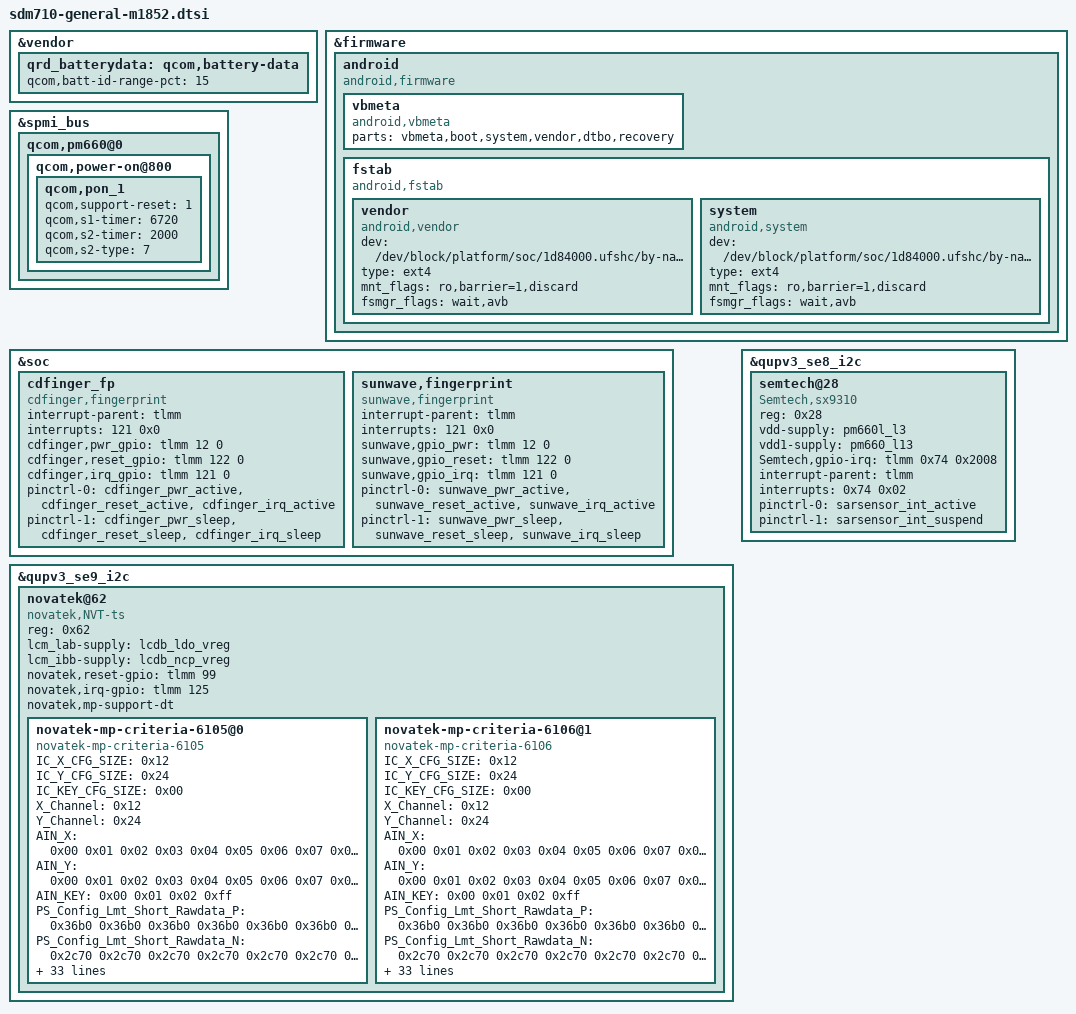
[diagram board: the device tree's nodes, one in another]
/* Copyright (c) 2017, The Linux Foundation. All rights reserved.
 * Copyright (C) 2020 Meizu, Inc.
 *
 * This program is free software; you can redistribute it and/or modify
 * it under the terms of the GNU General Public License version 2 and
 * only version 2 as published by the Free Software Foundation.
 *
 * This program is distributed in the hope that it will be useful,
 * but WITHOUT ANY WARRANTY; without even the implied warranty of
 * MERCHANTABILITY or FITNESS FOR A PARTICULAR PURPOSE.  See the
 * GNU General Public License for more details.
 */

&vendor {
	qrd_batterydata: qcom,battery-data {
		qcom,batt-id-range-pct = <15>;
		#include "batterydata-huaqin-ql1898-3210mah.dtsi"
		#include "batterydata-huaqin-ql1898-atl-3210mah.dtsi"
    }
};

&firmware {
    android {
        compatible = "android,firmware";

        vbmeta {
            compatible = "android,vbmeta";
            parts = "vbmeta,boot,system,vendor,dtbo,recovery";
        };

        fstab {
            compatible = "android,fstab";

            vendor {
                compatible = "android,vendor";
                dev = "/dev/block/platform/soc/1d84000.ufshc/by-name/vendor";
                type = "ext4";
                mnt_flags = "ro,barrier=1,discard";
                fsmgr_flags = "wait,avb";
            };

            system {
                compatible = "android,system";
                dev = "/dev/block/platform/soc/1d84000.ufshc/by-name/system";
                type = "ext4";
                mnt_flags = "ro,barrier=1,discard";
                fsmgr_flags = "wait,avb";
            };
        };
	};
}

&spmi_bus {
    qcom,pm660@0 {
        qcom,power-on@800 {
            qcom,pon_1 {
				qcom,support-reset = <1>;
				qcom,s1-timer = <6720>;
				qcom,s2-timer = <2000>;
				qcom,s2-type = <7>;
			};
        }
    }
}

&soc {
    cdfinger_fp {
        compatible = "cdfinger,fingerprint";
        interrupt-parent = <&tlmm>;
        interrupts = <121 0x0>;
        cdfinger,pwr_gpio = <&tlmm 12 0>;
        cdfinger,reset_gpio = <&tlmm 122 0>;
        cdfinger,irq_gpio = <&tlmm 121 0>;
        pinctrl-names = "cdfinger_active", "cdfinger_sleep";
        pinctrl-0 = <&cdfinger_pwr_active &cdfinger_reset_active &cdfinger_irq_active>;
        pinctrl-1 = <&cdfinger_pwr_sleep &cdfinger_reset_sleep &cdfinger_irq_sleep>;
    };

    sunwave,fingerprint {
        compatible = "sunwave,fingerprint";
        interrupt-parent = <&tlmm>;
        interrupts = <121 0x0>;
        sunwave,gpio_pwr = <&tlmm 12 0>;
        sunwave,gpio_reset = <&tlmm 122 0>;
        sunwave,gpio_irq = <&tlmm 121 0>;
        pinctrl-names = "sunwave_active", "sunwave_sleep";
        pinctrl-0 = <&sunwave_pwr_active &sunwave_reset_active &sunwave_irq_active>;
        pinctrl-1 = <&sunwave_pwr_sleep &sunwave_reset_sleep &sunwave_irq_sleep>;
	};
}

&qupv3_se9_i2c {
    status = "ok";
    novatek@62 {
            compatible = "novatek,NVT-ts";
            reg = <0x62>;
            status = "ok";
            lcm_lab-supply = <&lcdb_ldo_vreg>;
            lcm_ibb-supply = <&lcdb_ncp_vreg>;
            novatek,reset-gpio = <&tlmm 99 0>;
            novatek,irq-gpio = <&tlmm 125 0>;
            novatek,mp-support-dt;

            novatek-mp-criteria-6105@0 {
                #address-cells = <0x01>;
                #size-cells = <0x00>;
                compatible = "novatek-mp-criteria-6105";
                IC_X_CFG_SIZE = <0x12>;
                IC_Y_CFG_SIZE = <0x24>;
                IC_KEY_CFG_SIZE = <0x00>;
                X_Channel = <0x12>;
                Y_Channel = <0x24>;
                AIN_X = <0x00 0x01 0x02 0x03 0x04 0x05 0x06 0x07 0x08 0x09 0x0a 0x0b 0x0c 0x0d 0x0e 0x0f 0x10 0x11>;
                AIN_Y = <0x00 0x01 0x02 0x03 0x04 0x05 0x06 0x07 0x08 0x09 0x0a 0x0b 0x0c 0x0d 0x0e 0x0f 0x10 0x11 0x12 0x13 0x14 0x15 0x16 0x17 0x18 0x19 0x1a 0x1b 0x1c 0x1d 0x1e 0x1f 0x20 0x21 0x22 0x23>;
                AIN_KEY = <0x00 0x01 0x02 0xff>;
                PS_Config_Lmt_Short_Rawdata_P = <0x36b0 0x36b0 0x36b0 0x36b0 0x36b0 0x36b0 0x36b0 0x36b0 0x36b0 0x36b0 0x36b0 0x36b0 0x36b0 0x36b0 0x36b0 0x36b0 0x36b0 0x36b0 0x36b0 0x36b0 0x36b0 0x36b0 0x36b0 0x36b0 0x36b0 0x36b0 0x36b0 0x36b0 0x36b0 0x36b0 0x36b0 0x36b0 0x36b0 0x36b0 0x36b0 0x36b0 0x36b0 0x36b0 0x36b0 0x36b0 0x36b0 0x36b0 0x36b0 0x36b0 0x36b0 0x36b0 0x36b0 0x36b0 0x36b0 0x36b0 0x36b0 0x36b0 0x36b0 0x36b0 0x36b0 0x36b0 0x36b0 0x36b0 0x36b0 0x36b0 0x36b0 0x36b0 0x36b0 0x36b0 0x36b0 0x36b0 0x36b0 0x36b0 0x36b0 0x36b0 0x36b0 0x36b0 0x36b0 0x36b0 0x36b0 0x36b0 0x36b0 0x36b0 0x36b0 0x36b0 0x36b0 0x36b0 0x36b0 0x36b0 0x36b0 0x36b0 0x36b0 0x36b0 0x36b0 0x36b0 0x36b0 0x36b0 0x36b0 0x36b0 0x36b0 0x36b0 0x36b0 0x36b0 0x36b0 0x36b0 0x36b0 0x36b0 0x36b0 0x36b0 0x36b0 0x36b0 0x36b0 0x36b0 0x36b0 0x36b0 0x36b0 0x36b0 0x36b0 0x36b0 0x36b0 0x36b0 0x36b0 0x36b0 0x36b0 0x36b0 0x36b0 0x36b0 0x36b0 0x36b0 0x36b0 0x36b0 0x36b0 0x36b0 0x36b0 0x36b0 0x36b0 0x36b0 0x36b0 0x36b0 0x36b0 0x36b0 0x36b0 0x36b0 0x36b0 0x36b0 0x36b0 0x36b0 0x36b0 0x36b0 0x36b0 0x36b0 0x36b0 0x36b0 0x36b0 0x36b0 0x36b0 0x36b0 0x36b0 0x36b0 0x36b0 0x36b0 0x36b0 0x36b0 0x36b0 0x36b0 0x36b0 0x36b0 0x36b0 0x36b0 0x36b0 0x36b0 0x36b0 0x36b0 0x36b0 0x36b0 0x36b0 0x36b0 0x36b0 0x36b0 0x36b0 0x36b0 0x36b0 0x36b0 0x36b0 0x36b0 0x36b0 0x36b0 0x36b0 0x36b0 0x36b0 0x36b0 0x36b0 0x36b0 0x36b0 0x36b0 0x36b0 0x36b0 0x36b0 0x36b0 0x36b0 0x36b0 0x36b0 0x36b0 0x36b0 0x36b0 0x36b0 0x36b0 0x36b0 0x36b0 0x36b0 0x36b0 0x36b0 0x36b0 0x36b0 0x36b0 0x36b0 0x36b0 0x36b0 0x36b0 0x36b0 0x36b0 0x36b0 0x36b0 0x36b0 0x36b0 0x36b0 0x36b0 0x36b0 0x36b0 0x36b0 0x36b0 0x36b0 0x36b0 0x36b0 0x36b0 0x36b0 0x36b0 0x36b0 0x36b0 0x36b0 0x36b0 0x36b0 0x36b0 0x36b0 0x36b0 0x36b0 0x36b0 0x36b0 0x36b0 0x36b0 0x36b0 0x36b0 0x36b0 0x36b0 0x36b0 0x36b0 0x36b0 0x36b0 0x36b0 0x36b0 0x36b0 0x36b0 0x36b0 0x36b0 0x36b0 0x36b0 0x36b0 0x36b0 0x36b0 0x36b0 0x36b0 0x36b0 0x36b0 0x36b0 0x36b0 0x36b0 0x36b0 0x36b0 0x36b0 0x36b0 0x36b0 0x36b0 0x36b0 0x36b0 0x36b0 0x36b0 0x36b0 0x36b0 0x36b0 0x36b0 0x36b0 0x36b0 0x36b0 0x36b0 0x36b0 0x36b0 0x36b0 0x36b0 0x36b0 0x36b0 0x36b0 0x36b0 0x36b0 0x36b0 0x36b0 0x36b0 0x36b0 0x36b0 0x36b0 0x36b0 0x36b0 0x36b0 0x36b0 0x36b0 0x36b0 0x36b0 0x36b0 0x36b0 0x36b0 0x36b0 0x36b0 0x36b0 0x36b0 0x36b0 0x36b0 0x36b0 0x36b0 0x36b0 0x36b0 0x36b0 0x36b0 0x36b0 0x36b0 0x36b0 0x36b0 0x36b0 0x36b0 0x36b0 0x36b0 0x36b0 0x36b0 0x36b0 0x36b0 0x36b0 0x36b0 0x36b0 0x36b0 0x36b0 0x36b0 0x36b0 0x36b0 0x36b0 0x36b0 0x36b0 0x36b0 0x36b0 0x36b0 0x36b0 0x36b0 0x36b0 0x36b0 0x36b0 0x36b0 0x36b0 0x36b0 0x36b0 0x36b0 0x36b0 0x36b0 0x36b0 0x36b0 0x36b0 0x36b0 0x36b0 0x36b0 0x36b0 0x36b0 0x36b0 0x36b0 0x36b0 0x36b0 0x36b0 0x36b0 0x36b0 0x36b0 0x36b0 0x36b0 0x36b0 0x36b0 0x36b0 0x36b0 0x36b0 0x36b0 0x36b0 0x36b0 0x36b0 0x36b0 0x36b0 0x36b0 0x36b0 0x36b0 0x36b0 0x36b0 0x36b0 0x36b0 0x36b0 0x36b0 0x36b0 0x36b0 0x36b0 0x36b0 0x36b0 0x36b0 0x36b0 0x36b0 0x36b0 0x36b0 0x36b0 0x36b0 0x36b0 0x36b0 0x36b0 0x36b0 0x36b0 0x36b0 0x36b0 0x36b0 0x36b0 0x36b0 0x36b0 0x36b0 0x36b0 0x36b0 0x36b0 0x36b0 0x36b0 0x36b0 0x36b0 0x36b0 0x36b0 0x36b0 0x36b0 0x36b0 0x36b0 0x36b0 0x36b0 0x36b0 0x36b0 0x36b0 0x36b0 0x36b0 0x36b0 0x36b0 0x36b0 0x36b0 0x36b0 0x36b0 0x36b0 0x36b0 0x36b0 0x36b0 0x36b0 0x36b0 0x36b0 0x36b0 0x36b0 0x36b0 0x36b0 0x36b0 0x36b0 0x36b0 0x36b0 0x36b0 0x36b0 0x36b0 0x36b0 0x36b0 0x36b0 0x36b0 0x36b0 0x36b0 0x36b0 0x36b0 0x36b0 0x36b0 0x36b0 0x36b0 0x36b0 0x36b0 0x36b0 0x36b0 0x36b0 0x36b0 0x36b0 0x36b0 0x36b0 0x36b0 0x36b0 0x36b0 0x36b0 0x36b0 0x36b0 0x36b0 0x36b0 0x36b0 0x36b0 0x36b0 0x36b0 0x36b0 0x36b0 0x36b0 0x36b0 0x36b0 0x36b0 0x36b0 0x36b0 0x36b0 0x36b0 0x36b0 0x36b0 0x36b0 0x36b0 0x36b0 0x36b0 0x36b0 0x36b0 0x36b0 0x36b0 0x36b0 0x36b0 0x36b0 0x36b0 0x36b0 0x36b0 0x36b0 0x36b0 0x36b0 0x36b0 0x36b0 0x36b0 0x36b0 0x36b0 0x36b0 0x36b0 0x36b0 0x36b0 0x36b0 0x36b0 0x36b0 0x36b0 0x36b0 0x36b0 0x36b0 0x36b0 0x36b0 0x36b0 0x36b0 0x36b0 0x36b0 0x36b0 0x36b0 0x36b0 0x36b0 0x36b0 0x36b0 0x36b0 0x36b0 0x36b0 0x36b0 0x36b0 0x36b0 0x36b0 0x36b0 0x36b0 0x36b0 0x36b0 0x36b0 0x36b0 0x36b0 0x36b0 0x36b0 0x36b0 0x36b0 0x36b0 0x36b0 0x36b0 0x36b0 0x36b0 0x36b0 0x36b0 0x36b0 0x36b0 0x36b0 0x36b0 0x36b0 0x36b0 0x36b0 0x36b0 0x36b0 0x36b0 0x36b0 0x36b0 0x36b0 0x36b0 0x36b0 0x36b0 0x36b0 0x36b0 0x36b0 0x36b0 0x36b0 0x36b0 0x36b0 0x36b0 0x36b0 0x36b0 0x36b0 0x36b0 0x36b0 0x36b0 0x36b0 0x36b0 0x36b0 0x36b0 0x36b0 0x36b0 0x36b0 0x36b0 0x36b0 0x36b0 0x36b0 0x36b0 0x36b0 0x36b0 0x36b0 0x36b0 0x36b0 0x36b0 0x36b0 0x36b0 0x36b0 0x36b0 0x36b0 0x36b0 0x36b0 0x36b0 0x36b0 0x36b0 0x36b0 0x36b0 0x36b0 0x36b0 0x36b0 0x4e20 0x4e20 0x4e20>;
                PS_Config_Lmt_Short_Rawdata_N = <0x2c70 0x2c70 0x2c70 0x2c70 0x2c70 0x2c70 0x2c70 0x2c70 0x2c70 0x2c70 0x2c70 0x2c70 0x2c70 0x2c70 0x2c70 0x2c70 0x2c70 0x2c70 0x2c70 0x2c70 0x2c70 0x2c70 0x2c70 0x2c70 0x2c70 0x2c70 0x2c70 0x2c70 0x2c70 0x2c70 0x2c70 0x2c70 0x2c70 0x2c70 0x2c70 0x2c70 0x2c70 0x2c70 0x2c70 0x2c70 0x2c70 0x2c70 0x2c70 0x2c70 0x2c70 0x2c70 0x2c70 0x2c70 0x2c70 0x2c70 0x2c70 0x2c70 0x2c70 0x2c70 0x2c70 0x2c70 0x2c70 0x2c70 0x2c70 0x2c70 0x2c70 0x2c70 0x2c70 0x2c70 0x2c70 0x2c70 0x2c70 0x2c70 0x2c70 0x2c70 0x2c70 0x2c70 0x2c70 0x2c70 0x2c70 0x2c70 0x2c70 0x2c70 0x2c70 0x2c70 0x2c70 0x2c70 0x2c70 0x2c70 0x2c70 0x2c70 0x2c70 0x2c70 0x2c70 0x2c70 0x2c70 0x2c70 0x2c70 0x2c70 0x2c70 0x2c70 0x2c70 0x2c70 0x2c70 0x2c70 0x2c70 0x2c70 0x2c70 0x2c70 0x2c70 0x2c70 0x2c70 0x2c70 0x2c70 0x2c70 0x2c70 0x2c70 0x2c70 0x2c70 0x2c70 0x2c70 0x2c70 0x2c70 0x2c70 0x2c70 0x2c70 0x2c70 0x2c70 0x2c70 0x2c70 0x2c70 0x2c70 0x2c70 0x2c70 0x2c70 0x2c70 0x2c70 0x2c70 0x2c70 0x2c70 0x2c70 0x2c70 0x2c70 0x2c70 0x2c70 0x2c70 0x2c70 0x2c70 0x2c70 0x2c70 0x2c70 0x2c70 0x2c70 0x2c70 0x2c70 0x2c70 0x2c70 0x2c70 0x2c70 0x2c70 0x2c70 0x2c70 0x2c70 0x2c70 0x2c70 0x2c70 0x2c70 0x2c70 0x2c70 0x2c70 0x2c70 0x2c70 0x2c70 0x2c70 0x2c70 0x2c70 0x2c70 0x2c70 0x2c70 0x2c70 0x2c70 0x2c70 0x2c70 0x2c70 0x2c70 0x2c70 0x2c70 0x2c70 0x2c70 0x2c70 0x2c70 0x2c70 0x2c70 0x2c70 0x2c70 0x2c70 0x2c70 0x2c70 0x2c70 0x2c70 0x2c70 0x2c70 0x2c70 0x2c70 0x2c70 0x2c70 0x2c70 0x2c70 0x2c70 0x2c70 0x2c70 0x2c70 0x2c70 0x2c70 0x2c70 0x2c70 0x2c70 0x2c70 0x2c70 0x2c70 0x2c70 0x2c70 0x2c70 0x2c70 0x2c70 0x2c70 0x2c70 0x2c70 0x2c70 0x2c70 0x2c70 0x2c70 0x2c70 0x2c70 0x2c70 0x2c70 0x2c70 0x2c70 0x2c70 0x2c70 0x2c70 0x2c70 0x2c70 0x2c70 0x2c70 0x2c70 0x2c70 0x2c70 0x2c70 0x2c70 0x2c70 0x2c70 0x2c70 0x2c70 0x2c70 0x2c70 0x2c70 0x2c70 0x2c70 0x2c70 0x2c70 0x2c70 0x2c70 0x2c70 0x2c70 0x2c70 0x2c70 0x2c70 0x2c70 0x2c70 0x2c70 0x2c70 0x2c70 0x2c70 0x2c70 0x2c70 0x2c70 0x2c70 0x2c70 0x2c70 0x2c70 0x2c70 0x2c70 0x2c70 0x2c70 0x2c70 0x2c70 0x2c70 0x2c70 0x2c70 0x2c70 0x2c70 0x2c70 0x2c70 0x2c70 0x2c70 0x2c70 0x2c70 0x2c70 0x2c70 0x2c70 0x2c70 0x2c70 0x2c70 0x2c70 0x2c70 0x2c70 0x2c70 0x2c70 0x2c70 0x2c70 0x2c70 0x2c70 0x2c70 0x2c70 0x2c70 0x2c70 0x2c70 0x2c70 0x2c70 0x2c70 0x2c70 0x2c70 0x2c70 0x2c70 0x2c70 0x2c70 0x2c70 0x2c70 0x2c70 0x2c70 0x2c70 0x2c70 0x2c70 0x2c70 0x2c70 0x2c70 0x2c70 0x2c70 0x2c70 0x2c70 0x2c70 0x2c70 0x2c70 0x2c70 0x2c70 0x2c70 0x2c70 0x2c70 0x2c70 0x2c70 0x2c70 0x2c70 0x2c70 0x2c70 0x2c70 0x2c70 0x2c70 0x2c70 0x2c70 0x2c70 0x2c70 0x2c70 0x2c70 0x2c70 0x2c70 0x2c70 0x2c70 0x2c70 0x2c70 0x2c70 0x2c70 0x2c70 0x2c70 0x2c70 0x2c70 0x2c70 0x2c70 0x2c70 0x2c70 0x2c70 0x2c70 0x2c70 0x2c70 0x2c70 0x2c70 0x2c70 0x2c70 0x2c70 0x2c70 0x2c70 0x2c70 0x2c70 0x2c70 0x2c70 0x2c70 0x2c70 0x2c70 0x2c70 0x2c70 0x2c70 0x2c70 0x2c70 0x2c70 0x2c70 0x2c70 0x2c70 0x2c70 0x2c70 0x2c70 0x2c70 0x2c70 0x2c70 0x2c70 0x2c70 0x2c70 0x2c70 0x2c70 0x2c70 0x2c70 0x2c70 0x2c70 0x2c70 0x2c70 0x2c70 0x2c70 0x2c70 0x2c70 0x2c70 0x2c70 0x2c70 0x2c70 0x2c70 0x2c70 0x2c70 0x2c70 0x2c70 0x2c70 0x2c70 0x2c70 0x2c70 0x2c70 0x2c70 0x2c70 0x2c70 0x2c70 0x2c70 0x2c70 0x2c70 0x2c70 0x2c70 0x2c70 0x2c70 0x2c70 0x2c70 0x2c70 0x2c70 0x2c70 0x2c70 0x2c70 0x2c70 0x2c70 0x2c70 0x2c70 0x2c70 0x2c70 0x2c70 0x2c70 0x2c70 0x2c70 0x2c70 0x2c70 0x2c70 0x2c70 0x2c70 0x2c70 0x2c70 0x2c70 0x2c70 0x2c70 0x2c70 0x2c70 0x2c70 0x2c70 0x2c70 0x2c70 0x2c70 0x2c70 0x2c70 0x2c70 0x2c70 0x2c70 0x2c70 0x2c70 0x2c70 0x2c70 0x2c70 0x2c70 0x2c70 0x2c70 0x2c70 0x2c70 0x2c70 0x2c70 0x2c70 0x2c70 0x2c70 0x2c70 0x2c70 0x2c70 0x2c70 0x2c70 0x2c70 0x2c70 0x2c70 0x2c70 0x2c70 0x2c70 0x2c70 0x2c70 0x2c70 0x2c70 0x2c70 0x2c70 0x2c70 0x2c70 0x2c70 0x2c70 0x2c70 0x2c70 0x2c70 0x2c70 0x2c70 0x2c70 0x2c70 0x2c70 0x2c70 0x2c70 0x2c70 0x2c70 0x2c70 0x2c70 0x2c70 0x2c70 0x2c70 0x2c70 0x2c70 0x2c70 0x2c70 0x2c70 0x2c70 0x2c70 0x2c70 0x2c70 0x2c70 0x2c70 0x2c70 0x2c70 0x2c70 0x2c70 0x2c70 0x2c70 0x2c70 0x2c70 0x2c70 0x2c70 0x2c70 0x2c70 0x2c70 0x2c70 0x2c70 0x2c70 0x2c70 0x2c70 0x2c70 0x2c70 0x2c70 0x2c70 0x2c70 0x2c70 0x2c70 0x2c70 0x2c70 0x2c70 0x2c70 0x2c70 0x2c70 0x2c70 0x2c70 0x2c70 0x2c70 0x2c70 0x2c70 0x2c70 0x2c70 0x2c70 0x2c70 0x2c70 0x2c70 0x2c70 0x2c70 0x2c70 0x2c70 0x2c70 0x2c70 0x2c70 0x2c70 0x2c70 0x2c70 0x2c70 0x2c70 0x2c70 0x2c70 0x2c70 0x2c70 0x2c70 0x2c70 0x2c70 0x2c70 0x2c70 0x2c70 0x2c70 0x2c70 0x2c70 0x2c70 0x2c70 0x2c70 0x2c70 0x2c70 0x2c70 0x2c70 0x2c70 0x2c70 0x2c70 0x2c70 0x2c70 0x2c70 0x2c70 0x2c70 0x2c70 0x2c70 0x2c70 0x2c70 0x2c70 0x2c70 0x2c70 0x2c70 0x2c70 0x2c70 0x2c70 0x2c70 0x2c70 0x2c70 0x2d1e 0x2d1e 0x2d1e>;
                PS_Config_Lmt_Short_Diff_P = <0x189c 0x189c 0x189c 0x189c 0x189c 0x189c 0x189c 0x189c 0x189c 0x189c 0x189c 0x189c 0x189c 0x189c 0x189c 0x189c 0x189c 0x189c 0x189c 0x189c 0x189c 0x189c 0x189c 0x189c 0x189c 0x189c 0x189c 0x189c 0x189c 0x189c 0x189c 0x189c 0x189c 0x189c 0x189c 0x189c 0x189c 0x189c 0x189c 0x189c 0x189c 0x189c 0x189c 0x189c 0x189c 0x189c 0x189c 0x189c 0x189c 0x189c 0x189c 0x189c 0x189c 0x189c 0x189c 0x189c 0x189c 0x189c 0x189c 0x189c 0x189c 0x189c 0x189c 0x189c 0x189c 0x189c 0x189c 0x189c 0x189c 0x189c 0x189c 0x189c 0x189c 0x189c 0x189c 0x189c 0x189c 0x189c 0x189c 0x189c 0x189c 0x189c 0x189c 0x189c 0x189c 0x189c 0x189c 0x189c 0x189c 0x189c 0x189c 0x189c 0x189c 0x189c 0x189c 0x189c 0x189c 0x189c 0x189c 0x189c 0x189c 0x189c 0x189c 0x189c 0x189c 0x189c 0x189c 0x189c 0x189c 0x189c 0x189c 0x189c 0x189c 0x189c 0x189c 0x189c 0x189c 0x189c 0x189c 0x189c 0x189c 0x189c 0x189c 0x189c 0x189c 0x189c 0x189c 0x189c 0x189c 0x189c 0x189c 0x189c 0x189c 0x189c 0x189c 0x189c 0x189c 0x189c 0x189c 0x189c 0x189c 0x189c 0x189c 0x189c 0x189c 0x189c 0x189c 0x189c 0x189c 0x189c 0x189c 0x189c 0x189c 0x189c 0x189c 0x189c 0x189c 0x189c 0x189c 0x189c 0x189c 0x189c 0x189c 0x189c 0x189c 0x189c 0x189c 0x189c 0x189c 0x189c 0x189c 0x189c 0x189c 0x189c 0x189c 0x189c 0x189c 0x189c 0x189c 0x189c 0x189c 0x189c 0x189c 0x189c 0x189c 0x189c 0x189c 0x189c 0x189c 0x189c 0x189c 0x189c 0x189c 0x189c 0x189c 0x189c 0x189c 0x189c 0x189c 0x189c 0x189c 0x189c 0x189c 0x189c 0x189c 0x189c 0x189c 0x189c 0x189c 0x189c 0x189c 0x189c 0x189c 0x189c 0x189c 0x189c 0x189c 0x189c 0x189c 0x189c 0x189c 0x189c 0x189c 0x189c 0x189c 0x189c 0x189c 0x189c 0x189c 0x189c 0x189c 0x189c 0x189c 0x189c 0x189c 0x189c 0x189c 0x189c 0x189c 0x189c 0x189c 0x189c 0x189c 0x189c 0x189c 0x189c 0x189c 0x189c 0x189c 0x189c 0x189c 0x189c 0x189c 0x189c 0x189c 0x189c 0x189c 0x189c 0x189c 0x189c 0x189c 0x189c 0x189c 0x189c 0x189c 0x189c 0x189c 0x189c 0x189c 0x189c 0x189c 0x189c 0x189c 0x189c 0x189c 0x189c 0x189c 0x189c 0x189c 0x189c 0x189c 0x189c 0x189c 0x189c 0x189c 0x189c 0x189c 0x189c 0x189c 0x189c 0x189c 0x189c 0x189c 0x189c 0x189c 0x189c 0x189c 0x189c 0x189c 0x189c 0x189c 0x189c 0x189c 0x189c 0x189c 0x189c 0x189c 0x189c 0x189c 0x189c 0x189c 0x189c 0x189c 0x189c 0x189c 0x189c 0x189c 0x189c 0x189c 0x189c 0x189c 0x189c 0x189c 0x189c 0x189c 0x189c 0x189c 0x189c 0x189c 0x189c 0x189c 0x189c 0x189c 0x189c 0x189c 0x189c 0x189c 0x189c 0x189c 0x189c 0x189c 0x189c 0x189c 0x189c 0x189c 0x189c 0x189c 0x189c 0x189c 0x189c 0x189c 0x189c 0x189c 0x189c 0x189c 0x189c 0x189c 0x189c 0x189c 0x189c 0x189c 0x189c 0x189c 0x189c 0x189c 0x189c 0x189c 0x189c 0x189c 0x189c 0x189c 0x189c 0x189c 0x189c 0x189c 0x189c 0x189c 0x189c 0x189c 0x189c 0x189c 0x189c 0x189c 0x189c 0x189c 0x189c 0x189c 0x189c 0x189c 0x189c 0x189c 0x189c 0x189c 0x189c 0x189c 0x189c 0x189c 0x189c 0x189c 0x189c 0x189c 0x189c 0x189c 0x189c 0x189c 0x189c 0x189c 0x189c 0x189c 0x189c 0x189c 0x189c 0x189c 0x189c 0x189c 0x189c 0x189c 0x189c 0x189c 0x189c 0x189c 0x189c 0x189c 0x189c 0x189c 0x189c 0x189c 0x189c 0x189c 0x189c 0x189c 0x189c 0x189c 0x189c 0x189c 0x189c 0x189c 0x189c 0x189c 0x189c 0x189c 0x189c 0x189c 0x189c 0x189c 0x189c 0x189c 0x189c 0x189c 0x189c 0x189c 0x189c 0x189c 0x189c 0x189c 0x189c 0x189c 0x189c 0x189c 0x189c 0x189c 0x189c 0x189c 0x189c 0x189c 0x189c 0x189c 0x189c 0x189c 0x189c 0x189c 0x189c 0x189c 0x189c 0x189c 0x189c 0x189c 0x189c 0x189c 0x189c 0x189c 0x189c 0x189c 0x189c 0x189c 0x189c 0x189c 0x189c 0x189c 0x189c 0x189c 0x189c 0x189c 0x189c 0x189c 0x189c 0x189c 0x189c 0x189c 0x189c 0x189c 0x189c 0x189c 0x189c 0x189c 0x189c 0x189c 0x189c 0x189c 0x189c 0x189c 0x189c 0x189c 0x189c 0x189c 0x189c 0x189c 0x189c 0x189c 0x189c 0x189c 0x189c 0x189c 0x189c 0x189c 0x189c 0x189c 0x189c 0x189c 0x189c 0x189c 0x189c 0x189c 0x189c 0x189c 0x189c 0x189c 0x189c 0x189c 0x189c 0x189c 0x189c 0x189c 0x189c 0x189c 0x189c 0x189c 0x189c 0x189c 0x189c 0x189c 0x189c 0x189c 0x189c 0x189c 0x189c 0x189c 0x189c 0x189c 0x189c 0x189c 0x189c 0x189c 0x189c 0x189c 0x189c 0x189c 0x189c 0x189c 0x189c 0x189c 0x189c 0x189c 0x189c 0x189c 0x189c 0x189c 0x189c 0x189c>;
                PS_Config_Lmt_Short_Diff_N = <0x00 0x00 0x00 0x00 0x00 0x00 0x00 0x00 0x00 0x00 0x00 0x00 0x00 0x00 0x00 0x00 0x00 0x00 0x00 0x00 0x00 0x00 0x00 0x00 0x00 0x00 0x00 0x00 0x00 0x00 0x00 0x00 0x00 0x00 0x00 0x00 0x00 0x00 0x00 0x00 0x00 0x00 0x00 0x00 0x00 0x00 0x00 0x00 0x00 0x00 0x00 0x00 0x00 0x00 0x00 0x00 0x00 0x00 0x00 0x00 0x00 0x00 0x00 0x00 0x00 0x00 0x00 0x00 0x00 0x00 0x00 0x00 0x00 0x00 0x00 0x00 0x00 0x00 0x00 0x00 0x00 0x00 0x00 0x00 0x00 0x00 0x00 0x00 0x00 0x00 0x00 0x00 0x00 0x00 0x00 0x00 0x00 0x00 0x00 0x00 0x00 0x00 0x00 0x00 0x00 0x00 0x00 0x00 0x00 0x00 0x00 0x00 0x00 0x00 0x00 0x00 0x00 0x00 0x00 0x00 0x00 0x00 0x00 0x00 0x00 0x00 0x00 0x00 0x00 0x00 0x00 0x00 0x00 0x00 0x00 0x00 0x00 0x00 0x00 0x00 0x00 0x00 0x00 0x00 0x00 0x00 0x00 0x00 0x00 0x00 0x00 0x00 0x00 0x00 0x00 0x00 0x00 0x00 0x00 0x00 0x00 0x00 0x00 0x00 0x00 0x00 0x00 0x00 0x00 0x00 0x00 0x00 0x00 0x00 0x00 0x00 0x00 0x00 0x00 0x00 0x00 0x00 0x00 0x00 0x00 0x00 0x00 0x00 0x00 0x00 0x00 0x00 0x00 0x00 0x00 0x00 0x00 0x00 0x00 0x00 0x00 0x00 0x00 0x00 0x00 0x00 0x00 0x00 0x00 0x00 0x00 0x00 0x00 0x00 0x00 0x00 0x00 0x00 0x00 0x00 0x00 0x00 0x00 0x00 0x00 0x00 0x00 0x00 0x00 0x00 0x00 0x00 0x00 0x00 0x00 0x00 0x00 0x00 0x00 0x00 0x00 0x00 0x00 0x00 0x00 0x00 0x00 0x00 0x00 0x00 0x00 0x00 0x00 0x00 0x00 0x00 0x00 0x00 0x00 0x00 0x00 0x00 0x00 0x00 0x00 0x00 0x00 0x00 0x00 0x00 0x00 0x00 0x00 0x00 0x00 0x00 0x00 0x00 0x00 0x00 0x00 0x00 0x00 0x00 0x00 0x00 0x00 0x00 0x00 0x00 0x00 0x00 0x00 0x00 0x00 0x00 0x00 0x00 0x00 0x00 0x00 0x00 0x00 0x00 0x00 0x00 0x00 0x00 0x00 0x00 0x00 0x00 0x00 0x00 0x00 0x00 0x00 0x00 0x00 0x00 0x00 0x00 0x00 0x00 0x00 0x00 0x00 0x00 0x00 0x00 0x00 0x00 0x00 0x00 0x00 0x00 0x00 0x00 0x00 0x00 0x00 0x00 0x00 0x00 0x00 0x00 0x00 0x00 0x00 0x00 0x00 0x00 0x00 0x00 0x00 0x00 0x00 0x00 0x00 0x00 0x00 0x00 0x00 0x00 0x00 0x00 0x00 0x00 0x00 0x00 0x00 0x00 0x00 0x00 0x00 0x00 0x00 0x00 0x00 0x00 0x00 0x00 0x00 0x00 0x00 0x00 0x00 0x00 0x00 0x00 0x00 0x00 0x00 0x00 0x00 0x00 0x00 0x00 0x00 0x00 0x00 0x00 0x00 0x00 0x00 0x00 0x00 0x00 0x00 0x00 0x00 0x00 0x00 0x00 0x00 0x00 0x00 0x00 0x00 0x00 0x00 0x00 0x00 0x00 0x00 0x00 0x00 0x00 0x00 0x00 0x00 0x00 0x00 0x00 0x00 0x00 0x00 0x00 0x00 0x00 0x00 0x00 0x00 0x00 0x00 0x00 0x00 0x00 0x00 0x00 0x00 0x00 0x00 0x00 0x00 0x00 0x00 0x00 0x00 0x00 0x00 0x00 0x00 0x00 0x00 0x00 0x00 0x00 0x00 0x00 0x00 0x00 0x00 0x00 0x00 0x00 0x00 0x00 0x00 0x00 0x00 0x00 0x00 0x00 0x00 0x00 0x00 0x00 0x00 0x00 0x00 0x00 0x00 0x00 0x00 0x00 0x00 0x00 0x00 0x00 0x00 0x00 0x00 0x00 0x00 0x00 0x00 0x00 0x00 0x00 0x00 0x00 0x00 0x00 0x00 0x00 0x00 0x00 0x00 0x00 0x00 0x00 0x00 0x00 0x00 0x00 0x00 0x00 0x00 0x00 0x00 0x00 0x00 0x00 0x00 0x00 0x00 0x00 0x00 0x00 0x00 0x00 0x00 0x00 0x00 0x00 0x00 0x00 0x00 0x00 0x00 0x00 0x00 0x00 0x00 0x00 0x00 0x00 0x00 0x00 0x00 0x00 0x00 0x00 0x00 0x00 0x00 0x00 0x00 0x00 0x00 0x00 0x00 0x00 0x00 0x00 0x00 0x00 0x00>;
                PS_Config_Lmt_Short_Base_P = <0x7d0 0x7d0 0x7d0 0x7d0 0x7d0 0x7d0 0x7d0 0x7d0 0x7d0 0x7d0 0x7d0 0x7d0 0x7d0 0x7d0 0x7d0 0x7d0 0x7d0 0x7d0 0x7d0 0x7d0 0x7d0 0x7d0 0x7d0 0x7d0 0x7d0 0x7d0 0x7d0 0x7d0 0x7d0 0x7d0 0x7d0 0x7d0 0x7d0 0x7d0 0x7d0 0x7d0 0x7d0 0x7d0 0x7d0 0x7d0 0x7d0 0x7d0 0x7d0 0x7d0 0x7d0 0x7d0 0x7d0 0x7d0 0x7d0 0x7d0 0x7d0 0x7d0 0x7d0 0x7d0 0x7d0 0x7d0 0x7d0 0x7d0 0x7d0 0x7d0 0x7d0 0x7d0 0x7d0 0x7d0 0x7d0 0x7d0 0x7d0 0x7d0 0x7d0 0x7d0 0x7d0 0x7d0 0x7d0 0x7d0 0x7d0 0x7d0 0x7d0 0x7d0 0x7d0 0x7d0 0x7d0 0x7d0 0x7d0 0x7d0 0x7d0 0x7d0 0x7d0 0x7d0 0x7d0 0x7d0 0x7d0 0x7d0 0x7d0 0x7d0 0x7d0 0x7d0 0x7d0 0x7d0 0x7d0 0x7d0 0x7d0 0x7d0 0x7d0 0x7d0 0x7d0 0x7d0 0x7d0 0x7d0 0x7d0 0x7d0 0x7d0 0x7d0 0x7d0 0x7d0 0x7d0 0x7d0 0x7d0 0x7d0 0x7d0 0x7d0 0x7d0 0x7d0 0x7d0 0x7d0 0x7d0 0x7d0 0x7d0 0x7d0 0x7d0 0x7d0 0x7d0 0x7d0 0x7d0 0x7d0 0x7d0 0x7d0 0x7d0 0x7d0 0x7d0 0x7d0 0x7d0 0x7d0 0x7d0 0x7d0 0x7d0 0x7d0 0x7d0 0x7d0 0x7d0 0x7d0 0x7d0 0x7d0 0x7d0 0x7d0 0x7d0 0x7d0 0x7d0 0x7d0 0x7d0 0x7d0 0x7d0 0x7d0 0x7d0 0x7d0 0x7d0 0x7d0 0x7d0 0x7d0 0x7d0 0x7d0 0x7d0 0x7d0 0x7d0 0x7d0 0x7d0 0x7d0 0x7d0 0x7d0 0x7d0 0x7d0 0x7d0 0x7d0 0x7d0 0x7d0 0x7d0 0x7d0 0x7d0 0x7d0 0x7d0 0x7d0 0x7d0 0x7d0 0x7d0 0x7d0 0x7d0 0x7d0 0x7d0 0x7d0 0x7d0 0x7d0 0x7d0 0x7d0 0x7d0 0x7d0 0x7d0 0x7d0 0x7d0 0x7d0 0x7d0 0x7d0 0x7d0 0x7d0 0x7d0 0x7d0 0x7d0 0x7d0 0x7d0 0x7d0 0x7d0 0x7d0 0x7d0 0x7d0 0x7d0 0x7d0 0x7d0 0x7d0 0x7d0 0x7d0 0x7d0 0x7d0 0x7d0 0x7d0 0x7d0 0x7d0 0x7d0 0x7d0 0x7d0 0x7d0 0x7d0 0x7d0 0x7d0 0x7d0 0x7d0 0x7d0 0x7d0 0x7d0 0x7d0 0x7d0 0x7d0 0x7d0 0x7d0 0x7d0 0x7d0 0x7d0 0x7d0 0x7d0 0x7d0 0x7d0 0x7d0 0x7d0 0x7d0 0x7d0 0x7d0 0x7d0 0x7d0 0x7d0 0x7d0 0x7d0 0x7d0 0x7d0 0x7d0 0x7d0 0x7d0 0x7d0 0x7d0 0x7d0 0x7d0 0x7d0 0x7d0 0x7d0 0x7d0 0x7d0 0x7d0 0x7d0 0x7d0 0x7d0 0x7d0 0x7d0 0x7d0 0x7d0 0x7d0 0x7d0 0x7d0 0x7d0 0x7d0 0x7d0 0x7d0 0x7d0 0x7d0 0x7d0 0x7d0 0x7d0 0x7d0 0x7d0 0x7d0 0x7d0 0x7d0 0x7d0 0x7d0 0x7d0 0x7d0 0x7d0 0x7d0 0x7d0 0x7d0 0x7d0 0x7d0 0x7d0 0x7d0 0x7d0 0x7d0 0x7d0 0x7d0 0x7d0 0x7d0 0x7d0 0x7d0 0x7d0 0x7d0 0x7d0 0x7d0 0x7d0 0x7d0 0x7d0 0x7d0 0x7d0 0x7d0 0x7d0 0x7d0 0x7d0 0x7d0 0x7d0 0x7d0 0x7d0 0x7d0 0x7d0 0x7d0 0x7d0 0x7d0 0x7d0 0x7d0 0x7d0 0x7d0 0x7d0 0x7d0 0x7d0 0x7d0 0x7d0 0x7d0 0x7d0 0x7d0 0x7d0 0x7d0 0x7d0 0x7d0 0x7d0 0x7d0 0x7d0 0x7d0 0x7d0 0x7d0 0x7d0 0x7d0 0x7d0 0x7d0 0x7d0 0x7d0 0x7d0 0x7d0 0x7d0 0x7d0 0x7d0 0x7d0 0x7d0 0x7d0 0x7d0 0x7d0 0x7d0 0x7d0 0x7d0 0x7d0 0x7d0 0x7d0 0x7d0 0x7d0 0x7d0 0x7d0 0x7d0 0x7d0 0x7d0 0x7d0 0x7d0 0x7d0 0x7d0 0x7d0 0x7d0 0x7d0 0x7d0 0x7d0 0x7d0 0x7d0 0x7d0 0x7d0 0x7d0 0x7d0 0x7d0 0x7d0 0x7d0 0x7d0 0x7d0 0x7d0 0x7d0 0x7d0 0x7d0 0x7d0 0x7d0 0x7d0 0x7d0 0x7d0 0x7d0 0x7d0 0x7d0 0x7d0 0x7d0 0x7d0 0x7d0 0x7d0 0x7d0 0x7d0 0x7d0 0x7d0 0x7d0 0x7d0 0x7d0 0x7d0 0x7d0 0x7d0 0x7d0 0x7d0 0x7d0 0x7d0 0x7d0 0x7d0 0x7d0 0x7d0 0x7d0 0x7d0 0x7d0 0x7d0 0x7d0 0x7d0 0x7d0 0x7d0 0x7d0 0x7d0 0x7d0 0x7d0 0x7d0 0x7d0 0x7d0 0x7d0 0x7d0 0x7d0 0x7d0 0x7d0 0x7d0 0x7d0 0x7d0 0x7d0 0x7d0 0x7d0 0x7d0 0x7d0 0x7d0 0x7d0 0x7d0 0x7d0 0x7d0 0x7d0 0x7d0 0x7d0 0x7d0 0x7d0 0x7d0 0x7d0 0x7d0 0x7d0 0x7d0 0x7d0 0x7d0 0x7d0 0x7d0 0x7d0 0x7d0 0x7d0 0x7d0 0x7d0 0x7d0 0x7d0 0x7d0 0x7d0 0x7d0 0x7d0 0x7d0 0x7d0 0x7d0 0x7d0 0x7d0 0x7d0 0x7d0 0x7d0 0x7d0 0x7d0 0x7d0 0x7d0 0x7d0 0x7d0 0x7d0 0x7d0 0x7d0 0x7d0 0x7d0 0x7d0 0x7d0 0x7d0 0x7d0 0x7d0 0x7d0 0x7d0 0x7d0 0x7d0 0x7d0 0x7d0 0x7d0 0x7d0 0x7d0 0x7d0 0x7d0 0x7d0 0x7d0 0x7d0 0x7d0 0x7d0 0x7d0 0x7d0 0x7d0 0x7d0 0x7d0 0x7d0 0x7d0 0x7d0 0x7d0 0x7d0 0x7d0 0x7d0 0x7d0 0x7d0 0x7d0 0x7d0 0x7d0 0x7d0 0x7d0 0x7d0 0x7d0 0x7d0 0x7d0 0x7d0 0x7d0 0x7d0>;
                PS_Config_Lmt_Short_Base_N = <0xfffff830 0xfffff830 0xfffff830 0xfffff830 0xfffff830 0xfffff830 0xfffff830 0xfffff830 0xfffff830 0xfffff830 0xfffff830 0xfffff830 0xfffff830 0xfffff830 0xfffff830 0xfffff830 0xfffff830 0xfffff830 0xfffff830 0xfffff830 0xfffff830 0xfffff830 0xfffff830 0xfffff830 0xfffff830 0xfffff830 0xfffff830 0xfffff830 0xfffff830 0xfffff830 0xfffff830 0xfffff830 0xfffff830 0xfffff830 0xfffff830 0xfffff830 0xfffff830 0xfffff830 0xfffff830 0xfffff830 0xfffff830 0xfffff830 0xfffff830 0xfffff830 0xfffff830 0xfffff830 0xfffff830 0xfffff830 0xfffff830 0xfffff830 0xfffff830 0xfffff830 0xfffff830 0xfffff830 0xfffff830 0xfffff830 0xfffff830 0xfffff830 0xfffff830 0xfffff830 0xfffff830 0xfffff830 0xfffff830 0xfffff830 0xfffff830 0xfffff830 0xfffff830 0xfffff830 0xfffff830 0xfffff830 0xfffff830 0xfffff830 0xfffff830 0xfffff830 0xfffff830 0xfffff830 0xfffff830 0xfffff830 0xfffff830 0xfffff830 0xfffff830 0xfffff830 0xfffff830 0xfffff830 0xfffff830 0xfffff830 0xfffff830 0xfffff830 0xfffff830 0xfffff830 0xfffff830 0xfffff830 0xfffff830 0xfffff830 0xfffff830 0xfffff830 0xfffff830 0xfffff830 0xfffff830 0xfffff830 0xfffff830 0xfffff830 0xfffff830 0xfffff830 0xfffff830 0xfffff830 0xfffff830 0xfffff830 0xfffff830 0xfffff830 0xfffff830 0xfffff830 0xfffff830 0xfffff830 0xfffff830 0xfffff830 0xfffff830 0xfffff830 0xfffff830 0xfffff830 0xfffff830 0xfffff830 0xfffff830 0xfffff830 0xfffff830 0xfffff830 0xfffff830 0xfffff830 0xfffff830 0xfffff830 0xfffff830 0xfffff830 0xfffff830 0xfffff830 0xfffff830 0xfffff830 0xfffff830 0xfffff830 0xfffff830 0xfffff830 0xfffff830 0xfffff830 0xfffff830 0xfffff830 0xfffff830 0xfffff830 0xfffff830 0xfffff830 0xfffff830 0xfffff830 0xfffff830 0xfffff830 0xfffff830 0xfffff830 0xfffff830 0xfffff830 0xfffff830 0xfffff830 0xfffff830 0xfffff830 0xfffff830 0xfffff830 0xfffff830 0xfffff830 0xfffff830 0xfffff830 0xfffff830 0xfffff830 0xfffff830 0xfffff830 0xfffff830 0xfffff830 0xfffff830 0xfffff830 0xfffff830 0xfffff830 0xfffff830 0xfffff830 0xfffff830 0xfffff830 0xfffff830 0xfffff830 0xfffff830 0xfffff830 0xfffff830 0xfffff830 0xfffff830 0xfffff830 0xfffff830 0xfffff830 0xfffff830 0xfffff830 0xfffff830 0xfffff830 0xfffff830 0xfffff830 0xfffff830 0xfffff830 0xfffff830 0xfffff830 0xfffff830 0xfffff830 0xfffff830 0xfffff830 0xfffff830 0xfffff830 0xfffff830 0xfffff830 0xfffff830 0xfffff830 0xfffff830 0xfffff830 0xfffff830 0xfffff830 0xfffff830 0xfffff830 0xfffff830 0xfffff830 0xfffff830 0xfffff830 0xfffff830 0xfffff830 0xfffff830 0xfffff830 0xfffff830 0xfffff830 0xfffff830 0xfffff830 0xfffff830 0xfffff830 0xfffff830 0xfffff830 0xfffff830 0xfffff830 0xfffff830 0xfffff830 0xfffff830 0xfffff830 0xfffff830 0xfffff830 0xfffff830 0xfffff830 0xfffff830 0xfffff830 0xfffff830 0xfffff830 0xfffff830 0xfffff830 0xfffff830 0xfffff830 0xfffff830 0xfffff830 0xfffff830 0xfffff830 0xfffff830 0xfffff830 0xfffff830 0xfffff830 0xfffff830 0xfffff830 0xfffff830 0xfffff830 0xfffff830 0xfffff830 0xfffff830 0xfffff830 0xfffff830 0xfffff830 0xfffff830 0xfffff830 0xfffff830 0xfffff830 0xfffff830 0xfffff830 0xfffff830 0xfffff830 0xfffff830 0xfffff830 0xfffff830 0xfffff830 0xfffff830 0xfffff830 0xfffff830 0xfffff830 0xfffff830 0xfffff830 0xfffff830 0xfffff830 0xfffff830 0xfffff830 0xfffff830 0xfffff830 0xfffff830 0xfffff830 0xfffff830 0xfffff830 0xfffff830 0xfffff830 0xfffff830 0xfffff830 0xfffff830 0xfffff830 0xfffff830 0xfffff830 0xfffff830 0xfffff830 0xfffff830 0xfffff830 0xfffff830 0xfffff830 0xfffff830 0xfffff830 0xfffff830 0xfffff830 0xfffff830 0xfffff830 0xfffff830 0xfffff830 0xfffff830 0xfffff830 0xfffff830 0xfffff830 0xfffff830 0xfffff830 0xfffff830 0xfffff830 0xfffff830 0xfffff830 0xfffff830 0xfffff830 0xfffff830 0xfffff830 0xfffff830 0xfffff830 0xfffff830 0xfffff830 0xfffff830 0xfffff830 0xfffff830 0xfffff830 0xfffff830 0xfffff830 0xfffff830 0xfffff830 0xfffff830 0xfffff830 0xfffff830 0xfffff830 0xfffff830 0xfffff830 0xfffff830 0xfffff830 0xfffff830 0xfffff830 0xfffff830 0xfffff830 0xfffff830 0xfffff830 0xfffff830 0xfffff830 0xfffff830 0xfffff830 0xfffff830 0xfffff830 0xfffff830 0xfffff830 0xfffff830 0xfffff830 0xfffff830 0xfffff830 0xfffff830 0xfffff830 0xfffff830 0xfffff830 0xfffff830 0xfffff830 0xfffff830 0xfffff830 0xfffff830 0xfffff830 0xfffff830 0xfffff830 0xfffff830 0xfffff830 0xfffff830 0xfffff830 0xfffff830 0xfffff830 0xfffff830 0xfffff830 0xfffff830 0xfffff830 0xfffff830 0xfffff830 0xfffff830 0xfffff830 0xfffff830 0xfffff830 0xfffff830 0xfffff830 0xfffff830 0xfffff830 0xfffff830 0xfffff830 0xfffff830 0xfffff830 0xfffff830 0xfffff830 0xfffff830 0xfffff830 0xfffff830 0xfffff830 0xfffff830 0xfffff830 0xfffff830 0xfffff830 0xfffff830 0xfffff830 0xfffff830 0xfffff830 0xfffff830 0xfffff830 0xfffff830 0xfffff830 0xfffff830 0xfffff830 0xfffff830 0xfffff830 0xfffff830 0xfffff830 0xfffff830 0xfffff830 0xfffff830 0xfffff830 0xfffff830 0xfffff830 0xfffff830 0xfffff830 0xfffff830 0xfffff830 0xfffff830 0xfffff830 0xfffff830 0xfffff830 0xfffff830 0xfffff830 0xfffff830 0xfffff830 0xfffff830 0xfffff830 0xfffff830 0xfffff830 0xfffff830 0xfffff830 0xfffff830 0xfffff830 0xfffff830 0xfffff830 0xfffff830 0xfffff830 0xfffff830 0xfffff830 0xfffff830 0xfffff830 0xfffff830 0xfffff830 0xfffff830 0xfffff830 0xfffff830 0xfffff830 0xfffff830 0xfffff830 0xfffff830 0xfffff830 0xfffff830 0xfffff830 0xfffff830 0xfffff830 0xfffff830 0xfffff830 0xfffff830 0xfffff830 0xfffff830 0xfffff830 0xfffff830 0xfffff830 0xfffff830 0xfffff830 0xfffff830 0xfffff830 0xfffff830 0xfffff830 0xfffff830 0xfffff830 0xfffff830 0xfffff830 0xfffff830 0xfffff830 0xfffff830 0xfffff830 0xfffff830 0xfffff830 0xfffff830 0xfffff830 0xfffff830 0xfffff830 0xfffff830 0xfffff830 0xfffff830 0xfffff830 0xfffff830 0xfffff830 0xfffff830 0xfffff830 0xfffff830 0xfffff830 0xfffff830 0xfffff830 0xfffff830 0xfffff830 0xfffff830 0xfffff830 0xfffff830 0xfffff830 0xfffff830 0xfffff830 0xfffff830 0xfffff830 0xfffff830 0xfffff830 0xfffff830 0xfffff830 0xfffff830 0xfffff830 0xfffff830 0xfffff830 0xfffff830 0xfffff830 0xfffff830 0xfffff830 0xfffff830 0xfffff830 0xfffff830 0xfffff830 0xfffff830 0xfffff830 0xfffff830 0xfffff830 0xfffff830 0xfffff830 0xfffff830 0xfffff830 0xfffff830 0xfffff830 0xfffff830 0xfffff830 0xfffff830 0xfffff830 0xfffff830 0xfffff830 0xfffff830 0xfffff830 0xfffff830 0xfffff830 0xfffff830 0xfffff830 0xfffff830 0xfffff830 0xfffff830 0xfffff830 0xfffff830 0xfffff830 0xfffff830 0xfffff830 0xfffff830 0xfffff830 0xfffff830 0xfffff830 0xfffff830>;
                PS_Config_Lmt_Open_Rawdata_P = <0x12f8 0x1177 0xf32 0xcd9 0xb1a 0xffff 0xffff 0xffff 0xffff 0xffff 0xffff 0xffff 0xffff 0xa5c 0xc3b 0xe97 0x10e2 0x127e 0x988 0xc02 0xbcd 0xb71 0xb43 0xd7b 0xbb2 0xbb1 0xba2 0xb7e 0xb93 0xb98 0xd46 0xc07 0xc36 0xc92 0xccd 0x9d5 0xb0a 0xbd8 0xbc3 0xb8a 0xb7a 0xb60 0xb61 0xb69 0xb5b 0xb3b 0xb54 0xb53 0xb59 0xb73 0xb85 0xbc6 0xbe2 0xb4c 0xaad 0xbc3 0xbb9 0xb80 0xb73 0xb6d 0xb6f 0xb77 0xb69 0xb5b 0xb5c 0xb66 0xb69 0xb70 0xb83 0xbc1 0xbdf 0xade 0xaa7 0xbdd 0xbc6 0xb8d 0xb77 0xb4b 0xb50 0xb58 0xb4d 0xb3f 0xb4b 0xb4a 0xb4d 0xb80 0xb94 0xbd4 0xbef 0xae0 0xaad 0xbb7 0xb94 0xb68 0xb43 0xb3e 0xb44 0xb4d 0xb42 0xb34 0xb3f 0xb30 0xb3f 0xb49 0xb76 0xbb4 0xbd0 0xaee 0xa89 0xba8 0xb8b 0xb58 0xb33 0xb35 0xb3a 0xb42 0xb38 0xb23 0xb2f 0xb2d 0xb2e 0xb3b 0xb66 0xba5 0xbbf 0xad0 0xa7b 0xb9e 0xb6f 0xb41 0xb27 0xb3a 0xb40 0xb45 0xb3d 0xb2c 0xb36 0xb37 0xb2b 0xb2a 0xb54 0xb7f 0xbad 0xac0 0xa73 0xba5 0xb75 0xb52 0xb2b 0xb2c 0xb34 0xb38 0xb32 0xb26 0xb2f 0xb35 0xb34 0xb2f 0xb57 0xb7c 0xbaf 0xaa8 0xa73 0xb95 0xb65 0xb2d 0xb11 0xb3d 0xb47 0xb4a 0xb45 0xb2b 0xb34 0xb3b 0xb38 0xb1d 0xb41 0xb77 0xbab 0xaab 0xa62 0xba5 0xb76 0xb3e 0xb2f 0xb14 0xb27 0xb2e 0xb29 0xb05 0xb11 0xb13 0xb10 0xb2b 0xb31 0xb79 0xbac 0xaa6 0xa6d 0xb82 0xb54 0xb1b 0xb0f 0xafc 0xb04 0xb0c 0xb0b 0xaef 0xafa 0xafd 0xafb 0xb02 0xb14 0xb50 0xb84 0xaa4 0xa4a 0xb5a 0xb30 0xafa 0xaea 0xaea 0xae4 0xaf9 0xafa 0xad6 0xae4 0xae5 0xae4 0xaee 0xb01 0xb30 0xb6e 0xa7a 0xa23 0xb35 0xb1e 0xae5 0xad7 0xadc 0xae3 0xaeb 0xaed 0xada 0xaeb 0xae9 0xae7 0xad5 0xae8 0xb22 0xb41 0xa5c 0xa0e 0xb27 0xafc 0xadb 0xaca 0xad0 0xad8 0xad0 0xae1 0xacc 0xae0 0xae1 0xade 0xad5 0xae8 0xb11 0xb2f 0xa40 0x9fc 0xb18 0xaec 0xac9 0xaba 0xabf 0xac6 0xacc 0xacd 0xaa7 0xab7 0xabb 0xab6 0xac9 0xad9 0xb00 0xb2e 0xa3a 0x9e9 0xb04 0xad8 0xab6 0xaa6 0xaa0 0xaab 0xab0 0xaa7 0xaaa 0xabf 0xac0 0xaba 0xaa0 0xab1 0xad6 0xb04 0xa1d 0x9d3 0xae5 0xab8 0xa95 0xa88 0xa86 0xa8f 0xa90 0xa96 0xa86 0xa94 0xa98 0xa94 0xaa6 0xab5 0xada 0xb0a 0x9ff 0x9b0 0xac2 0xa9d 0xa7a 0xa69 0xa7d 0xa86 0xa8a 0xa8e 0xa66 0xa78 0xa76 0xa75 0xa7f 0xa8e 0xab3 0xae2 0x9fe 0x97a 0xaa9 0xa92 0xa6e 0xa5f 0xa65 0xa6e 0xa75 0xa75 0xa4f 0xa6d 0xa6b 0xa6b 0xa5e 0xa6c 0xa93 0xab2 0x9d6 0x984 0xa8f 0xa79 0xa57 0xa49 0xa42 0xa48 0xa4e 0xa53 0xa59 0xa5c 0xa5a 0xa5a 0xa4e 0xa5f 0xa85 0xa9f 0x9b0 0x96b 0xa57 0xa51 0xa31 0xa24 0xa2d 0xa35 0xa3a 0xa3e 0xa3b 0xa30 0xa43 0xa3d 0xa3f 0xa50 0xa76 0xa90 0x9a1 0x942 0xa56 0xa3d 0xa1d 0xa10 0xa1b 0xa22 0xa26 0xa2c 0xa1e 0xa29 0xa24 0xa20 0xa24 0xa35 0xa5c 0xa75 0x98e 0x92a 0xa41 0xa17 0xa06 0x9fb 0x9f3 0x9ff 0xa00 0xa07 0x9fa 0xa05 0x9f1 0x9fb 0xa07 0xa18 0xa40 0xa58 0x96c 0x912 0xa1a 0xa01 0x9dc 0x9d2 0x9cf 0x9dc 0x9df 0x9e3 0x9de 0x9ee 0x9ea 0x9e0 0x9e0 0x9f1 0xa19 0xa30 0x948 0x8e8 0x9fb 0x9e2 0x9ae 0x9b0 0x9c4 0x9d1 0x9d8 0x9d1 0x9d0 0x9e3 0x9de 0x9c5 0x9c3 0x9d4 0x9fa 0xa13 0x91e 0x8c4 0x9ee 0x9d8 0x9b1 0x996 0x9c2 0x9cc 0x9d6 0x9cf 0x9c9 0x9e5 0x9dd 0x9d7 0x9a6 0x9c2 0x9ed 0xa04 0x8ff 0x8b0 0x9e9 0x9d2 0x9ad 0x9a1 0x993 0x99c 0x9a3 0x990 0x98f 0x9aa 0x9a0 0x99b 0x9b6 0x9c1 0x9ed 0xa04 0x8ee 0x8a6 0x9b7 0x9a3 0x97c 0x972 0x95d 0x975 0x97d 0x967 0x979 0x98e 0x98e 0x988 0x97a 0x97a 0x9b1 0x9c6 0x8e6 0x873 0x990 0x978 0x954 0x949 0x940 0x94c 0x952 0x93f 0x956 0x968 0x967 0x95e 0x969 0x975 0x99b 0x9b2 0x8a6 0x846 0x966 0x94e 0x92b 0x91e 0x920 0x921 0x933 0x91f 0x92b 0x940 0x93e 0x934 0x93d 0x94b 0x964 0x989 0x88c 0x818 0x948 0x92e 0x90b 0x8fb 0x917 0x924 0x928 0x911 0x91e 0x939 0x934 0x929 0x90e 0x91f 0x944 0x95c 0x85f 0x7fc 0x930 0x919 0x8f5 0x8e4 0x902 0x910 0x913 0x8ff 0x91a 0x939 0x931 0x921 0x8fc 0x90f 0x933 0x947 0x832 0x7df 0x920 0x908 0x8e2 0x8d2 0x8db 0x8ee 0x8f4 0x8d8 0x8e0 0x8ff 0x8f2 0x8e2 0x8f9 0x909 0x930 0x94a 0x818 0x78c 0x94d 0x90c 0x8be 0x8ae 0x8c1 0x8d6 0x8dc 0x8be 0x8d2 0x8f4 0x8e9 0x8d8 0x8bd 0x8cf 0x91c 0x95e 0x7dd 0xc8b 0xaf2 0x7f6 0x8df 0x8cf 0xa26 0xa38 0xa38 0xa15 0x94c 0x971 0x96e 0x95a 0x8e9 0x8fa 0x818 0xb3e 0xcff 0x32c8 0x32c8 0x32c8>;
                PS_Config_Lmt_Open_Rawdata_N = <0x821 0x77c 0x683 0x582 0x4c2 0x00 0x00 0x00 0x00 0x00 0x00 0x00 0x00 0x470 0x53e 0x641 0x73c 0x7ed 0x497 0x5c8 0x5af 0x582 0x56c 0x67e 0x5a1 0x5a1 0x59a 0x589 0x593 0x595 0x664 0x5ca 0x5e1 0x60d 0x62a 0x4bc 0x550 0x5b4 0x5aa 0x58e 0x587 0x57a 0x57a 0x57e 0x578 0x568 0x574 0x574 0x577 0x583 0x58c 0x5ab 0x5b8 0x571 0x524 0x5aa 0x5a5 0x589 0x583 0x580 0x582 0x585 0x57f 0x578 0x578 0x57d 0x57f 0x582 0x58b 0x5a9 0x5b7 0x53c 0x521 0x5b6 0x5ab 0x590 0x585 0x570 0x572 0x576 0x571 0x56a 0x570 0x56f 0x571 0x58a 0x593 0x5b2 0x5bf 0x53c 0x524 0x5a4 0x593 0x57e 0x56c 0x56a 0x56d 0x571 0x56c 0x565 0x56a 0x563 0x56a 0x56f 0x585 0x5a3 0x5b0 0x543 0x512 0x59d 0x58f 0x576 0x564 0x565 0x568 0x56c 0x567 0x55d 0x562 0x562 0x562 0x568 0x57d 0x59b 0x5a8 0x535 0x50c 0x598 0x581 0x56b 0x55f 0x568 0x56b 0x56d 0x569 0x561 0x566 0x567 0x561 0x560 0x574 0x589 0x59f 0x52d 0x508 0x59b 0x584 0x573 0x560 0x561 0x565 0x567 0x564 0x55e 0x563 0x565 0x565 0x562 0x576 0x588 0x5a0 0x521 0x508 0x594 0x57d 0x561 0x554 0x569 0x56e 0x56f 0x56d 0x561 0x565 0x568 0x567 0x55a 0x56b 0x585 0x59e 0x523 0x500 0x59b 0x585 0x56a 0x563 0x555 0x55e 0x562 0x560 0x54e 0x554 0x555 0x554 0x560 0x563 0x586 0x59f 0x520 0x505 0x58b 0x574 0x559 0x553 0x54a 0x54e 0x552 0x551 0x544 0x549 0x54a 0x549 0x54d 0x555 0x573 0x58b 0x520 0x4f4 0x577 0x563 0x549 0x541 0x541 0x53e 0x549 0x549 0x538 0x53e 0x53f 0x53e 0x543 0x54c 0x563 0x581 0x50b 0x4e1 0x565 0x55a 0x53f 0x538 0x53a 0x53e 0x542 0x543 0x539 0x542 0x541 0x540 0x537 0x540 0x55c 0x56b 0x4fd 0x4d7 0x55f 0x54a 0x53a 0x532 0x535 0x538 0x535 0x53d 0x533 0x53c 0x53d 0x53b 0x537 0x540 0x554 0x563 0x4ef 0x4ce 0x557 0x542 0x531 0x52a 0x52c 0x530 0x533 0x533 0x521 0x529 0x52b 0x528 0x531 0x539 0x54c 0x562 0x4ed 0x4c6 0x54e 0x539 0x528 0x520 0x51e 0x523 0x526 0x521 0x522 0x52c 0x52d 0x52a 0x51e 0x526 0x538 0x54e 0x4de 0x4bb 0x53f 0x529 0x518 0x512 0x511 0x515 0x516 0x519 0x511 0x518 0x51a 0x518 0x520 0x528 0x53a 0x551 0x4d0 0x4aa 0x52e 0x51c 0x50b 0x503 0x50d 0x511 0x513 0x515 0x501 0x50a 0x50a 0x509 0x50e 0x515 0x527 0x53d 0x4cf 0x490 0x522 0x517 0x506 0x4fe 0x501 0x506 0x509 0x509 0x4f7 0x505 0x504 0x504 0x4fe 0x505 0x517 0x526 0x4bc 0x495 0x515 0x50b 0x4fa 0x4f4 0x4f0 0x4f3 0x4f6 0x4f9 0x4fb 0x4fd 0x4fc 0x4fc 0x4f6 0x4fe 0x511 0x51d 0x4aa 0x489 0x4fa 0x4f8 0x4e8 0x4e2 0x4e6 0x4ea 0x4ec 0x4ef 0x4ed 0x4e8 0x4f1 0x4ee 0x4ef 0x4f7 0x509 0x516 0x4a3 0x475 0x4fa 0x4ee 0x4de 0x4d8 0x4dd 0x4e1 0x4e3 0x4e6 0x4df 0x4e4 0x4e2 0x4e0 0x4e2 0x4ea 0x4fd 0x509 0x49a 0x469 0x4f0 0x4dc 0x4d3 0x4ce 0x4ca 0x4d0 0x4d1 0x4d4 0x4ce 0x4d3 0x4c9 0x4ce 0x4d4 0x4dc 0x4ef 0x4fb 0x489 0x45e 0x4dd 0x4d1 0x4bf 0x4bb 0x4b9 0x4bf 0x4c1 0x4c2 0x4c0 0x4c8 0x4c6 0x4c1 0x4c1 0x4c9 0x4dc 0x4e8 0x478 0x44a 0x4ce 0x4c2 0x4a9 0x4aa 0x4b4 0x4ba 0x4bd 0x4ba 0x4b9 0x4c3 0x4c0 0x4b4 0x4b3 0x4bb 0x4ce 0x4da 0x464 0x438 0x4c8 0x4bd 0x4ab 0x49d 0x4b3 0x4b8 0x4bc 0x4b9 0x4b6 0x4c4 0x4c0 0x4bd 0x4a5 0x4b3 0x4c7 0x4d2 0x455 0x42f 0x4c5 0x4ba 0x4a9 0x4a3 0x49c 0x4a0 0x4a4 0x49b 0x49a 0x4a7 0x4a2 0x4a0 0x4ad 0x4b2 0x4c7 0x4d3 0x44c 0x42a 0x4ae 0x4a4 0x491 0x48c 0x482 0x48e 0x491 0x487 0x490 0x49a 0x49a 0x497 0x490 0x490 0x4ab 0x4b5 0x449 0x411 0x49b 0x48f 0x47e 0x479 0x474 0x47a 0x47d 0x474 0x47f 0x487 0x487 0x482 0x488 0x48d 0x4a0 0x4ab 0x42a 0x3fc 0x486 0x47b 0x46a 0x464 0x465 0x465 0x46e 0x464 0x46a 0x474 0x473 0x46e 0x473 0x47a 0x485 0x497 0x41d 0x3e6 0x478 0x46b 0x45a 0x453 0x460 0x467 0x469 0x45e 0x464 0x471 0x46e 0x469 0x45c 0x464 0x476 0x482 0x408 0x3d8 0x46d 0x461 0x450 0x448 0x456 0x45d 0x45e 0x455 0x462 0x471 0x46d 0x465 0x454 0x45d 0x46e 0x478 0x3f2 0x3ca 0x465 0x459 0x447 0x43f 0x443 0x44c 0x450 0x442 0x446 0x455 0x44e 0x447 0x452 0x45a 0x46c 0x479 0x3e6 0x3a2 0x47b 0x45b 0x436 0x42e 0x437 0x441 0x444 0x436 0x43f 0x450 0x44a 0x442 0x435 0x43e 0x463 0x483 0x3c9 0x60a 0x545 0x3d5 0x445 0x43e 0x4e3 0x4eb 0x4ec 0x4db 0x47a 0x48c 0x48a 0x481 0x44a 0x453 0x3e5 0x56a 0x642 0x64 0x64 0x64>;
                PS_Config_Lmt_FW_Rawdata_P = <0x6a4 0x6a4 0x6a4 0x6a4 0x6a4 0xffff 0xffff 0xffff 0xffff 0xffff 0xffff 0xffff 0xffff 0x6a4 0x6a4 0x6a4 0x6a4 0x6a4 0x6a4 0x6a4 0x6a4 0x6a4 0x6a4 0x6a4 0x6a4 0x6a4 0x6a4 0x6a4 0x6a4 0x6a4 0x6a4 0x6a4 0x6a4 0x6a4 0x6a4 0x6a4 0x6a4 0x6a4 0x6a4 0x6a4 0x6a4 0x6a4 0x6a4 0x6a4 0x6a4 0x6a4 0x6a4 0x6a4 0x6a4 0x6a4 0x6a4 0x6a4 0x6a4 0x6a4 0x6a4 0x6a4 0x6a4 0x6a4 0x6a4 0x6a4 0x6a4 0x6a4 0x6a4 0x6a4 0x6a4 0x6a4 0x6a4 0x6a4 0x6a4 0x6a4 0x6a4 0x6a4 0x6a4 0x6a4 0x6a4 0x6a4 0x6a4 0x6a4 0x6a4 0x6a4 0x6a4 0x6a4 0x6a4 0x6a4 0x6a4 0x6a4 0x6a4 0x6a4 0x6a4 0x6a4 0x6a4 0x6a4 0x6a4 0x6a4 0x6a4 0x6a4 0x6a4 0x6a4 0x6a4 0x6a4 0x6a4 0x6a4 0x6a4 0x6a4 0x6a4 0x6a4 0x6a4 0x6a4 0x6a4 0x6a4 0x6a4 0x6a4 0x6a4 0x6a4 0x6a4 0x6a4 0x6a4 0x6a4 0x6a4 0x6a4 0x6a4 0x6a4 0x6a4 0x6a4 0x6a4 0x6a4 0x6a4 0x6a4 0x6a4 0x6a4 0x6a4 0x6a4 0x6a4 0x6a4 0x6a4 0x6a4 0x6a4 0x6a4 0x6a4 0x6a4 0x6a4 0x6a4 0x6a4 0x6a4 0x6a4 0x6a4 0x6a4 0x6a4 0x6a4 0x6a4 0x6a4 0x6a4 0x6a4 0x6a4 0x6a4 0x6a4 0x6a4 0x6a4 0x6a4 0x6a4 0x6a4 0x6a4 0x6a4 0x6a4 0x6a4 0x6a4 0x6a4 0x6a4 0x6a4 0x6a4 0x6a4 0x6a4 0x6a4 0x6a4 0x6a4 0x6a4 0x6a4 0x6a4 0x6a4 0x6a4 0x6a4 0x6a4 0x6a4 0x6a4 0x6a4 0x6a4 0x6a4 0x6a4 0x6a4 0x6a4 0x6a4 0x6a4 0x6a4 0x6a4 0x6a4 0x6a4 0x6a4 0x6a4 0x6a4 0x6a4 0x6a4 0x6a4 0x6a4 0x6a4 0x6a4 0x6a4 0x6a4 0x6a4 0x6a4 0x6a4 0x6a4 0x6a4 0x6a4 0x6a4 0x6a4 0x6a4 0x6a4 0x6a4 0x6a4 0x6a4 0x6a4 0x6a4 0x6a4 0x6a4 0x6a4 0x6a4 0x6a4 0x6a4 0x6a4 0x6a4 0x6a4 0x6a4 0x6a4 0x6a4 0x6a4 0x6a4 0x6a4 0x6a4 0x6a4 0x6a4 0x6a4 0x6a4 0x6a4 0x6a4 0x6a4 0x6a4 0x6a4 0x6a4 0x6a4 0x6a4 0x6a4 0x6a4 0x6a4 0x6a4 0x6a4 0x6a4 0x6a4 0x6a4 0x6a4 0x6a4 0x6a4 0x6a4 0x6a4 0x6a4 0x6a4 0x6a4 0x6a4 0x6a4 0x6a4 0x6a4 0x6a4 0x6a4 0x6a4 0x6a4 0x6a4 0x6a4 0x6a4 0x6a4 0x6a4 0x6a4 0x6a4 0x6a4 0x6a4 0x6a4 0x6a4 0x6a4 0x6a4 0x6a4 0x6a4 0x6a4 0x6a4 0x6a4 0x6a4 0x6a4 0x6a4 0x6a4 0x6a4 0x6a4 0x6a4 0x6a4 0x6a4 0x6a4 0x6a4 0x6a4 0x6a4 0x6a4 0x6a4 0x6a4 0x6a4 0x6a4 0x6a4 0x6a4 0x6a4 0x6a4 0x6a4 0x6a4 0x6a4 0x6a4 0x6a4 0x6a4 0x6a4 0x6a4 0x6a4 0x6a4 0x6a4 0x6a4 0x6a4 0x6a4 0x6a4 0x6a4 0x6a4 0x6a4 0x6a4 0x6a4 0x6a4 0x6a4 0x6a4 0x6a4 0x6a4 0x6a4 0x6a4 0x6a4 0x6a4 0x6a4 0x6a4 0x6a4 0x6a4 0x6a4 0x6a4 0x6a4 0x6a4 0x6a4 0x6a4 0x6a4 0x6a4 0x6a4 0x6a4 0x6a4 0x6a4 0x6a4 0x6a4 0x6a4 0x6a4 0x6a4 0x6a4 0x6a4 0x6a4 0x6a4 0x6a4 0x6a4 0x6a4 0x6a4 0x6a4 0x6a4 0x6a4 0x6a4 0x6a4 0x6a4 0x6a4 0x6a4 0x6a4 0x6a4 0x6a4 0x6a4 0x6a4 0x6a4 0x6a4 0x6a4 0x6a4 0x6a4 0x6a4 0x6a4 0x6a4 0x6a4 0x6a4 0x6a4 0x6a4 0x6a4 0x6a4 0x6a4 0x6a4 0x6a4 0x6a4 0x6a4 0x6a4 0x6a4 0x6a4 0x6a4 0x6a4 0x6a4 0x6a4 0x6a4 0x6a4 0x6a4 0x6a4 0x6a4 0x6a4 0x6a4 0x6a4 0x6a4 0x6a4 0x6a4 0x6a4 0x6a4 0x6a4 0x6a4 0x6a4 0x6a4 0x6a4 0x6a4 0x6a4 0x6a4 0x6a4 0x6a4 0x6a4 0x6a4 0x6a4 0x6a4 0x6a4 0x6a4 0x6a4 0x6a4 0x6a4 0x6a4 0x6a4 0x6a4 0x6a4 0x6a4 0x6a4 0x6a4 0x6a4 0x6a4 0x6a4 0x6a4 0x6a4 0x6a4 0x6a4 0x6a4 0x6a4 0x6a4 0x6a4 0x6a4 0x6a4 0x6a4 0x6a4 0x6a4 0x6a4 0x6a4 0x6a4 0x6a4 0x6a4 0x6a4 0x6a4 0x6a4 0x6a4 0x6a4 0x6a4 0x6a4 0x6a4 0x6a4 0x6a4 0x6a4 0x6a4 0x6a4 0x6a4 0x6a4 0x6a4 0x6a4 0x6a4 0x6a4 0x6a4 0x6a4 0x6a4 0x6a4 0x6a4 0x6a4 0x6a4 0x6a4 0x6a4 0x6a4 0x6a4 0x6a4 0x6a4 0x6a4 0x6a4 0x6a4 0x6a4 0x6a4 0x6a4 0x6a4 0x6a4 0x6a4 0x6a4 0x6a4 0x6a4 0x6a4 0x6a4 0x6a4 0x6a4 0x6a4 0x6a4 0x6a4 0x6a4 0x6a4 0x6a4 0x6a4 0x6a4 0x6a4 0x6a4 0x6a4 0x6a4 0x6a4 0x6a4 0x6a4 0x6a4 0x6a4 0x6a4 0x6a4 0x6a4 0x6a4 0x6a4 0x6a4 0x6a4 0x6a4 0x6a4 0x6a4 0x6a4 0x6a4 0x6a4 0x6a4 0x6a4 0x6a4 0x6a4 0x6a4 0x6a4 0x6a4 0x6a4 0x6a4 0x6a4 0x6a4 0x6a4 0x6a4 0x6a4 0x6a4 0x6a4 0x6a4 0x6a4 0x6a4 0x6a4 0x6a4 0x6a4 0x6a4 0x6a4 0x6a4 0x6a4 0x6a4 0x6a4 0x6a4 0x6a4 0x6a4 0x6a4 0x6a4 0x6a4 0x6a4 0x6a4 0x6a4 0x6a4 0x6a4 0x6a4 0x6a4 0x6a4 0x6a4 0x6a4 0x6a4 0x6a4 0x6a4 0x6a4 0x6a4 0x6a4 0x6a4 0x6a4 0x6a4 0x6a4 0x6a4 0x6a4 0x6a4 0x6a4 0x6a4 0x6a4 0x6a4 0x6a4 0x6a4 0x6a4 0x6a4 0x6a4 0x6a4 0x6a4 0x6a4 0x6a4 0x6a4 0x6a4 0x6a4 0x6a4 0x6a4 0x6a4 0x6a4 0x6a4 0x6a4 0x6a4 0x6a4 0x6a4 0x6a4 0x6a4 0x6a4 0x6a4 0x6a4 0x6a4 0x6a4 0x6a4 0x6a4 0x6a4 0x6a4 0x6a4 0x6a4 0x6a4 0x6a4 0x6a4 0x6a4 0xfa0 0xfa0 0xfa0>;
                PS_Config_Lmt_FW_Rawdata_N = <0x2bc 0x2bc 0x2bc 0x2bc 0x2bc 0x00 0x00 0x00 0x00 0x00 0x00 0x00 0x00 0x2bc 0x2bc 0x2bc 0x2bc 0x2bc 0x2bc 0x2bc 0x2bc 0x2bc 0x2bc 0x2bc 0x2bc 0x2bc 0x2bc 0x2bc 0x2bc 0x2bc 0x2bc 0x2bc 0x2bc 0x2bc 0x2bc 0x2bc 0x2bc 0x2bc 0x2bc 0x2bc 0x2bc 0x2bc 0x2bc 0x2bc 0x2bc 0x2bc 0x2bc 0x2bc 0x2bc 0x2bc 0x2bc 0x2bc 0x2bc 0x2bc 0x2bc 0x2bc 0x2bc 0x2bc 0x2bc 0x2bc 0x2bc 0x2bc 0x2bc 0x2bc 0x2bc 0x2bc 0x2bc 0x2bc 0x2bc 0x2bc 0x2bc 0x2bc 0x2bc 0x2bc 0x2bc 0x2bc 0x2bc 0x2bc 0x2bc 0x2bc 0x2bc 0x2bc 0x2bc 0x2bc 0x2bc 0x2bc 0x2bc 0x2bc 0x2bc 0x2bc 0x2bc 0x2bc 0x2bc 0x2bc 0x2bc 0x2bc 0x2bc 0x2bc 0x2bc 0x2bc 0x2bc 0x2bc 0x2bc 0x2bc 0x2bc 0x2bc 0x2bc 0x2bc 0x2bc 0x2bc 0x2bc 0x2bc 0x2bc 0x2bc 0x2bc 0x2bc 0x2bc 0x2bc 0x2bc 0x2bc 0x2bc 0x2bc 0x2bc 0x2bc 0x2bc 0x2bc 0x2bc 0x2bc 0x2bc 0x2bc 0x2bc 0x2bc 0x2bc 0x2bc 0x2bc 0x2bc 0x2bc 0x2bc 0x2bc 0x2bc 0x2bc 0x2bc 0x2bc 0x2bc 0x2bc 0x2bc 0x2bc 0x2bc 0x2bc 0x2bc 0x2bc 0x2bc 0x2bc 0x2bc 0x2bc 0x2bc 0x2bc 0x2bc 0x2bc 0x2bc 0x2bc 0x2bc 0x2bc 0x2bc 0x2bc 0x2bc 0x2bc 0x2bc 0x2bc 0x2bc 0x2bc 0x2bc 0x2bc 0x2bc 0x2bc 0x2bc 0x2bc 0x2bc 0x2bc 0x2bc 0x2bc 0x2bc 0x2bc 0x2bc 0x2bc 0x2bc 0x2bc 0x2bc 0x2bc 0x2bc 0x2bc 0x2bc 0x2bc 0x2bc 0x2bc 0x2bc 0x2bc 0x2bc 0x2bc 0x2bc 0x2bc 0x2bc 0x2bc 0x2bc 0x2bc 0x2bc 0x2bc 0x2bc 0x2bc 0x2bc 0x2bc 0x2bc 0x2bc 0x2bc 0x2bc 0x2bc 0x2bc 0x2bc 0x2bc 0x2bc 0x2bc 0x2bc 0x2bc 0x2bc 0x2bc 0x2bc 0x2bc 0x2bc 0x2bc 0x2bc 0x2bc 0x2bc 0x2bc 0x2bc 0x2bc 0x2bc 0x2bc 0x2bc 0x2bc 0x2bc 0x2bc 0x2bc 0x2bc 0x2bc 0x2bc 0x2bc 0x2bc 0x2bc 0x2bc 0x2bc 0x2bc 0x2bc 0x2bc 0x2bc 0x2bc 0x2bc 0x2bc 0x2bc 0x2bc 0x2bc 0x2bc 0x2bc 0x2bc 0x2bc 0x2bc 0x2bc 0x2bc 0x2bc 0x2bc 0x2bc 0x2bc 0x2bc 0x2bc 0x2bc 0x2bc 0x2bc 0x2bc 0x2bc 0x2bc 0x2bc 0x2bc 0x2bc 0x2bc 0x2bc 0x2bc 0x2bc 0x2bc 0x2bc 0x2bc 0x2bc 0x2bc 0x2bc 0x2bc 0x2bc 0x2bc 0x2bc 0x2bc 0x2bc 0x2bc 0x2bc 0x2bc 0x2bc 0x2bc 0x2bc 0x2bc 0x2bc 0x2bc 0x2bc 0x2bc 0x2bc 0x2bc 0x2bc 0x2bc 0x2bc 0x2bc 0x2bc 0x2bc 0x2bc 0x2bc 0x2bc 0x2bc 0x2bc 0x2bc 0x2bc 0x2bc 0x2bc 0x2bc 0x2bc 0x2bc 0x2bc 0x2bc 0x2bc 0x2bc 0x2bc 0x2bc 0x2bc 0x2bc 0x2bc 0x2bc 0x2bc 0x2bc 0x2bc 0x2bc 0x2bc 0x2bc 0x2bc 0x2bc 0x2bc 0x2bc 0x2bc 0x2bc 0x2bc 0x2bc 0x2bc 0x2bc 0x2bc 0x2bc 0x2bc 0x2bc 0x2bc 0x2bc 0x2bc 0x2bc 0x2bc 0x2bc 0x2bc 0x2bc 0x2bc 0x2bc 0x2bc 0x2bc 0x2bc 0x2bc 0x2bc 0x2bc 0x2bc 0x2bc 0x2bc 0x2bc 0x2bc 0x2bc 0x2bc 0x2bc 0x2bc 0x2bc 0x2bc 0x2bc 0x2bc 0x2bc 0x2bc 0x2bc 0x2bc 0x2bc 0x2bc 0x2bc 0x2bc 0x2bc 0x2bc 0x2bc 0x2bc 0x2bc 0x2bc 0x2bc 0x2bc 0x2bc 0x2bc 0x2bc 0x2bc 0x2bc 0x2bc 0x2bc 0x2bc 0x2bc 0x2bc 0x2bc 0x2bc 0x2bc 0x2bc 0x2bc 0x2bc 0x2bc 0x2bc 0x2bc 0x2bc 0x2bc 0x2bc 0x2bc 0x2bc 0x2bc 0x2bc 0x2bc 0x2bc 0x2bc 0x2bc 0x2bc 0x2bc 0x2bc 0x2bc 0x2bc 0x2bc 0x2bc 0x2bc 0x2bc 0x2bc 0x2bc 0x2bc 0x2bc 0x2bc 0x2bc 0x2bc 0x2bc 0x2bc 0x2bc 0x2bc 0x2bc 0x2bc 0x2bc 0x2bc 0x2bc 0x2bc 0x2bc 0x2bc 0x2bc 0x2bc 0x2bc 0x2bc 0x2bc 0x2bc 0x2bc 0x2bc 0x2bc 0x2bc 0x2bc 0x2bc 0x2bc 0x2bc 0x2bc 0x2bc 0x2bc 0x2bc 0x2bc 0x2bc 0x2bc 0x2bc 0x2bc 0x2bc 0x2bc 0x2bc 0x2bc 0x2bc 0x2bc 0x2bc 0x2bc 0x2bc 0x2bc 0x2bc 0x2bc 0x2bc 0x2bc 0x2bc 0x2bc 0x2bc 0x2bc 0x2bc 0x2bc 0x2bc 0x2bc 0x2bc 0x2bc 0x2bc 0x2bc 0x2bc 0x2bc 0x2bc 0x2bc 0x2bc 0x2bc 0x2bc 0x2bc 0x2bc 0x2bc 0x2bc 0x2bc 0x2bc 0x2bc 0x2bc 0x2bc 0x2bc 0x2bc 0x2bc 0x2bc 0x2bc 0x2bc 0x2bc 0x2bc 0x2bc 0x2bc 0x2bc 0x2bc 0x2bc 0x2bc 0x2bc 0x2bc 0x2bc 0x2bc 0x2bc 0x2bc 0x2bc 0x2bc 0x2bc 0x2bc 0x2bc 0x2bc 0x2bc 0x2bc 0x2bc 0x2bc 0x2bc 0x2bc 0x2bc 0x2bc 0x2bc 0x2bc 0x2bc 0x2bc 0x2bc 0x2bc 0x2bc 0x2bc 0x2bc 0x2bc 0x2bc 0x2bc 0x2bc 0x2bc 0x2bc 0x2bc 0x2bc 0x2bc 0x2bc 0x2bc 0x2bc 0x2bc 0x2bc 0x2bc 0x2bc 0x2bc 0x2bc 0x2bc 0x2bc 0x2bc 0x2bc 0x2bc 0x2bc 0x2bc 0x2bc 0x2bc 0x2bc 0x2bc 0x2bc 0x2bc 0x2bc 0x2bc 0x2bc 0x2bc 0x2bc 0x2bc 0x2bc 0x2bc 0x2bc 0x2bc 0x2bc 0x2bc 0x2bc 0x2bc 0x2bc 0x2bc 0x2bc 0x2bc 0x2bc 0x2bc 0x2bc 0x2bc 0x2bc 0x2bc 0x2bc 0x2bc 0x2bc 0x2bc 0x2bc 0x2bc 0x2bc 0x2bc 0x2bc 0x2bc 0x2bc 0x2bc 0x2bc 0x2bc 0x2bc 0x2bc 0x2bc 0x2bc 0x2bc 0x2bc 0x2bc 0x2bc 0x2bc 0x64 0x64 0x64>;
                PS_Config_Lmt_FW_CC_P = <0x78 0x77 0x77 0x78 0x79 0x1ff 0x1ff 0x1ff 0x1ff 0x1ff 0x1ff 0x1ff 0x1ff 0x78 0x78 0x77 0x77 0x78 0x79 0x77 0x75 0x74 0x74 0x7a 0x78 0x77 0x7a 0x77 0x75 0x76 0x77 0x71 0x71 0x71 0x73 0x79 0x7a 0x7b 0x7a 0x79 0x78 0x7a 0x79 0x78 0x7b 0x75 0x74 0x75 0x76 0x76 0x76 0x77 0x79 0x77 0x7d 0x7d 0x7b 0x7a 0x7a 0x7a 0x79 0x78 0x7b 0x75 0x74 0x75 0x76 0x76 0x76 0x77 0x78 0x7c 0x7f 0x7c 0x7b 0x7a 0x7a 0x78 0x78 0x77 0x79 0x76 0x75 0x76 0x76 0x76 0x76 0x77 0x78 0x7b 0x7e 0x7a 0x79 0x79 0x79 0x75 0x75 0x74 0x76 0x74 0x73 0x74 0x74 0x77 0x77 0x78 0x78 0x7b 0x7c 0x77 0x76 0x76 0x76 0x77 0x77 0x75 0x78 0x72 0x71 0x73 0x73 0x75 0x75 0x75 0x76 0x7c 0x79 0x78 0x77 0x77 0x78 0x79 0x79 0x77 0x7a 0x76 0x74 0x76 0x76 0x73 0x73 0x74 0x74 0x79 0x7b 0x7a 0x7a 0x79 0x7a 0x78 0x78 0x76 0x7a 0x76 0x75 0x77 0x77 0x77 0x76 0x76 0x77 0x77 0x7d 0x79 0x78 0x78 0x79 0x79 0x7a 0x77 0x7c 0x77 0x75 0x78 0x77 0x78 0x78 0x78 0x79 0x7b 0x7c 0x7b 0x79 0x7a 0x7a 0x79 0x79 0x78 0x7c 0x75 0x74 0x76 0x76 0x78 0x78 0x77 0x78 0x7c 0x7d 0x7a 0x79 0x79 0x7a 0x75 0x75 0x75 0x7a 0x73 0x72 0x73 0x73 0x77 0x76 0x76 0x77 0x7c 0x7d 0x76 0x75 0x76 0x76 0x75 0x75 0x75 0x7a 0x73 0x73 0x74 0x74 0x73 0x73 0x73 0x74 0x7a 0x79 0x75 0x75 0x74 0x74 0x79 0x78 0x79 0x7e 0x77 0x78 0x77 0x79 0x73 0x74 0x74 0x74 0x77 0x78 0x78 0x77 0x77 0x77 0x7a 0x79 0x79 0x7f 0x76 0x78 0x76 0x78 0x77 0x77 0x77 0x78 0x77 0x7b 0x79 0x79 0x78 0x78 0x79 0x79 0x7b 0x80 0x76 0x78 0x76 0x76 0x76 0x76 0x77 0x77 0x7b 0x7c 0x79 0x79 0x79 0x78 0x77 0x77 0x79 0x7f 0x77 0x79 0x78 0x77 0x76 0x76 0x76 0x76 0x79 0x7c 0x77 0x77 0x76 0x76 0x74 0x74 0x75 0x7b 0x75 0x76 0x76 0x75 0x77 0x78 0x78 0x78 0x79 0x7a 0x74 0x74 0x74 0x73 0x76 0x76 0x77 0x7d 0x73 0x74 0x74 0x74 0x75 0x76 0x76 0x76 0x7a 0x76 0x76 0x76 0x75 0x75 0x78 0x78 0x79 0x7f 0x77 0x77 0x77 0x76 0x74 0x74 0x74 0x74 0x78 0x79 0x78 0x78 0x78 0x77 0x77 0x77 0x77 0x7f 0x78 0x77 0x78 0x78 0x76 0x77 0x77 0x77 0x76 0x7a 0x77 0x76 0x77 0x76 0x77 0x77 0x77 0x7f 0x78 0x78 0x79 0x79 0x78 0x79 0x79 0x79 0x79 0x79 0x77 0x77 0x77 0x76 0x78 0x78 0x78 0x80 0x77 0x77 0x78 0x78 0x78 0x79 0x79 0x79 0x7b 0x79 0x78 0x78 0x78 0x78 0x75 0x75 0x75 0x7c 0x74 0x75 0x75 0x75 0x77 0x78 0x78 0x78 0x7c 0x7b 0x75 0x75 0x75 0x74 0x74 0x74 0x74 0x7a 0x75 0x76 0x76 0x76 0x75 0x75 0x75 0x75 0x7a 0x77 0x74 0x74 0x73 0x73 0x77 0x77 0x78 0x7d 0x79 0x7b 0x7a 0x7a 0x75 0x75 0x76 0x76 0x77 0x76 0x77 0x78 0x76 0x76 0x7a 0x79 0x7a 0x7b 0x78 0x7a 0x7a 0x7b 0x79 0x79 0x7a 0x7a 0x77 0x79 0x79 0x79 0x78 0x78 0x7a 0x78 0x7a 0x77 0x78 0x7a 0x79 0x7a 0x79 0x79 0x7b 0x7a 0x7c 0x7b 0x78 0x79 0x77 0x77 0x78 0x77 0x79 0x76 0x79 0x7b 0x7a 0x7b 0x78 0x78 0x7a 0x79 0x7c 0x7a 0x77 0x77 0x76 0x76 0x74 0x74 0x76 0x72 0x76 0x79 0x77 0x78 0x79 0x7a 0x7b 0x7a 0x7b 0x79 0x73 0x74 0x73 0x73 0x76 0x76 0x78 0x74 0x74 0x77 0x75 0x76 0x77 0x77 0x78 0x77 0x7d 0x75 0x76 0x75 0x75 0x75 0x79 0x79 0x7c 0x76 0x78 0x7c 0x79 0x7a 0x74 0x75 0x75 0x75 0x7a 0x78 0x76 0x76 0x77 0x76 0x78 0x78 0x7b 0x76 0x7a 0x7e 0x7b 0x7b 0x78 0x79 0x79 0x79 0x77 0x79 0x76 0x76 0x76 0x76 0x78 0x79 0x7c 0x76 0x7a 0x7f 0x7c 0x7b 0x7b 0x7b 0x7b 0x7b 0x7b 0x79 0x77 0x77 0x77 0x77 0x78 0x7b 0x7e 0x78 0x79 0x7d 0x7b 0x79 0x7b 0x7b 0x7c 0x7b 0x7d 0x7b 0x7c 0x7c 0x7e 0x7e 0x7b 0x7e 0x80 0x7b 0x7b 0x7d 0x7c 0x7a 0x7f 0x80 0x7e 0x7e 0x7e 0x8a 0x8a 0x8a>;
                PS_Config_Lmt_FW_CC_N = <0x3d 0x3c 0x3c 0x3d 0x3d 0x00 0x00 0x00 0x00 0x00 0x00 0x00 0x00 0x3d 0x3d 0x3c 0x3c 0x3c 0x44 0x43 0x42 0x41 0x41 0x45 0x44 0x43 0x45 0x43 0x42 0x42 0x43 0x3f 0x3f 0x40 0x41 0x44 0x45 0x45 0x44 0x44 0x44 0x44 0x44 0x43 0x45 0x42 0x41 0x42 0x42 0x43 0x43 0x43 0x44 0x43 0x47 0x46 0x45 0x45 0x45 0x45 0x44 0x44 0x45 0x42 0x41 0x42 0x42 0x42 0x43 0x43 0x44 0x46 0x47 0x46 0x45 0x45 0x44 0x44 0x43 0x43 0x44 0x42 0x42 0x42 0x43 0x43 0x43 0x43 0x43 0x45 0x47 0x45 0x44 0x44 0x44 0x42 0x42 0x41 0x42 0x41 0x41 0x41 0x42 0x43 0x43 0x43 0x44 0x45 0x46 0x43 0x42 0x42 0x42 0x43 0x43 0x42 0x43 0x40 0x40 0x41 0x40 0x42 0x42 0x42 0x43 0x46 0x44 0x44 0x43 0x43 0x43 0x44 0x44 0x43 0x45 0x42 0x41 0x42 0x42 0x41 0x41 0x41 0x41 0x44 0x45 0x45 0x44 0x44 0x45 0x44 0x44 0x43 0x44 0x43 0x42 0x43 0x43 0x43 0x43 0x43 0x43 0x43 0x46 0x44 0x44 0x44 0x44 0x44 0x44 0x43 0x46 0x43 0x42 0x43 0x43 0x43 0x43 0x43 0x44 0x45 0x46 0x45 0x44 0x45 0x45 0x44 0x44 0x43 0x46 0x42 0x41 0x42 0x42 0x44 0x43 0x43 0x44 0x46 0x46 0x44 0x44 0x44 0x44 0x42 0x42 0x42 0x45 0x41 0x40 0x41 0x41 0x43 0x42 0x42 0x43 0x46 0x46 0x42 0x42 0x42 0x42 0x42 0x42 0x42 0x45 0x41 0x41 0x41 0x41 0x41 0x41 0x41 0x41 0x45 0x44 0x42 0x42 0x41 0x41 0x44 0x43 0x44 0x47 0x43 0x43 0x43 0x44 0x41 0x41 0x41 0x41 0x43 0x43 0x43 0x43 0x43 0x43 0x45 0x44 0x44 0x48 0x42 0x44 0x43 0x43 0x43 0x43 0x43 0x43 0x43 0x45 0x44 0x44 0x44 0x43 0x44 0x44 0x45 0x48 0x42 0x43 0x42 0x42 0x42 0x43 0x43 0x43 0x45 0x46 0x44 0x44 0x44 0x44 0x43 0x43 0x44 0x47 0x43 0x44 0x43 0x43 0x42 0x42 0x43 0x43 0x44 0x46 0x43 0x43 0x43 0x43 0x41 0x41 0x42 0x45 0x42 0x43 0x42 0x42 0x43 0x43 0x44 0x44 0x44 0x45 0x41 0x41 0x41 0x41 0x42 0x42 0x43 0x46 0x41 0x41 0x41 0x41 0x42 0x42 0x42 0x42 0x45 0x42 0x42 0x42 0x42 0x42 0x43 0x44 0x44 0x47 0x43 0x43 0x43 0x43 0x41 0x41 0x41 0x41 0x44 0x44 0x44 0x43 0x43 0x43 0x43 0x43 0x43 0x47 0x44 0x43 0x44 0x44 0x43 0x43 0x43 0x43 0x43 0x45 0x43 0x43 0x43 0x42 0x43 0x43 0x43 0x47 0x44 0x43 0x44 0x44 0x44 0x44 0x44 0x44 0x44 0x44 0x43 0x43 0x43 0x43 0x44 0x44 0x44 0x48 0x43 0x43 0x43 0x43 0x44 0x44 0x44 0x44 0x45 0x44 0x43 0x43 0x43 0x43 0x42 0x42 0x42 0x46 0x41 0x42 0x42 0x42 0x43 0x43 0x44 0x44 0x46 0x45 0x42 0x42 0x42 0x41 0x41 0x41 0x41 0x45 0x42 0x42 0x42 0x42 0x42 0x42 0x42 0x42 0x45 0x43 0x41 0x41 0x41 0x41 0x43 0x43 0x44 0x46 0x44 0x45 0x45 0x45 0x42 0x42 0x42 0x42 0x43 0x42 0x43 0x43 0x43 0x43 0x45 0x44 0x45 0x45 0x44 0x45 0x45 0x45 0x44 0x44 0x45 0x44 0x43 0x44 0x44 0x44 0x44 0x44 0x44 0x44 0x44 0x43 0x43 0x45 0x44 0x45 0x44 0x44 0x45 0x45 0x46 0x45 0x44 0x44 0x43 0x43 0x44 0x43 0x44 0x43 0x44 0x45 0x45 0x45 0x44 0x44 0x44 0x44 0x46 0x45 0x43 0x43 0x42 0x42 0x41 0x41 0x42 0x40 0x42 0x44 0x43 0x44 0x44 0x44 0x45 0x45 0x45 0x44 0x41 0x41 0x41 0x41 0x43 0x42 0x44 0x41 0x41 0x43 0x42 0x42 0x43 0x43 0x43 0x43 0x46 0x42 0x42 0x42 0x42 0x42 0x44 0x44 0x46 0x43 0x44 0x46 0x44 0x45 0x41 0x42 0x42 0x42 0x44 0x43 0x42 0x42 0x43 0x42 0x43 0x43 0x45 0x42 0x44 0x47 0x45 0x45 0x44 0x44 0x44 0x44 0x43 0x44 0x43 0x42 0x43 0x43 0x43 0x44 0x46 0x43 0x45 0x47 0x46 0x45 0x45 0x45 0x45 0x45 0x45 0x44 0x43 0x43 0x43 0x43 0x44 0x45 0x47 0x43 0x44 0x46 0x45 0x44 0x45 0x45 0x46 0x45 0x47 0x45 0x46 0x46 0x47 0x47 0x45 0x47 0x48 0x45 0x45 0x46 0x46 0x44 0x48 0x48 0x47 0x47 0x47 0x09 0x09 0x09>;
                PS_Config_Lmt_FW_CC_I_P = <0x19 0x19 0x19 0x19 0x19 0x19 0x19 0x19 0x19 0x19 0x19 0x19 0x19 0x19 0x19 0x19 0x19 0x19 0x19 0x19 0x19 0x19 0x19 0x19 0x19 0x19 0x19 0x19 0x19 0x19 0x19 0x19 0x19 0x19 0x19 0x19 0x19 0x19 0x19 0x19 0x19 0x19 0x19 0x19 0x19 0x19 0x19 0x19 0x19 0x19 0x19 0x19 0x19 0x19 0x19 0x19 0x19 0x19 0x19 0x19 0x19 0x19 0x19 0x19 0x19 0x19 0x19 0x19 0x19 0x19 0x19 0x19 0x19 0x19 0x19 0x19 0x19 0x19 0x19 0x19 0x19 0x19 0x19 0x19 0x19 0x19 0x19 0x19 0x19 0x19 0x19 0x19 0x19 0x19 0x19 0x19 0x19 0x19 0x19 0x19 0x19 0x19 0x19 0x19 0x19 0x19 0x19 0x19 0x19 0x19 0x19 0x19 0x19 0x19 0x19 0x19 0x19 0x19 0x19 0x19 0x19 0x19 0x19 0x19 0x19 0x19 0x19 0x19 0x19 0x19 0x19 0x19 0x19 0x19 0x19 0x19 0x19 0x19 0x19 0x19 0x19 0x19 0x19 0x19 0x19 0x19 0x19 0x19 0x19 0x19 0x19 0x19 0x19 0x19 0x19 0x19 0x19 0x19 0x19 0x19 0x19 0x19 0x19 0x19 0x19 0x19 0x19 0x19 0x19 0x19 0x19 0x19 0x19 0x19 0x19 0x19 0x19 0x19 0x19 0x19 0x19 0x19 0x19 0x19 0x19 0x19 0x19 0x19 0x19 0x19 0x19 0x19 0x19 0x19 0x19 0x19 0x19 0x19 0x19 0x19 0x19 0x19 0x19 0x19 0x19 0x19 0x19 0x19 0x19 0x19 0x19 0x19 0x19 0x19 0x19 0x19 0x19 0x19 0x19 0x19 0x19 0x19 0x19 0x19 0x19 0x19 0x19 0x19 0x19 0x19 0x19 0x19 0x19 0x19 0x19 0x19 0x19 0x19 0x19 0x19 0x19 0x19 0x19 0x19 0x19 0x19 0x19 0x19 0x19 0x19 0x19 0x19 0x19 0x19 0x19 0x19 0x19 0x19 0x19 0x19 0x19 0x19 0x19 0x19 0x19 0x19 0x19 0x19 0x19 0x19 0x19 0x19 0x19 0x19 0x19 0x19 0x19 0x19 0x19 0x19 0x19 0x19 0x19 0x19 0x19 0x19 0x19 0x19 0x19 0x19 0x19 0x19 0x19 0x19 0x19 0x19 0x19 0x19 0x19 0x19 0x19 0x19 0x19 0x19 0x19 0x19 0x19 0x19 0x19 0x19 0x19 0x19 0x19 0x19 0x19 0x19 0x19 0x19 0x19 0x19 0x19 0x19 0x19 0x19 0x19 0x19 0x19 0x19 0x19 0x19 0x19 0x19 0x19 0x19 0x19 0x19 0x19 0x19 0x19 0x19 0x19 0x19 0x19 0x19 0x19 0x19 0x19 0x19 0x19 0x19 0x19 0x19 0x19 0x19 0x19 0x19 0x19 0x19 0x19 0x19 0x19 0x19 0x19 0x19 0x19 0x19 0x19 0x19 0x19 0x19 0x19 0x19 0x19 0x19 0x19 0x19 0x19 0x19 0x19 0x19 0x19 0x19 0x19 0x19 0x19 0x19 0x19 0x19 0x19 0x19 0x19 0x19 0x19 0x19 0x19 0x19 0x19 0x19 0x19 0x19 0x19 0x19 0x19 0x19 0x19 0x19 0x19 0x19 0x19 0x19 0x19 0x19 0x19 0x19 0x19 0x19 0x19 0x19 0x19 0x19 0x19 0x19 0x19 0x19 0x19 0x19 0x19 0x19 0x19 0x19 0x19 0x19 0x19 0x19 0x19 0x19 0x19 0x19 0x19 0x19 0x19 0x19 0x19 0x19 0x19 0x19 0x19 0x19 0x19 0x19 0x19 0x19 0x19 0x19 0x19 0x19 0x19 0x19 0x19 0x19 0x19 0x19 0x19 0x19 0x19 0x19 0x19 0x19 0x19 0x19 0x19 0x19 0x19 0x19 0x19 0x19 0x19 0x19 0x19 0x19 0x19 0x19 0x19 0x19 0x19 0x19 0x19 0x19 0x19 0x19 0x19 0x19 0x19 0x19 0x19 0x19 0x19 0x19 0x19 0x19 0x19 0x19 0x19 0x19 0x19 0x19 0x19 0x19 0x19 0x19 0x19 0x19 0x19 0x19 0x19 0x19 0x19 0x19 0x19 0x19 0x19 0x19 0x19 0x19 0x19 0x19 0x19 0x19 0x19 0x19 0x19 0x19 0x19 0x19 0x19 0x19 0x19 0x19 0x19 0x19 0x19 0x19 0x19 0x19 0x19 0x19 0x19 0x19 0x19 0x19 0x19 0x19 0x19 0x19 0x19 0x19 0x19 0x19 0x19 0x19 0x19 0x19 0x19 0x19 0x19 0x19 0x19 0x19 0x19 0x19 0x19 0x19 0x19 0x19 0x19 0x19 0x19 0x19 0x19>;
                PS_Config_Lmt_FW_CC_I_N = <0x00 0x00 0x00 0x00 0x00 0x00 0x00 0x00 0x00 0x00 0x00 0x00 0x00 0x00 0x00 0x00 0x00 0x00 0x00 0x00 0x00 0x00 0x00 0x00 0x00 0x00 0x00 0x00 0x00 0x00 0x00 0x00 0x00 0x00 0x00 0x00 0x00 0x00 0x00 0x00 0x00 0x00 0x00 0x00 0x00 0x00 0x00 0x00 0x00 0x00 0x00 0x00 0x00 0x00 0x00 0x00 0x00 0x00 0x00 0x00 0x00 0x00 0x00 0x00 0x00 0x00 0x00 0x00 0x00 0x00 0x00 0x00 0x00 0x00 0x00 0x00 0x00 0x00 0x00 0x00 0x00 0x00 0x00 0x00 0x00 0x00 0x00 0x00 0x00 0x00 0x00 0x00 0x00 0x00 0x00 0x00 0x00 0x00 0x00 0x00 0x00 0x00 0x00 0x00 0x00 0x00 0x00 0x00 0x00 0x00 0x00 0x00 0x00 0x00 0x00 0x00 0x00 0x00 0x00 0x00 0x00 0x00 0x00 0x00 0x00 0x00 0x00 0x00 0x00 0x00 0x00 0x00 0x00 0x00 0x00 0x00 0x00 0x00 0x00 0x00 0x00 0x00 0x00 0x00 0x00 0x00 0x00 0x00 0x00 0x00 0x00 0x00 0x00 0x00 0x00 0x00 0x00 0x00 0x00 0x00 0x00 0x00 0x00 0x00 0x00 0x00 0x00 0x00 0x00 0x00 0x00 0x00 0x00 0x00 0x00 0x00 0x00 0x00 0x00 0x00 0x00 0x00 0x00 0x00 0x00 0x00 0x00 0x00 0x00 0x00 0x00 0x00 0x00 0x00 0x00 0x00 0x00 0x00 0x00 0x00 0x00 0x00 0x00 0x00 0x00 0x00 0x00 0x00 0x00 0x00 0x00 0x00 0x00 0x00 0x00 0x00 0x00 0x00 0x00 0x00 0x00 0x00 0x00 0x00 0x00 0x00 0x00 0x00 0x00 0x00 0x00 0x00 0x00 0x00 0x00 0x00 0x00 0x00 0x00 0x00 0x00 0x00 0x00 0x00 0x00 0x00 0x00 0x00 0x00 0x00 0x00 0x00 0x00 0x00 0x00 0x00 0x00 0x00 0x00 0x00 0x00 0x00 0x00 0x00 0x00 0x00 0x00 0x00 0x00 0x00 0x00 0x00 0x00 0x00 0x00 0x00 0x00 0x00 0x00 0x00 0x00 0x00 0x00 0x00 0x00 0x00 0x00 0x00 0x00 0x00 0x00 0x00 0x00 0x00 0x00 0x00 0x00 0x00 0x00 0x00 0x00 0x00 0x00 0x00 0x00 0x00 0x00 0x00 0x00 0x00 0x00 0x00 0x00 0x00 0x00 0x00 0x00 0x00 0x00 0x00 0x00 0x00 0x00 0x00 0x00 0x00 0x00 0x00 0x00 0x00 0x00 0x00 0x00 0x00 0x00 0x00 0x00 0x00 0x00 0x00 0x00 0x00 0x00 0x00 0x00 0x00 0x00 0x00 0x00 0x00 0x00 0x00 0x00 0x00 0x00 0x00 0x00 0x00 0x00 0x00 0x00 0x00 0x00 0x00 0x00 0x00 0x00 0x00 0x00 0x00 0x00 0x00 0x00 0x00 0x00 0x00 0x00 0x00 0x00 0x00 0x00 0x00 0x00 0x00 0x00 0x00 0x00 0x00 0x00 0x00 0x00 0x00 0x00 0x00 0x00 0x00 0x00 0x00 0x00 0x00 0x00 0x00 0x00 0x00 0x00 0x00 0x00 0x00 0x00 0x00 0x00 0x00 0x00 0x00 0x00 0x00 0x00 0x00 0x00 0x00 0x00 0x00 0x00 0x00 0x00 0x00 0x00 0x00 0x00 0x00 0x00 0x00 0x00 0x00 0x00 0x00 0x00 0x00 0x00 0x00 0x00 0x00 0x00 0x00 0x00 0x00 0x00 0x00 0x00 0x00 0x00 0x00 0x00 0x00 0x00 0x00 0x00 0x00 0x00 0x00 0x00 0x00 0x00 0x00 0x00 0x00 0x00 0x00 0x00 0x00 0x00 0x00 0x00 0x00 0x00 0x00 0x00 0x00 0x00 0x00 0x00 0x00 0x00 0x00 0x00 0x00 0x00 0x00 0x00 0x00 0x00 0x00 0x00 0x00 0x00 0x00 0x00 0x00 0x00 0x00 0x00 0x00 0x00 0x00 0x00 0x00 0x00 0x00 0x00 0x00 0x00 0x00 0x00 0x00 0x00 0x00 0x00 0x00 0x00 0x00 0x00 0x00 0x00 0x00 0x00 0x00 0x00 0x00 0x00 0x00 0x00 0x00 0x00 0x00 0x00 0x00 0x00 0x00 0x00 0x00 0x00 0x00 0x00 0x00 0x00 0x00 0x00 0x00 0x00 0x00 0x00 0x00 0x00 0x00 0x00 0x00 0x00 0x00 0x00 0x00 0x00 0x00 0x00 0x00 0x00 0x00 0x00 0x00 0x00 0x00 0x00 0x00 0x00 0x00 0x00 0x00 0x00 0x00 0x00>;
                PS_Config_Lmt_FW_CC_Q_P = <0x19 0x19 0x19 0x19 0x19 0x19 0x19 0x19 0x19 0x19 0x19 0x19 0x19 0x19 0x19 0x19 0x19 0x19 0x19 0x19 0x19 0x19 0x19 0x19 0x19 0x19 0x19 0x19 0x19 0x19 0x19 0x19 0x19 0x19 0x19 0x19 0x19 0x19 0x19 0x19 0x19 0x19 0x19 0x19 0x19 0x19 0x19 0x19 0x19 0x19 0x19 0x19 0x19 0x19 0x19 0x19 0x19 0x19 0x19 0x19 0x19 0x19 0x19 0x19 0x19 0x19 0x19 0x19 0x19 0x19 0x19 0x19 0x19 0x19 0x19 0x19 0x19 0x19 0x19 0x19 0x19 0x19 0x19 0x19 0x19 0x19 0x19 0x19 0x19 0x19 0x19 0x19 0x19 0x19 0x19 0x19 0x19 0x19 0x19 0x19 0x19 0x19 0x19 0x19 0x19 0x19 0x19 0x19 0x19 0x19 0x19 0x19 0x19 0x19 0x19 0x19 0x19 0x19 0x19 0x19 0x19 0x19 0x19 0x19 0x19 0x19 0x19 0x19 0x19 0x19 0x19 0x19 0x19 0x19 0x19 0x19 0x19 0x19 0x19 0x19 0x19 0x19 0x19 0x19 0x19 0x19 0x19 0x19 0x19 0x19 0x19 0x19 0x19 0x19 0x19 0x19 0x19 0x19 0x19 0x19 0x19 0x19 0x19 0x19 0x19 0x19 0x19 0x19 0x19 0x19 0x19 0x19 0x19 0x19 0x19 0x19 0x19 0x19 0x19 0x19 0x19 0x19 0x19 0x19 0x19 0x19 0x19 0x19 0x19 0x19 0x19 0x19 0x19 0x19 0x19 0x19 0x19 0x19 0x19 0x19 0x19 0x19 0x19 0x19 0x19 0x19 0x19 0x19 0x19 0x19 0x19 0x19 0x19 0x19 0x19 0x19 0x19 0x19 0x19 0x19 0x19 0x19 0x19 0x19 0x19 0x19 0x19 0x19 0x19 0x19 0x19 0x19 0x19 0x19 0x19 0x19 0x19 0x19 0x19 0x19 0x19 0x19 0x19 0x19 0x19 0x19 0x19 0x19 0x19 0x19 0x19 0x19 0x19 0x19 0x19 0x19 0x19 0x19 0x19 0x19 0x19 0x19 0x19 0x19 0x19 0x19 0x19 0x19 0x19 0x19 0x19 0x19 0x19 0x19 0x19 0x19 0x19 0x19 0x19 0x19 0x19 0x19 0x19 0x19 0x19 0x19 0x19 0x19 0x19 0x19 0x19 0x19 0x19 0x19 0x19 0x19 0x19 0x19 0x19 0x19 0x19 0x19 0x19 0x19 0x19 0x19 0x19 0x19 0x19 0x19 0x19 0x19 0x19 0x19 0x19 0x19 0x19 0x19 0x19 0x19 0x19 0x19 0x19 0x19 0x19 0x19 0x19 0x19 0x19 0x19 0x19 0x19 0x19 0x19 0x19 0x19 0x19 0x19 0x19 0x19 0x19 0x19 0x19 0x19 0x19 0x19 0x19 0x19 0x19 0x19 0x19 0x19 0x19 0x19 0x19 0x19 0x19 0x19 0x19 0x19 0x19 0x19 0x19 0x19 0x19 0x19 0x19 0x19 0x19 0x19 0x19 0x19 0x19 0x19 0x19 0x19 0x19 0x19 0x19 0x19 0x19 0x19 0x19 0x19 0x19 0x19 0x19 0x19 0x19 0x19 0x19 0x19 0x19 0x19 0x19 0x19 0x19 0x19 0x19 0x19 0x19 0x19 0x19 0x19 0x19 0x19 0x19 0x19 0x19 0x19 0x19 0x19 0x19 0x19 0x19 0x19 0x19 0x19 0x19 0x19 0x19 0x19 0x19 0x19 0x19 0x19 0x19 0x19 0x19 0x19 0x19 0x19 0x19 0x19 0x19 0x19 0x19 0x19 0x19 0x19 0x19 0x19 0x19 0x19 0x19 0x19 0x19 0x19 0x19 0x19 0x19 0x19 0x19 0x19 0x19 0x19 0x19 0x19 0x19 0x19 0x19 0x19 0x19 0x19 0x19 0x19 0x19 0x19 0x19 0x19 0x19 0x19 0x19 0x19 0x19 0x19 0x19 0x19 0x19 0x19 0x19 0x19 0x19 0x19 0x19 0x19 0x19 0x19 0x19 0x19 0x19 0x19 0x19 0x19 0x19 0x19 0x19 0x19 0x19 0x19 0x19 0x19 0x19 0x19 0x19 0x19 0x19 0x19 0x19 0x19 0x19 0x19 0x19 0x19 0x19 0x19 0x19 0x19 0x19 0x19 0x19 0x19 0x19 0x19 0x19 0x19 0x19 0x19 0x19 0x19 0x19 0x19 0x19 0x19 0x19 0x19 0x19 0x19 0x19 0x19 0x19 0x19 0x19 0x19 0x19 0x19 0x19 0x19 0x19 0x19 0x19 0x19 0x19 0x19 0x19 0x19 0x19 0x19 0x19 0x19 0x19 0x19 0x19 0x19 0x19 0x19 0x19 0x19 0x19 0x19 0x19 0x19 0x19 0x19 0x19 0x19 0x19 0x19 0x19>;
                PS_Config_Lmt_FW_CC_Q_N = <0x00 0x00 0x00 0x00 0x00 0x00 0x00 0x00 0x00 0x00 0x00 0x00 0x00 0x00 0x00 0x00 0x00 0x00 0x00 0x00 0x00 0x00 0x00 0x00 0x00 0x00 0x00 0x00 0x00 0x00 0x00 0x00 0x00 0x00 0x00 0x00 0x00 0x00 0x00 0x00 0x00 0x00 0x00 0x00 0x00 0x00 0x00 0x00 0x00 0x00 0x00 0x00 0x00 0x00 0x00 0x00 0x00 0x00 0x00 0x00 0x00 0x00 0x00 0x00 0x00 0x00 0x00 0x00 0x00 0x00 0x00 0x00 0x00 0x00 0x00 0x00 0x00 0x00 0x00 0x00 0x00 0x00 0x00 0x00 0x00 0x00 0x00 0x00 0x00 0x00 0x00 0x00 0x00 0x00 0x00 0x00 0x00 0x00 0x00 0x00 0x00 0x00 0x00 0x00 0x00 0x00 0x00 0x00 0x00 0x00 0x00 0x00 0x00 0x00 0x00 0x00 0x00 0x00 0x00 0x00 0x00 0x00 0x00 0x00 0x00 0x00 0x00 0x00 0x00 0x00 0x00 0x00 0x00 0x00 0x00 0x00 0x00 0x00 0x00 0x00 0x00 0x00 0x00 0x00 0x00 0x00 0x00 0x00 0x00 0x00 0x00 0x00 0x00 0x00 0x00 0x00 0x00 0x00 0x00 0x00 0x00 0x00 0x00 0x00 0x00 0x00 0x00 0x00 0x00 0x00 0x00 0x00 0x00 0x00 0x00 0x00 0x00 0x00 0x00 0x00 0x00 0x00 0x00 0x00 0x00 0x00 0x00 0x00 0x00 0x00 0x00 0x00 0x00 0x00 0x00 0x00 0x00 0x00 0x00 0x00 0x00 0x00 0x00 0x00 0x00 0x00 0x00 0x00 0x00 0x00 0x00 0x00 0x00 0x00 0x00 0x00 0x00 0x00 0x00 0x00 0x00 0x00 0x00 0x00 0x00 0x00 0x00 0x00 0x00 0x00 0x00 0x00 0x00 0x00 0x00 0x00 0x00 0x00 0x00 0x00 0x00 0x00 0x00 0x00 0x00 0x00 0x00 0x00 0x00 0x00 0x00 0x00 0x00 0x00 0x00 0x00 0x00 0x00 0x00 0x00 0x00 0x00 0x00 0x00 0x00 0x00 0x00 0x00 0x00 0x00 0x00 0x00 0x00 0x00 0x00 0x00 0x00 0x00 0x00 0x00 0x00 0x00 0x00 0x00 0x00 0x00 0x00 0x00 0x00 0x00 0x00 0x00 0x00 0x00 0x00 0x00 0x00 0x00 0x00 0x00 0x00 0x00 0x00 0x00 0x00 0x00 0x00 0x00 0x00 0x00 0x00 0x00 0x00 0x00 0x00 0x00 0x00 0x00 0x00 0x00 0x00 0x00 0x00 0x00 0x00 0x00 0x00 0x00 0x00 0x00 0x00 0x00 0x00 0x00 0x00 0x00 0x00 0x00 0x00 0x00 0x00 0x00 0x00 0x00 0x00 0x00 0x00 0x00 0x00 0x00 0x00 0x00 0x00 0x00 0x00 0x00 0x00 0x00 0x00 0x00 0x00 0x00 0x00 0x00 0x00 0x00 0x00 0x00 0x00 0x00 0x00 0x00 0x00 0x00 0x00 0x00 0x00 0x00 0x00 0x00 0x00 0x00 0x00 0x00 0x00 0x00 0x00 0x00 0x00 0x00 0x00 0x00 0x00 0x00 0x00 0x00 0x00 0x00 0x00 0x00 0x00 0x00 0x00 0x00 0x00 0x00 0x00 0x00 0x00 0x00 0x00 0x00 0x00 0x00 0x00 0x00 0x00 0x00 0x00 0x00 0x00 0x00 0x00 0x00 0x00 0x00 0x00 0x00 0x00 0x00 0x00 0x00 0x00 0x00 0x00 0x00 0x00 0x00 0x00 0x00 0x00 0x00 0x00 0x00 0x00 0x00 0x00 0x00 0x00 0x00 0x00 0x00 0x00 0x00 0x00 0x00 0x00 0x00 0x00 0x00 0x00 0x00 0x00 0x00 0x00 0x00 0x00 0x00 0x00 0x00 0x00 0x00 0x00 0x00 0x00 0x00 0x00 0x00 0x00 0x00 0x00 0x00 0x00 0x00 0x00 0x00 0x00 0x00 0x00 0x00 0x00 0x00 0x00 0x00 0x00 0x00 0x00 0x00 0x00 0x00 0x00 0x00 0x00 0x00 0x00 0x00 0x00 0x00 0x00 0x00 0x00 0x00 0x00 0x00 0x00 0x00 0x00 0x00 0x00 0x00 0x00 0x00 0x00 0x00 0x00 0x00 0x00 0x00 0x00 0x00 0x00 0x00 0x00 0x00 0x00 0x00 0x00 0x00 0x00 0x00 0x00 0x00 0x00 0x00 0x00 0x00 0x00 0x00 0x00 0x00 0x00 0x00 0x00 0x00 0x00 0x00 0x00 0x00 0x00 0x00 0x00 0x00 0x00 0x00 0x00 0x00 0x00 0x00 0x00 0x00 0x00 0x00 0x00 0x00 0x00 0x00 0x00 0x00 0x00>;
                PS_Config_Lmt_FW_Diff_P = <0x32 0x32 0x32 0x32 0x32 0xffff 0xffff 0xffff 0xffff 0xffff 0xffff 0xffff 0xffff 0x32 0x32 0x32 0x32 0x32 0x32 0x32 0x32 0x32 0x32 0x32 0x32 0x32 0x32 0x32 0x32 0x32 0x32 0x32 0x32 0x32 0x32 0x32 0x32 0x32 0x32 0x32 0x32 0x32 0x32 0x32 0x32 0x32 0x32 0x32 0x32 0x32 0x32 0x32 0x32 0x32 0x32 0x32 0x32 0x32 0x32 0x32 0x32 0x32 0x32 0x32 0x32 0x32 0x32 0x32 0x32 0x32 0x32 0x32 0x32 0x32 0x32 0x32 0x32 0x32 0x32 0x32 0x32 0x32 0x32 0x32 0x32 0x32 0x32 0x32 0x32 0x32 0x32 0x32 0x32 0x32 0x32 0x32 0x32 0x32 0x32 0x32 0x32 0x32 0x32 0x32 0x32 0x32 0x32 0x32 0x32 0x32 0x32 0x32 0x32 0x32 0x32 0x32 0x32 0x32 0x32 0x32 0x32 0x32 0x32 0x32 0x32 0x32 0x32 0x32 0x32 0x32 0x32 0x32 0x32 0x32 0x32 0x32 0x32 0x32 0x32 0x32 0x32 0x32 0x32 0x32 0x32 0x32 0x32 0x32 0x32 0x32 0x32 0x32 0x32 0x32 0x32 0x32 0x32 0x32 0x32 0x32 0x32 0x32 0x32 0x32 0x32 0x32 0x32 0x32 0x32 0x32 0x32 0x32 0x32 0x32 0x32 0x32 0x32 0x32 0x32 0x32 0x32 0x32 0x32 0x32 0x32 0x32 0x32 0x32 0x32 0x32 0x32 0x32 0x32 0x32 0x32 0x32 0x32 0x32 0x32 0x32 0x32 0x32 0x32 0x32 0x32 0x32 0x32 0x32 0x32 0x32 0x32 0x32 0x32 0x32 0x32 0x32 0x32 0x32 0x32 0x32 0x32 0x32 0x32 0x32 0x32 0x32 0x32 0x32 0x32 0x32 0x32 0x32 0x32 0x32 0x32 0x32 0x32 0x32 0x32 0x32 0x32 0x32 0x32 0x32 0x32 0x32 0x32 0x32 0x32 0x32 0x32 0x32 0x32 0x32 0x32 0x32 0x32 0x32 0x32 0x32 0x32 0x32 0x32 0x32 0x32 0x32 0x32 0x32 0x32 0x32 0x32 0x32 0x32 0x32 0x32 0x32 0x32 0x32 0x32 0x32 0x32 0x32 0x32 0x32 0x32 0x32 0x32 0x32 0x32 0x32 0x32 0x32 0x32 0x32 0x32 0x32 0x32 0x32 0x32 0x32 0x32 0x32 0x32 0x32 0x32 0x32 0x32 0x32 0x32 0x32 0x32 0x32 0x32 0x32 0x32 0x32 0x32 0x32 0x32 0x32 0x32 0x32 0x32 0x32 0x32 0x32 0x32 0x32 0x32 0x32 0x32 0x32 0x32 0x32 0x32 0x32 0x32 0x32 0x32 0x32 0x32 0x32 0x32 0x32 0x32 0x32 0x32 0x32 0x32 0x32 0x32 0x32 0x32 0x32 0x32 0x32 0x32 0x32 0x32 0x32 0x32 0x32 0x32 0x32 0x32 0x32 0x32 0x32 0x32 0x32 0x32 0x32 0x32 0x32 0x32 0x32 0x32 0x32 0x32 0x32 0x32 0x32 0x32 0x32 0x32 0x32 0x32 0x32 0x32 0x32 0x32 0x32 0x32 0x32 0x32 0x32 0x32 0x32 0x32 0x32 0x32 0x32 0x32 0x32 0x32 0x32 0x32 0x32 0x32 0x32 0x32 0x32 0x32 0x32 0x32 0x32 0x32 0x32 0x32 0x32 0x32 0x32 0x32 0x32 0x32 0x32 0x32 0x32 0x32 0x32 0x32 0x32 0x32 0x32 0x32 0x32 0x32 0x32 0x32 0x32 0x32 0x32 0x32 0x32 0x32 0x32 0x32 0x32 0x32 0x32 0x32 0x32 0x32 0x32 0x32 0x32 0x32 0x32 0x32 0x32 0x32 0x32 0x32 0x32 0x32 0x32 0x32 0x32 0x32 0x32 0x32 0x32 0x32 0x32 0x32 0x32 0x32 0x32 0x32 0x32 0x32 0x32 0x32 0x32 0x32 0x32 0x32 0x32 0x32 0x32 0x32 0x32 0x32 0x32 0x32 0x32 0x32 0x32 0x32 0x32 0x32 0x32 0x32 0x32 0x32 0x32 0x32 0x32 0x32 0x32 0x32 0x32 0x32 0x32 0x32 0x32 0x32 0x32 0x32 0x32 0x32 0x32 0x32 0x32 0x32 0x32 0x32 0x32 0x32 0x32 0x32 0x32 0x32 0x32 0x32 0x32 0x32 0x32 0x32 0x32 0x32 0x32 0x32 0x32 0x32 0x32 0x32 0x32 0x32 0x32 0x32 0x32 0x32 0x32 0x32 0x32 0x32 0x32 0x32 0x32 0x32 0x32 0x32 0x32 0x32 0x32 0x32 0x32 0x32 0x32 0x32 0x32 0x32 0x32 0x32 0x32 0x32 0x32 0x32 0x32 0x32 0x32 0x32 0x32 0x32 0x32 0x32 0x32 0x32 0x32 0x32 0x32 0x32 0x32 0x32 0x32 0x32 0x32 0x32 0x32 0x32 0x32 0x32 0x32 0x32 0x32 0x32 0x32 0x32 0x32 0x32 0x32 0x32 0x32 0x32 0x32 0x32 0x32 0x32 0x32 0x32 0x32 0x32 0x32 0x32 0x32 0x32 0x32 0x32 0x32 0x32 0x32 0x32 0x32 0x32 0x32 0x32 0x32 0x32 0x32 0x32 0x32 0x32 0x32 0x32 0x32 0x32 0x32 0x23 0x23 0x23>;
                PS_Config_Lmt_FW_Diff_N = <0xffffffce 0xffffffce 0xffffffce 0xffffffce 0xffffffce 0xffff0001 0xffff0001 0xffff0001 0xffff0001 0xffff0001 0xffff0001 0xffff0001 0xffff0001 0xffffffce 0xffffffce 0xffffffce 0xffffffce 0xffffffce 0xffffffce 0xffffffce 0xffffffce 0xffffffce 0xffffffce 0xffffffce 0xffffffce 0xffffffce 0xffffffce 0xffffffce 0xffffffce 0xffffffce 0xffffffce 0xffffffce 0xffffffce 0xffffffce 0xffffffce 0xffffffce 0xffffffce 0xffffffce 0xffffffce 0xffffffce 0xffffffce 0xffffffce 0xffffffce 0xffffffce 0xffffffce 0xffffffce 0xffffffce 0xffffffce 0xffffffce 0xffffffce 0xffffffce 0xffffffce 0xffffffce 0xffffffce 0xffffffce 0xffffffce 0xffffffce 0xffffffce 0xffffffce 0xffffffce 0xffffffce 0xffffffce 0xffffffce 0xffffffce 0xffffffce 0xffffffce 0xffffffce 0xffffffce 0xffffffce 0xffffffce 0xffffffce 0xffffffce 0xffffffce 0xffffffce 0xffffffce 0xffffffce 0xffffffce 0xffffffce 0xffffffce 0xffffffce 0xffffffce 0xffffffce 0xffffffce 0xffffffce 0xffffffce 0xffffffce 0xffffffce 0xffffffce 0xffffffce 0xffffffce 0xffffffce 0xffffffce 0xffffffce 0xffffffce 0xffffffce 0xffffffce 0xffffffce 0xffffffce 0xffffffce 0xffffffce 0xffffffce 0xffffffce 0xffffffce 0xffffffce 0xffffffce 0xffffffce 0xffffffce 0xffffffce 0xffffffce 0xffffffce 0xffffffce 0xffffffce 0xffffffce 0xffffffce 0xffffffce 0xffffffce 0xffffffce 0xffffffce 0xffffffce 0xffffffce 0xffffffce 0xffffffce 0xffffffce 0xffffffce 0xffffffce 0xffffffce 0xffffffce 0xffffffce 0xffffffce 0xffffffce 0xffffffce 0xffffffce 0xffffffce 0xffffffce 0xffffffce 0xffffffce 0xffffffce 0xffffffce 0xffffffce 0xffffffce 0xffffffce 0xffffffce 0xffffffce 0xffffffce 0xffffffce 0xffffffce 0xffffffce 0xffffffce 0xffffffce 0xffffffce 0xffffffce 0xffffffce 0xffffffce 0xffffffce 0xffffffce 0xffffffce 0xffffffce 0xffffffce 0xffffffce 0xffffffce 0xffffffce 0xffffffce 0xffffffce 0xffffffce 0xffffffce 0xffffffce 0xffffffce 0xffffffce 0xffffffce 0xffffffce 0xffffffce 0xffffffce 0xffffffce 0xffffffce 0xffffffce 0xffffffce 0xffffffce 0xffffffce 0xffffffce 0xffffffce 0xffffffce 0xffffffce 0xffffffce 0xffffffce 0xffffffce 0xffffffce 0xffffffce 0xffffffce 0xffffffce 0xffffffce 0xffffffce 0xffffffce 0xffffffce 0xffffffce 0xffffffce 0xffffffce 0xffffffce 0xffffffce 0xffffffce 0xffffffce 0xffffffce 0xffffffce 0xffffffce 0xffffffce 0xffffffce 0xffffffce 0xffffffce 0xffffffce 0xffffffce 0xffffffce 0xffffffce 0xffffffce 0xffffffce 0xffffffce 0xffffffce 0xffffffce 0xffffffce 0xffffffce 0xffffffce 0xffffffce 0xffffffce 0xffffffce 0xffffffce 0xffffffce 0xffffffce 0xffffffce 0xffffffce 0xffffffce 0xffffffce 0xffffffce 0xffffffce 0xffffffce 0xffffffce 0xffffffce 0xffffffce 0xffffffce 0xffffffce 0xffffffce 0xffffffce 0xffffffce 0xffffffce 0xffffffce 0xffffffce 0xffffffce 0xffffffce 0xffffffce 0xffffffce 0xffffffce 0xffffffce 0xffffffce 0xffffffce 0xffffffce 0xffffffce 0xffffffce 0xffffffce 0xffffffce 0xffffffce 0xffffffce 0xffffffce 0xffffffce 0xffffffce 0xffffffce 0xffffffce 0xffffffce 0xffffffce 0xffffffce 0xffffffce 0xffffffce 0xffffffce 0xffffffce 0xffffffce 0xffffffce 0xffffffce 0xffffffce 0xffffffce 0xffffffce 0xffffffce 0xffffffce 0xffffffce 0xffffffce 0xffffffce 0xffffffce 0xffffffce 0xffffffce 0xffffffce 0xffffffce 0xffffffce 0xffffffce 0xffffffce 0xffffffce 0xffffffce 0xffffffce 0xffffffce 0xffffffce 0xffffffce 0xffffffce 0xffffffce 0xffffffce 0xffffffce 0xffffffce 0xffffffce 0xffffffce 0xffffffce 0xffffffce 0xffffffce 0xffffffce 0xffffffce 0xffffffce 0xffffffce 0xffffffce 0xffffffce 0xffffffce 0xffffffce 0xffffffce 0xffffffce 0xffffffce 0xffffffce 0xffffffce 0xffffffce 0xffffffce 0xffffffce 0xffffffce 0xffffffce 0xffffffce 0xffffffce 0xffffffce 0xffffffce 0xffffffce 0xffffffce 0xffffffce 0xffffffce 0xffffffce 0xffffffce 0xffffffce 0xffffffce 0xffffffce 0xffffffce 0xffffffce 0xffffffce 0xffffffce 0xffffffce 0xffffffce 0xffffffce 0xffffffce 0xffffffce 0xffffffce 0xffffffce 0xffffffce 0xffffffce 0xffffffce 0xffffffce 0xffffffce 0xffffffce 0xffffffce 0xffffffce 0xffffffce 0xffffffce 0xffffffce 0xffffffce 0xffffffce 0xffffffce 0xffffffce 0xffffffce 0xffffffce 0xffffffce 0xffffffce 0xffffffce 0xffffffce 0xffffffce 0xffffffce 0xffffffce 0xffffffce 0xffffffce 0xffffffce 0xffffffce 0xffffffce 0xffffffce 0xffffffce 0xffffffce 0xffffffce 0xffffffce 0xffffffce 0xffffffce 0xffffffce 0xffffffce 0xffffffce 0xffffffce 0xffffffce 0xffffffce 0xffffffce 0xffffffce 0xffffffce 0xffffffce 0xffffffce 0xffffffce 0xffffffce 0xffffffce 0xffffffce 0xffffffce 0xffffffce 0xffffffce 0xffffffce 0xffffffce 0xffffffce 0xffffffce 0xffffffce 0xffffffce 0xffffffce 0xffffffce 0xffffffce 0xffffffce 0xffffffce 0xffffffce 0xffffffce 0xffffffce 0xffffffce 0xffffffce 0xffffffce 0xffffffce 0xffffffce 0xffffffce 0xffffffce 0xffffffce 0xffffffce 0xffffffce 0xffffffce 0xffffffce 0xffffffce 0xffffffce 0xffffffce 0xffffffce 0xffffffce 0xffffffce 0xffffffce 0xffffffce 0xffffffce 0xffffffce 0xffffffce 0xffffffce 0xffffffce 0xffffffce 0xffffffce 0xffffffce 0xffffffce 0xffffffce 0xffffffce 0xffffffce 0xffffffce 0xffffffce 0xffffffce 0xffffffce 0xffffffce 0xffffffce 0xffffffce 0xffffffce 0xffffffce 0xffffffce 0xffffffce 0xffffffce 0xffffffce 0xffffffce 0xffffffce 0xffffffce 0xffffffce 0xffffffce 0xffffffce 0xffffffce 0xffffffce 0xffffffce 0xffffffce 0xffffffce 0xffffffce 0xffffffce 0xffffffce 0xffffffce 0xffffffce 0xffffffce 0xffffffce 0xffffffce 0xffffffce 0xffffffce 0xffffffce 0xffffffce 0xffffffce 0xffffffce 0xffffffce 0xffffffce 0xffffffce 0xffffffce 0xffffffce 0xffffffce 0xffffffce 0xffffffce 0xffffffce 0xffffffce 0xffffffce 0xffffffce 0xffffffce 0xffffffce 0xffffffce 0xffffffce 0xffffffce 0xffffffce 0xffffffce 0xffffffce 0xffffffce 0xffffffce 0xffffffce 0xffffffce 0xffffffce 0xffffffce 0xffffffce 0xffffffce 0xffffffce 0xffffffce 0xffffffce 0xffffffce 0xffffffce 0xffffffce 0xffffffce 0xffffffce 0xffffffce 0xffffffce 0xffffffce 0xffffffce 0xffffffce 0xffffffce 0xffffffce 0xffffffce 0xffffffce 0xffffffce 0xffffffce 0xffffffce 0xffffffce 0xffffffce 0xffffffce 0xffffffce 0xffffffce 0xffffffce 0xffffffce 0xffffffce 0xffffffce 0xffffffce 0xffffffce 0xffffffce 0xffffffce 0xffffffce 0xffffffce 0xffffffce 0xffffffce 0xffffffce 0xffffffce 0xffffffce 0xffffffce 0xffffffce 0xffffffce 0xffffffce 0xffffffce 0xffffffce 0xffffffce 0xffffffce 0xffffffce 0xffffffce 0xffffffce 0xffffffce 0xffffffce 0xffffffce 0xffffffce 0xffffffce 0xffffffce 0xffffffce 0xffffffce 0xffffffce 0xffffffce 0xffffffce 0xffffffce 0xffffffce 0xffffffce 0xffffffce 0xffffffce 0xffffffce 0xffffffce 0xffffffce 0xffffffce 0xffffffce 0xffffffce 0xffffffce 0xffffffce 0xffffffce 0xffffffce 0xffffffce 0xffffffce 0xffffffce 0xffffffce 0xffffffce 0xffffffce 0xffffffce 0xffffffce 0xffffffce 0xffffffce 0xffffffce 0xffffffce 0xffffffce 0xffffffce 0xffffffce 0xffffffce 0xffffffce 0xffffffce 0xffffffce 0xffffffce 0xffffffce 0xffffffce 0xffffffce 0xffffffce 0xffffffce 0xffffffce 0xffffffce 0xffffffce 0xffffffce 0xffffffce 0xffffffce 0xffffffce 0xffffffce 0xffffffce 0xffffffce 0xffffffce 0xffffffce 0xffffffce 0xffffffce 0xffffffce 0xffffffce 0xffffffce 0xffffffce 0xffffffce 0xffffffce 0xffffffce 0xffffffce 0xffffffce 0xffffffce 0xffffffce 0xffffffce 0xffffffce 0xffffffce 0xffffffce 0xffffffce 0xffffffce 0xffffffce 0xffffffce 0xffffffdd 0xffffffdd 0xffffffdd>;
                PS_Config_Diff_Test_Frame = <0x32>;
            };

            novatek-mp-criteria-6106@1 {
                #address-cells = <0x01>;
                #size-cells = <0x00>;
                compatible = "novatek-mp-criteria-6106";
                IC_X_CFG_SIZE = <0x12>;
                IC_Y_CFG_SIZE = <0x24>;
                IC_KEY_CFG_SIZE = <0x00>;
                X_Channel = <0x12>;
                Y_Channel = <0x24>;
                AIN_X = <0x00 0x01 0x02 0x03 0x04 0x05 0x06 0x07 0x08 0x09 0x0a 0x0b 0x0c 0x0d 0x0e 0x0f 0x10 0x11>;
                AIN_Y = <0x00 0x01 0x02 0x03 0x04 0x05 0x06 0x07 0x08 0x09 0x0a 0x0b 0x0c 0x0d 0x0e 0x0f 0x10 0x11 0x12 0x13 0x14 0x15 0x16 0x17 0x18 0x19 0x1a 0x1b 0x1c 0x1d 0x1e 0x1f 0x20 0x21 0x22 0x23>;
                AIN_KEY = <0x00 0x01 0x02 0xff>;
                PS_Config_Lmt_Short_Rawdata_P = <0x36b0 0x36b0 0x36b0 0x36b0 0x36b0 0x36b0 0x36b0 0x36b0 0x36b0 0x36b0 0x36b0 0x36b0 0x36b0 0x36b0 0x36b0 0x36b0 0x36b0 0x36b0 0x36b0 0x36b0 0x36b0 0x36b0 0x36b0 0x36b0 0x36b0 0x36b0 0x36b0 0x36b0 0x36b0 0x36b0 0x36b0 0x36b0 0x36b0 0x36b0 0x36b0 0x36b0 0x36b0 0x36b0 0x36b0 0x36b0 0x36b0 0x36b0 0x36b0 0x36b0 0x36b0 0x36b0 0x36b0 0x36b0 0x36b0 0x36b0 0x36b0 0x36b0 0x36b0 0x36b0 0x36b0 0x36b0 0x36b0 0x36b0 0x36b0 0x36b0 0x36b0 0x36b0 0x36b0 0x36b0 0x36b0 0x36b0 0x36b0 0x36b0 0x36b0 0x36b0 0x36b0 0x36b0 0x36b0 0x36b0 0x36b0 0x36b0 0x36b0 0x36b0 0x36b0 0x36b0 0x36b0 0x36b0 0x36b0 0x36b0 0x36b0 0x36b0 0x36b0 0x36b0 0x36b0 0x36b0 0x36b0 0x36b0 0x36b0 0x36b0 0x36b0 0x36b0 0x36b0 0x36b0 0x36b0 0x36b0 0x36b0 0x36b0 0x36b0 0x36b0 0x36b0 0x36b0 0x36b0 0x36b0 0x36b0 0x36b0 0x36b0 0x36b0 0x36b0 0x36b0 0x36b0 0x36b0 0x36b0 0x36b0 0x36b0 0x36b0 0x36b0 0x36b0 0x36b0 0x36b0 0x36b0 0x36b0 0x36b0 0x36b0 0x36b0 0x36b0 0x36b0 0x36b0 0x36b0 0x36b0 0x36b0 0x36b0 0x36b0 0x36b0 0x36b0 0x36b0 0x36b0 0x36b0 0x36b0 0x36b0 0x36b0 0x36b0 0x36b0 0x36b0 0x36b0 0x36b0 0x36b0 0x36b0 0x36b0 0x36b0 0x36b0 0x36b0 0x36b0 0x36b0 0x36b0 0x36b0 0x36b0 0x36b0 0x36b0 0x36b0 0x36b0 0x36b0 0x36b0 0x36b0 0x36b0 0x36b0 0x36b0 0x36b0 0x36b0 0x36b0 0x36b0 0x36b0 0x36b0 0x36b0 0x36b0 0x36b0 0x36b0 0x36b0 0x36b0 0x36b0 0x36b0 0x36b0 0x36b0 0x36b0 0x36b0 0x36b0 0x36b0 0x36b0 0x36b0 0x36b0 0x36b0 0x36b0 0x36b0 0x36b0 0x36b0 0x36b0 0x36b0 0x36b0 0x36b0 0x36b0 0x36b0 0x36b0 0x36b0 0x36b0 0x36b0 0x36b0 0x36b0 0x36b0 0x36b0 0x36b0 0x36b0 0x36b0 0x36b0 0x36b0 0x36b0 0x36b0 0x36b0 0x36b0 0x36b0 0x36b0 0x36b0 0x36b0 0x36b0 0x36b0 0x36b0 0x36b0 0x36b0 0x36b0 0x36b0 0x36b0 0x36b0 0x36b0 0x36b0 0x36b0 0x36b0 0x36b0 0x36b0 0x36b0 0x36b0 0x36b0 0x36b0 0x36b0 0x36b0 0x36b0 0x36b0 0x36b0 0x36b0 0x36b0 0x36b0 0x36b0 0x36b0 0x36b0 0x36b0 0x36b0 0x36b0 0x36b0 0x36b0 0x36b0 0x36b0 0x36b0 0x36b0 0x36b0 0x36b0 0x36b0 0x36b0 0x36b0 0x36b0 0x36b0 0x36b0 0x36b0 0x36b0 0x36b0 0x36b0 0x36b0 0x36b0 0x36b0 0x36b0 0x36b0 0x36b0 0x36b0 0x36b0 0x36b0 0x36b0 0x36b0 0x36b0 0x36b0 0x36b0 0x36b0 0x36b0 0x36b0 0x36b0 0x36b0 0x36b0 0x36b0 0x36b0 0x36b0 0x36b0 0x36b0 0x36b0 0x36b0 0x36b0 0x36b0 0x36b0 0x36b0 0x36b0 0x36b0 0x36b0 0x36b0 0x36b0 0x36b0 0x36b0 0x36b0 0x36b0 0x36b0 0x36b0 0x36b0 0x36b0 0x36b0 0x36b0 0x36b0 0x36b0 0x36b0 0x36b0 0x36b0 0x36b0 0x36b0 0x36b0 0x36b0 0x36b0 0x36b0 0x36b0 0x36b0 0x36b0 0x36b0 0x36b0 0x36b0 0x36b0 0x36b0 0x36b0 0x36b0 0x36b0 0x36b0 0x36b0 0x36b0 0x36b0 0x36b0 0x36b0 0x36b0 0x36b0 0x36b0 0x36b0 0x36b0 0x36b0 0x36b0 0x36b0 0x36b0 0x36b0 0x36b0 0x36b0 0x36b0 0x36b0 0x36b0 0x36b0 0x36b0 0x36b0 0x36b0 0x36b0 0x36b0 0x36b0 0x36b0 0x36b0 0x36b0 0x36b0 0x36b0 0x36b0 0x36b0 0x36b0 0x36b0 0x36b0 0x36b0 0x36b0 0x36b0 0x36b0 0x36b0 0x36b0 0x36b0 0x36b0 0x36b0 0x36b0 0x36b0 0x36b0 0x36b0 0x36b0 0x36b0 0x36b0 0x36b0 0x36b0 0x36b0 0x36b0 0x36b0 0x36b0 0x36b0 0x36b0 0x36b0 0x36b0 0x36b0 0x36b0 0x36b0 0x36b0 0x36b0 0x36b0 0x36b0 0x36b0 0x36b0 0x36b0 0x36b0 0x36b0 0x36b0 0x36b0 0x36b0 0x36b0 0x36b0 0x36b0 0x36b0 0x36b0 0x36b0 0x36b0 0x36b0 0x36b0 0x36b0 0x36b0 0x36b0 0x36b0 0x36b0 0x36b0 0x36b0 0x36b0 0x36b0 0x36b0 0x36b0 0x36b0 0x36b0 0x36b0 0x36b0 0x36b0 0x36b0 0x36b0 0x36b0 0x36b0 0x36b0 0x36b0 0x36b0 0x36b0 0x36b0 0x36b0 0x36b0 0x36b0 0x36b0 0x36b0 0x36b0 0x36b0 0x36b0 0x36b0 0x36b0 0x36b0 0x36b0 0x36b0 0x36b0 0x36b0 0x36b0 0x36b0 0x36b0 0x36b0 0x36b0 0x36b0 0x36b0 0x36b0 0x36b0 0x36b0 0x36b0 0x36b0 0x36b0 0x36b0 0x36b0 0x36b0 0x36b0 0x36b0 0x36b0 0x36b0 0x36b0 0x36b0 0x36b0 0x36b0 0x36b0 0x36b0 0x36b0 0x36b0 0x36b0 0x36b0 0x36b0 0x36b0 0x36b0 0x36b0 0x36b0 0x36b0 0x36b0 0x36b0 0x36b0 0x36b0 0x36b0 0x36b0 0x36b0 0x36b0 0x36b0 0x36b0 0x36b0 0x36b0 0x36b0 0x36b0 0x36b0 0x36b0 0x36b0 0x36b0 0x36b0 0x36b0 0x36b0 0x36b0 0x36b0 0x36b0 0x36b0 0x36b0 0x36b0 0x36b0 0x36b0 0x36b0 0x36b0 0x36b0 0x36b0 0x36b0 0x36b0 0x36b0 0x36b0 0x36b0 0x36b0 0x36b0 0x36b0 0x36b0 0x36b0 0x36b0 0x36b0 0x36b0 0x36b0 0x36b0 0x36b0 0x36b0 0x36b0 0x36b0 0x36b0 0x36b0 0x36b0 0x36b0 0x36b0 0x36b0 0x36b0 0x36b0 0x36b0 0x36b0 0x36b0 0x36b0 0x36b0 0x36b0 0x36b0 0x36b0 0x36b0 0x36b0 0x36b0 0x36b0 0x36b0 0x36b0 0x36b0 0x36b0 0x36b0 0x36b0 0x36b0 0x36b0 0x36b0 0x36b0 0x36b0 0x36b0 0x36b0 0x36b0 0x36b0 0x36b0 0x36b0 0x36b0 0x36b0 0x36b0 0x36b0 0x36b0 0x36b0 0x36b0 0x36b0 0x36b0 0x36b0 0x36b0 0x36b0 0x36b0 0x36b0 0x36b0 0x36b0 0x36b0 0x36b0 0x36b0 0x36b0 0x36b0 0x36b0 0x36b0 0x36b0 0x36b0 0x36b0 0x36b0 0x36b0 0x36b0 0x36b0 0x36b0 0x36b0 0x36b0 0x36b0 0x36b0 0x36b0 0x36b0 0x36b0 0x36b0 0x36b0 0x36b0 0x36b0 0x36b0 0x36b0 0x36b0 0x36b0 0x36b0 0x36b0 0x36b0 0x36b0 0x4e20 0x4e20 0x4e20>;
                PS_Config_Lmt_Short_Rawdata_N = <0x2c70 0x2c70 0x2c70 0x2c70 0x2c70 0x2c70 0x2c70 0x2c70 0x2c70 0x2c70 0x2c70 0x2c70 0x2c70 0x2c70 0x2c70 0x2c70 0x2c70 0x2c70 0x2c70 0x2c70 0x2c70 0x2c70 0x2c70 0x2c70 0x2c70 0x2c70 0x2c70 0x2c70 0x2c70 0x2c70 0x2c70 0x2c70 0x2c70 0x2c70 0x2c70 0x2c70 0x2c70 0x2c70 0x2c70 0x2c70 0x2c70 0x2c70 0x2c70 0x2c70 0x2c70 0x2c70 0x2c70 0x2c70 0x2c70 0x2c70 0x2c70 0x2c70 0x2c70 0x2c70 0x2c70 0x2c70 0x2c70 0x2c70 0x2c70 0x2c70 0x2c70 0x2c70 0x2c70 0x2c70 0x2c70 0x2c70 0x2c70 0x2c70 0x2c70 0x2c70 0x2c70 0x2c70 0x2c70 0x2c70 0x2c70 0x2c70 0x2c70 0x2c70 0x2c70 0x2c70 0x2c70 0x2c70 0x2c70 0x2c70 0x2c70 0x2c70 0x2c70 0x2c70 0x2c70 0x2c70 0x2c70 0x2c70 0x2c70 0x2c70 0x2c70 0x2c70 0x2c70 0x2c70 0x2c70 0x2c70 0x2c70 0x2c70 0x2c70 0x2c70 0x2c70 0x2c70 0x2c70 0x2c70 0x2c70 0x2c70 0x2c70 0x2c70 0x2c70 0x2c70 0x2c70 0x2c70 0x2c70 0x2c70 0x2c70 0x2c70 0x2c70 0x2c70 0x2c70 0x2c70 0x2c70 0x2c70 0x2c70 0x2c70 0x2c70 0x2c70 0x2c70 0x2c70 0x2c70 0x2c70 0x2c70 0x2c70 0x2c70 0x2c70 0x2c70 0x2c70 0x2c70 0x2c70 0x2c70 0x2c70 0x2c70 0x2c70 0x2c70 0x2c70 0x2c70 0x2c70 0x2c70 0x2c70 0x2c70 0x2c70 0x2c70 0x2c70 0x2c70 0x2c70 0x2c70 0x2c70 0x2c70 0x2c70 0x2c70 0x2c70 0x2c70 0x2c70 0x2c70 0x2c70 0x2c70 0x2c70 0x2c70 0x2c70 0x2c70 0x2c70 0x2c70 0x2c70 0x2c70 0x2c70 0x2c70 0x2c70 0x2c70 0x2c70 0x2c70 0x2c70 0x2c70 0x2c70 0x2c70 0x2c70 0x2c70 0x2c70 0x2c70 0x2c70 0x2c70 0x2c70 0x2c70 0x2c70 0x2c70 0x2c70 0x2c70 0x2c70 0x2c70 0x2c70 0x2c70 0x2c70 0x2c70 0x2c70 0x2c70 0x2c70 0x2c70 0x2c70 0x2c70 0x2c70 0x2c70 0x2c70 0x2c70 0x2c70 0x2c70 0x2c70 0x2c70 0x2c70 0x2c70 0x2c70 0x2c70 0x2c70 0x2c70 0x2c70 0x2c70 0x2c70 0x2c70 0x2c70 0x2c70 0x2c70 0x2c70 0x2c70 0x2c70 0x2c70 0x2c70 0x2c70 0x2c70 0x2c70 0x2c70 0x2c70 0x2c70 0x2c70 0x2c70 0x2c70 0x2c70 0x2c70 0x2c70 0x2c70 0x2c70 0x2c70 0x2c70 0x2c70 0x2c70 0x2c70 0x2c70 0x2c70 0x2c70 0x2c70 0x2c70 0x2c70 0x2c70 0x2c70 0x2c70 0x2c70 0x2c70 0x2c70 0x2c70 0x2c70 0x2c70 0x2c70 0x2c70 0x2c70 0x2c70 0x2c70 0x2c70 0x2c70 0x2c70 0x2c70 0x2c70 0x2c70 0x2c70 0x2c70 0x2c70 0x2c70 0x2c70 0x2c70 0x2c70 0x2c70 0x2c70 0x2c70 0x2c70 0x2c70 0x2c70 0x2c70 0x2c70 0x2c70 0x2c70 0x2c70 0x2c70 0x2c70 0x2c70 0x2c70 0x2c70 0x2c70 0x2c70 0x2c70 0x2c70 0x2c70 0x2c70 0x2c70 0x2c70 0x2c70 0x2c70 0x2c70 0x2c70 0x2c70 0x2c70 0x2c70 0x2c70 0x2c70 0x2c70 0x2c70 0x2c70 0x2c70 0x2c70 0x2c70 0x2c70 0x2c70 0x2c70 0x2c70 0x2c70 0x2c70 0x2c70 0x2c70 0x2c70 0x2c70 0x2c70 0x2c70 0x2c70 0x2c70 0x2c70 0x2c70 0x2c70 0x2c70 0x2c70 0x2c70 0x2c70 0x2c70 0x2c70 0x2c70 0x2c70 0x2c70 0x2c70 0x2c70 0x2c70 0x2c70 0x2c70 0x2c70 0x2c70 0x2c70 0x2c70 0x2c70 0x2c70 0x2c70 0x2c70 0x2c70 0x2c70 0x2c70 0x2c70 0x2c70 0x2c70 0x2c70 0x2c70 0x2c70 0x2c70 0x2c70 0x2c70 0x2c70 0x2c70 0x2c70 0x2c70 0x2c70 0x2c70 0x2c70 0x2c70 0x2c70 0x2c70 0x2c70 0x2c70 0x2c70 0x2c70 0x2c70 0x2c70 0x2c70 0x2c70 0x2c70 0x2c70 0x2c70 0x2c70 0x2c70 0x2c70 0x2c70 0x2c70 0x2c70 0x2c70 0x2c70 0x2c70 0x2c70 0x2c70 0x2c70 0x2c70 0x2c70 0x2c70 0x2c70 0x2c70 0x2c70 0x2c70 0x2c70 0x2c70 0x2c70 0x2c70 0x2c70 0x2c70 0x2c70 0x2c70 0x2c70 0x2c70 0x2c70 0x2c70 0x2c70 0x2c70 0x2c70 0x2c70 0x2c70 0x2c70 0x2c70 0x2c70 0x2c70 0x2c70 0x2c70 0x2c70 0x2c70 0x2c70 0x2c70 0x2c70 0x2c70 0x2c70 0x2c70 0x2c70 0x2c70 0x2c70 0x2c70 0x2c70 0x2c70 0x2c70 0x2c70 0x2c70 0x2c70 0x2c70 0x2c70 0x2c70 0x2c70 0x2c70 0x2c70 0x2c70 0x2c70 0x2c70 0x2c70 0x2c70 0x2c70 0x2c70 0x2c70 0x2c70 0x2c70 0x2c70 0x2c70 0x2c70 0x2c70 0x2c70 0x2c70 0x2c70 0x2c70 0x2c70 0x2c70 0x2c70 0x2c70 0x2c70 0x2c70 0x2c70 0x2c70 0x2c70 0x2c70 0x2c70 0x2c70 0x2c70 0x2c70 0x2c70 0x2c70 0x2c70 0x2c70 0x2c70 0x2c70 0x2c70 0x2c70 0x2c70 0x2c70 0x2c70 0x2c70 0x2c70 0x2c70 0x2c70 0x2c70 0x2c70 0x2c70 0x2c70 0x2c70 0x2c70 0x2c70 0x2c70 0x2c70 0x2c70 0x2c70 0x2c70 0x2c70 0x2c70 0x2c70 0x2c70 0x2c70 0x2c70 0x2c70 0x2c70 0x2c70 0x2c70 0x2c70 0x2c70 0x2c70 0x2c70 0x2c70 0x2c70 0x2c70 0x2c70 0x2c70 0x2c70 0x2c70 0x2c70 0x2c70 0x2c70 0x2c70 0x2c70 0x2c70 0x2c70 0x2c70 0x2c70 0x2c70 0x2c70 0x2c70 0x2c70 0x2c70 0x2c70 0x2c70 0x2c70 0x2c70 0x2c70 0x2c70 0x2c70 0x2c70 0x2c70 0x2c70 0x2c70 0x2c70 0x2c70 0x2c70 0x2c70 0x2c70 0x2c70 0x2c70 0x2c70 0x2c70 0x2c70 0x2c70 0x2c70 0x2c70 0x2c70 0x2c70 0x2c70 0x2c70 0x2c70 0x2c70 0x2c70 0x2c70 0x2c70 0x2c70 0x2c70 0x2c70 0x2c70 0x2c70 0x2c70 0x2c70 0x2c70 0x2c70 0x2c70 0x2c70 0x2c70 0x2c70 0x2c70 0x2c70 0x2c70 0x2c70 0x2c70 0x2c70 0x2c70 0x2c70 0x2c70 0x2c70 0x2c70 0x2c70 0x2c70 0x2c70 0x2c70 0x2c70 0x2c70 0x2c70 0x2c70 0x2c70 0x2c70 0x2c70 0x2c70 0x2c70 0x2c70 0x2c70 0x2c70 0x2c70 0x2c70 0x2c70 0x2c70 0x2c70 0x2c70 0x2c70 0x2c70 0x2c70 0x2c70 0x2c70 0x2c70 0x2c70 0x2c70 0x2c70 0x2d1e 0x2d1e 0x2d1e>;
                PS_Config_Lmt_Short_Diff_P = <0x189c 0x189c 0x189c 0x189c 0x189c 0x189c 0x189c 0x189c 0x189c 0x189c 0x189c 0x189c 0x189c 0x189c 0x189c 0x189c 0x189c 0x189c 0x189c 0x189c 0x189c 0x189c 0x189c 0x189c 0x189c 0x189c 0x189c 0x189c 0x189c 0x189c 0x189c 0x189c 0x189c 0x189c 0x189c 0x189c 0x189c 0x189c 0x189c 0x189c 0x189c 0x189c 0x189c 0x189c 0x189c 0x189c 0x189c 0x189c 0x189c 0x189c 0x189c 0x189c 0x189c 0x189c 0x189c 0x189c 0x189c 0x189c 0x189c 0x189c 0x189c 0x189c 0x189c 0x189c 0x189c 0x189c 0x189c 0x189c 0x189c 0x189c 0x189c 0x189c 0x189c 0x189c 0x189c 0x189c 0x189c 0x189c 0x189c 0x189c 0x189c 0x189c 0x189c 0x189c 0x189c 0x189c 0x189c 0x189c 0x189c 0x189c 0x189c 0x189c 0x189c 0x189c 0x189c 0x189c 0x189c 0x189c 0x189c 0x189c 0x189c 0x189c 0x189c 0x189c 0x189c 0x189c 0x189c 0x189c 0x189c 0x189c 0x189c 0x189c 0x189c 0x189c 0x189c 0x189c 0x189c 0x189c 0x189c 0x189c 0x189c 0x189c 0x189c 0x189c 0x189c 0x189c 0x189c 0x189c 0x189c 0x189c 0x189c 0x189c 0x189c 0x189c 0x189c 0x189c 0x189c 0x189c 0x189c 0x189c 0x189c 0x189c 0x189c 0x189c 0x189c 0x189c 0x189c 0x189c 0x189c 0x189c 0x189c 0x189c 0x189c 0x189c 0x189c 0x189c 0x189c 0x189c 0x189c 0x189c 0x189c 0x189c 0x189c 0x189c 0x189c 0x189c 0x189c 0x189c 0x189c 0x189c 0x189c 0x189c 0x189c 0x189c 0x189c 0x189c 0x189c 0x189c 0x189c 0x189c 0x189c 0x189c 0x189c 0x189c 0x189c 0x189c 0x189c 0x189c 0x189c 0x189c 0x189c 0x189c 0x189c 0x189c 0x189c 0x189c 0x189c 0x189c 0x189c 0x189c 0x189c 0x189c 0x189c 0x189c 0x189c 0x189c 0x189c 0x189c 0x189c 0x189c 0x189c 0x189c 0x189c 0x189c 0x189c 0x189c 0x189c 0x189c 0x189c 0x189c 0x189c 0x189c 0x189c 0x189c 0x189c 0x189c 0x189c 0x189c 0x189c 0x189c 0x189c 0x189c 0x189c 0x189c 0x189c 0x189c 0x189c 0x189c 0x189c 0x189c 0x189c 0x189c 0x189c 0x189c 0x189c 0x189c 0x189c 0x189c 0x189c 0x189c 0x189c 0x189c 0x189c 0x189c 0x189c 0x189c 0x189c 0x189c 0x189c 0x189c 0x189c 0x189c 0x189c 0x189c 0x189c 0x189c 0x189c 0x189c 0x189c 0x189c 0x189c 0x189c 0x189c 0x189c 0x189c 0x189c 0x189c 0x189c 0x189c 0x189c 0x189c 0x189c 0x189c 0x189c 0x189c 0x189c 0x189c 0x189c 0x189c 0x189c 0x189c 0x189c 0x189c 0x189c 0x189c 0x189c 0x189c 0x189c 0x189c 0x189c 0x189c 0x189c 0x189c 0x189c 0x189c 0x189c 0x189c 0x189c 0x189c 0x189c 0x189c 0x189c 0x189c 0x189c 0x189c 0x189c 0x189c 0x189c 0x189c 0x189c 0x189c 0x189c 0x189c 0x189c 0x189c 0x189c 0x189c 0x189c 0x189c 0x189c 0x189c 0x189c 0x189c 0x189c 0x189c 0x189c 0x189c 0x189c 0x189c 0x189c 0x189c 0x189c 0x189c 0x189c 0x189c 0x189c 0x189c 0x189c 0x189c 0x189c 0x189c 0x189c 0x189c 0x189c 0x189c 0x189c 0x189c 0x189c 0x189c 0x189c 0x189c 0x189c 0x189c 0x189c 0x189c 0x189c 0x189c 0x189c 0x189c 0x189c 0x189c 0x189c 0x189c 0x189c 0x189c 0x189c 0x189c 0x189c 0x189c 0x189c 0x189c 0x189c 0x189c 0x189c 0x189c 0x189c 0x189c 0x189c 0x189c 0x189c 0x189c 0x189c 0x189c 0x189c 0x189c 0x189c 0x189c 0x189c 0x189c 0x189c 0x189c 0x189c 0x189c 0x189c 0x189c 0x189c 0x189c 0x189c 0x189c 0x189c 0x189c 0x189c 0x189c 0x189c 0x189c 0x189c 0x189c 0x189c 0x189c 0x189c 0x189c 0x189c 0x189c 0x189c 0x189c 0x189c 0x189c 0x189c 0x189c 0x189c 0x189c 0x189c 0x189c 0x189c 0x189c 0x189c 0x189c 0x189c 0x189c 0x189c 0x189c 0x189c 0x189c 0x189c 0x189c 0x189c 0x189c 0x189c 0x189c 0x189c 0x189c 0x189c 0x189c 0x189c 0x189c 0x189c 0x189c 0x189c 0x189c 0x189c 0x189c 0x189c 0x189c 0x189c 0x189c 0x189c 0x189c 0x189c 0x189c 0x189c 0x189c 0x189c 0x189c 0x189c 0x189c 0x189c 0x189c 0x189c 0x189c 0x189c 0x189c 0x189c 0x189c 0x189c 0x189c 0x189c 0x189c 0x189c 0x189c 0x189c 0x189c 0x189c 0x189c 0x189c 0x189c 0x189c 0x189c 0x189c 0x189c 0x189c 0x189c 0x189c 0x189c 0x189c 0x189c 0x189c 0x189c 0x189c 0x189c 0x189c 0x189c 0x189c 0x189c 0x189c 0x189c 0x189c 0x189c 0x189c 0x189c 0x189c 0x189c 0x189c 0x189c 0x189c 0x189c 0x189c 0x189c 0x189c 0x189c 0x189c 0x189c 0x189c 0x189c 0x189c 0x189c 0x189c 0x189c 0x189c 0x189c 0x189c 0x189c 0x189c 0x189c 0x189c 0x189c 0x189c 0x189c 0x189c 0x189c 0x189c 0x189c 0x189c 0x189c 0x189c 0x189c 0x189c 0x189c 0x189c 0x189c 0x189c 0x189c 0x189c 0x189c 0x189c 0x189c 0x189c 0x189c 0x189c 0x189c 0x189c 0x189c 0x189c 0x189c 0x189c 0x189c 0x189c 0x189c 0x189c 0x189c>;
                PS_Config_Lmt_Short_Diff_N = <0x00 0x00 0x00 0x00 0x00 0x00 0x00 0x00 0x00 0x00 0x00 0x00 0x00 0x00 0x00 0x00 0x00 0x00 0x00 0x00 0x00 0x00 0x00 0x00 0x00 0x00 0x00 0x00 0x00 0x00 0x00 0x00 0x00 0x00 0x00 0x00 0x00 0x00 0x00 0x00 0x00 0x00 0x00 0x00 0x00 0x00 0x00 0x00 0x00 0x00 0x00 0x00 0x00 0x00 0x00 0x00 0x00 0x00 0x00 0x00 0x00 0x00 0x00 0x00 0x00 0x00 0x00 0x00 0x00 0x00 0x00 0x00 0x00 0x00 0x00 0x00 0x00 0x00 0x00 0x00 0x00 0x00 0x00 0x00 0x00 0x00 0x00 0x00 0x00 0x00 0x00 0x00 0x00 0x00 0x00 0x00 0x00 0x00 0x00 0x00 0x00 0x00 0x00 0x00 0x00 0x00 0x00 0x00 0x00 0x00 0x00 0x00 0x00 0x00 0x00 0x00 0x00 0x00 0x00 0x00 0x00 0x00 0x00 0x00 0x00 0x00 0x00 0x00 0x00 0x00 0x00 0x00 0x00 0x00 0x00 0x00 0x00 0x00 0x00 0x00 0x00 0x00 0x00 0x00 0x00 0x00 0x00 0x00 0x00 0x00 0x00 0x00 0x00 0x00 0x00 0x00 0x00 0x00 0x00 0x00 0x00 0x00 0x00 0x00 0x00 0x00 0x00 0x00 0x00 0x00 0x00 0x00 0x00 0x00 0x00 0x00 0x00 0x00 0x00 0x00 0x00 0x00 0x00 0x00 0x00 0x00 0x00 0x00 0x00 0x00 0x00 0x00 0x00 0x00 0x00 0x00 0x00 0x00 0x00 0x00 0x00 0x00 0x00 0x00 0x00 0x00 0x00 0x00 0x00 0x00 0x00 0x00 0x00 0x00 0x00 0x00 0x00 0x00 0x00 0x00 0x00 0x00 0x00 0x00 0x00 0x00 0x00 0x00 0x00 0x00 0x00 0x00 0x00 0x00 0x00 0x00 0x00 0x00 0x00 0x00 0x00 0x00 0x00 0x00 0x00 0x00 0x00 0x00 0x00 0x00 0x00 0x00 0x00 0x00 0x00 0x00 0x00 0x00 0x00 0x00 0x00 0x00 0x00 0x00 0x00 0x00 0x00 0x00 0x00 0x00 0x00 0x00 0x00 0x00 0x00 0x00 0x00 0x00 0x00 0x00 0x00 0x00 0x00 0x00 0x00 0x00 0x00 0x00 0x00 0x00 0x00 0x00 0x00 0x00 0x00 0x00 0x00 0x00 0x00 0x00 0x00 0x00 0x00 0x00 0x00 0x00 0x00 0x00 0x00 0x00 0x00 0x00 0x00 0x00 0x00 0x00 0x00 0x00 0x00 0x00 0x00 0x00 0x00 0x00 0x00 0x00 0x00 0x00 0x00 0x00 0x00 0x00 0x00 0x00 0x00 0x00 0x00 0x00 0x00 0x00 0x00 0x00 0x00 0x00 0x00 0x00 0x00 0x00 0x00 0x00 0x00 0x00 0x00 0x00 0x00 0x00 0x00 0x00 0x00 0x00 0x00 0x00 0x00 0x00 0x00 0x00 0x00 0x00 0x00 0x00 0x00 0x00 0x00 0x00 0x00 0x00 0x00 0x00 0x00 0x00 0x00 0x00 0x00 0x00 0x00 0x00 0x00 0x00 0x00 0x00 0x00 0x00 0x00 0x00 0x00 0x00 0x00 0x00 0x00 0x00 0x00 0x00 0x00 0x00 0x00 0x00 0x00 0x00 0x00 0x00 0x00 0x00 0x00 0x00 0x00 0x00 0x00 0x00 0x00 0x00 0x00 0x00 0x00 0x00 0x00 0x00 0x00 0x00 0x00 0x00 0x00 0x00 0x00 0x00 0x00 0x00 0x00 0x00 0x00 0x00 0x00 0x00 0x00 0x00 0x00 0x00 0x00 0x00 0x00 0x00 0x00 0x00 0x00 0x00 0x00 0x00 0x00 0x00 0x00 0x00 0x00 0x00 0x00 0x00 0x00 0x00 0x00 0x00 0x00 0x00 0x00 0x00 0x00 0x00 0x00 0x00 0x00 0x00 0x00 0x00 0x00 0x00 0x00 0x00 0x00 0x00 0x00 0x00 0x00 0x00 0x00 0x00 0x00 0x00 0x00 0x00 0x00 0x00 0x00 0x00 0x00 0x00 0x00 0x00 0x00 0x00 0x00 0x00 0x00 0x00 0x00 0x00 0x00 0x00 0x00 0x00 0x00 0x00 0x00 0x00 0x00 0x00 0x00 0x00 0x00 0x00 0x00 0x00 0x00 0x00 0x00 0x00 0x00 0x00 0x00 0x00 0x00 0x00 0x00 0x00 0x00 0x00 0x00 0x00 0x00 0x00 0x00 0x00 0x00 0x00 0x00 0x00 0x00 0x00 0x00 0x00 0x00 0x00 0x00 0x00 0x00 0x00 0x00 0x00 0x00 0x00 0x00 0x00 0x00 0x00 0x00 0x00 0x00 0x00 0x00 0x00 0x00 0x00 0x00>;
                PS_Config_Lmt_Short_Base_P = <0x7d0 0x7d0 0x7d0 0x7d0 0x7d0 0x7d0 0x7d0 0x7d0 0x7d0 0x7d0 0x7d0 0x7d0 0x7d0 0x7d0 0x7d0 0x7d0 0x7d0 0x7d0 0x7d0 0x7d0 0x7d0 0x7d0 0x7d0 0x7d0 0x7d0 0x7d0 0x7d0 0x7d0 0x7d0 0x7d0 0x7d0 0x7d0 0x7d0 0x7d0 0x7d0 0x7d0 0x7d0 0x7d0 0x7d0 0x7d0 0x7d0 0x7d0 0x7d0 0x7d0 0x7d0 0x7d0 0x7d0 0x7d0 0x7d0 0x7d0 0x7d0 0x7d0 0x7d0 0x7d0 0x7d0 0x7d0 0x7d0 0x7d0 0x7d0 0x7d0 0x7d0 0x7d0 0x7d0 0x7d0 0x7d0 0x7d0 0x7d0 0x7d0 0x7d0 0x7d0 0x7d0 0x7d0 0x7d0 0x7d0 0x7d0 0x7d0 0x7d0 0x7d0 0x7d0 0x7d0 0x7d0 0x7d0 0x7d0 0x7d0 0x7d0 0x7d0 0x7d0 0x7d0 0x7d0 0x7d0 0x7d0 0x7d0 0x7d0 0x7d0 0x7d0 0x7d0 0x7d0 0x7d0 0x7d0 0x7d0 0x7d0 0x7d0 0x7d0 0x7d0 0x7d0 0x7d0 0x7d0 0x7d0 0x7d0 0x7d0 0x7d0 0x7d0 0x7d0 0x7d0 0x7d0 0x7d0 0x7d0 0x7d0 0x7d0 0x7d0 0x7d0 0x7d0 0x7d0 0x7d0 0x7d0 0x7d0 0x7d0 0x7d0 0x7d0 0x7d0 0x7d0 0x7d0 0x7d0 0x7d0 0x7d0 0x7d0 0x7d0 0x7d0 0x7d0 0x7d0 0x7d0 0x7d0 0x7d0 0x7d0 0x7d0 0x7d0 0x7d0 0x7d0 0x7d0 0x7d0 0x7d0 0x7d0 0x7d0 0x7d0 0x7d0 0x7d0 0x7d0 0x7d0 0x7d0 0x7d0 0x7d0 0x7d0 0x7d0 0x7d0 0x7d0 0x7d0 0x7d0 0x7d0 0x7d0 0x7d0 0x7d0 0x7d0 0x7d0 0x7d0 0x7d0 0x7d0 0x7d0 0x7d0 0x7d0 0x7d0 0x7d0 0x7d0 0x7d0 0x7d0 0x7d0 0x7d0 0x7d0 0x7d0 0x7d0 0x7d0 0x7d0 0x7d0 0x7d0 0x7d0 0x7d0 0x7d0 0x7d0 0x7d0 0x7d0 0x7d0 0x7d0 0x7d0 0x7d0 0x7d0 0x7d0 0x7d0 0x7d0 0x7d0 0x7d0 0x7d0 0x7d0 0x7d0 0x7d0 0x7d0 0x7d0 0x7d0 0x7d0 0x7d0 0x7d0 0x7d0 0x7d0 0x7d0 0x7d0 0x7d0 0x7d0 0x7d0 0x7d0 0x7d0 0x7d0 0x7d0 0x7d0 0x7d0 0x7d0 0x7d0 0x7d0 0x7d0 0x7d0 0x7d0 0x7d0 0x7d0 0x7d0 0x7d0 0x7d0 0x7d0 0x7d0 0x7d0 0x7d0 0x7d0 0x7d0 0x7d0 0x7d0 0x7d0 0x7d0 0x7d0 0x7d0 0x7d0 0x7d0 0x7d0 0x7d0 0x7d0 0x7d0 0x7d0 0x7d0 0x7d0 0x7d0 0x7d0 0x7d0 0x7d0 0x7d0 0x7d0 0x7d0 0x7d0 0x7d0 0x7d0 0x7d0 0x7d0 0x7d0 0x7d0 0x7d0 0x7d0 0x7d0 0x7d0 0x7d0 0x7d0 0x7d0 0x7d0 0x7d0 0x7d0 0x7d0 0x7d0 0x7d0 0x7d0 0x7d0 0x7d0 0x7d0 0x7d0 0x7d0 0x7d0 0x7d0 0x7d0 0x7d0 0x7d0 0x7d0 0x7d0 0x7d0 0x7d0 0x7d0 0x7d0 0x7d0 0x7d0 0x7d0 0x7d0 0x7d0 0x7d0 0x7d0 0x7d0 0x7d0 0x7d0 0x7d0 0x7d0 0x7d0 0x7d0 0x7d0 0x7d0 0x7d0 0x7d0 0x7d0 0x7d0 0x7d0 0x7d0 0x7d0 0x7d0 0x7d0 0x7d0 0x7d0 0x7d0 0x7d0 0x7d0 0x7d0 0x7d0 0x7d0 0x7d0 0x7d0 0x7d0 0x7d0 0x7d0 0x7d0 0x7d0 0x7d0 0x7d0 0x7d0 0x7d0 0x7d0 0x7d0 0x7d0 0x7d0 0x7d0 0x7d0 0x7d0 0x7d0 0x7d0 0x7d0 0x7d0 0x7d0 0x7d0 0x7d0 0x7d0 0x7d0 0x7d0 0x7d0 0x7d0 0x7d0 0x7d0 0x7d0 0x7d0 0x7d0 0x7d0 0x7d0 0x7d0 0x7d0 0x7d0 0x7d0 0x7d0 0x7d0 0x7d0 0x7d0 0x7d0 0x7d0 0x7d0 0x7d0 0x7d0 0x7d0 0x7d0 0x7d0 0x7d0 0x7d0 0x7d0 0x7d0 0x7d0 0x7d0 0x7d0 0x7d0 0x7d0 0x7d0 0x7d0 0x7d0 0x7d0 0x7d0 0x7d0 0x7d0 0x7d0 0x7d0 0x7d0 0x7d0 0x7d0 0x7d0 0x7d0 0x7d0 0x7d0 0x7d0 0x7d0 0x7d0 0x7d0 0x7d0 0x7d0 0x7d0 0x7d0 0x7d0 0x7d0 0x7d0 0x7d0 0x7d0 0x7d0 0x7d0 0x7d0 0x7d0 0x7d0 0x7d0 0x7d0 0x7d0 0x7d0 0x7d0 0x7d0 0x7d0 0x7d0 0x7d0 0x7d0 0x7d0 0x7d0 0x7d0 0x7d0 0x7d0 0x7d0 0x7d0 0x7d0 0x7d0 0x7d0 0x7d0 0x7d0 0x7d0 0x7d0 0x7d0 0x7d0 0x7d0 0x7d0 0x7d0 0x7d0 0x7d0 0x7d0 0x7d0 0x7d0 0x7d0 0x7d0 0x7d0 0x7d0 0x7d0 0x7d0 0x7d0 0x7d0 0x7d0 0x7d0 0x7d0 0x7d0 0x7d0 0x7d0 0x7d0 0x7d0 0x7d0 0x7d0 0x7d0 0x7d0 0x7d0 0x7d0 0x7d0 0x7d0 0x7d0 0x7d0 0x7d0 0x7d0 0x7d0 0x7d0 0x7d0 0x7d0 0x7d0 0x7d0 0x7d0 0x7d0 0x7d0 0x7d0 0x7d0 0x7d0 0x7d0 0x7d0 0x7d0 0x7d0 0x7d0 0x7d0 0x7d0 0x7d0 0x7d0 0x7d0 0x7d0 0x7d0 0x7d0 0x7d0 0x7d0 0x7d0 0x7d0 0x7d0 0x7d0 0x7d0 0x7d0 0x7d0 0x7d0 0x7d0 0x7d0 0x7d0 0x7d0 0x7d0 0x7d0 0x7d0 0x7d0 0x7d0 0x7d0 0x7d0 0x7d0 0x7d0 0x7d0 0x7d0 0x7d0 0x7d0 0x7d0 0x7d0 0x7d0 0x7d0 0x7d0 0x7d0 0x7d0 0x7d0 0x7d0 0x7d0 0x7d0 0x7d0 0x7d0 0x7d0 0x7d0 0x7d0 0x7d0 0x7d0 0x7d0 0x7d0 0x7d0 0x7d0 0x7d0 0x7d0 0x7d0 0x7d0 0x7d0 0x7d0>;
                PS_Config_Lmt_Short_Base_N = <0xfffff830 0xfffff830 0xfffff830 0xfffff830 0xfffff830 0xfffff830 0xfffff830 0xfffff830 0xfffff830 0xfffff830 0xfffff830 0xfffff830 0xfffff830 0xfffff830 0xfffff830 0xfffff830 0xfffff830 0xfffff830 0xfffff830 0xfffff830 0xfffff830 0xfffff830 0xfffff830 0xfffff830 0xfffff830 0xfffff830 0xfffff830 0xfffff830 0xfffff830 0xfffff830 0xfffff830 0xfffff830 0xfffff830 0xfffff830 0xfffff830 0xfffff830 0xfffff830 0xfffff830 0xfffff830 0xfffff830 0xfffff830 0xfffff830 0xfffff830 0xfffff830 0xfffff830 0xfffff830 0xfffff830 0xfffff830 0xfffff830 0xfffff830 0xfffff830 0xfffff830 0xfffff830 0xfffff830 0xfffff830 0xfffff830 0xfffff830 0xfffff830 0xfffff830 0xfffff830 0xfffff830 0xfffff830 0xfffff830 0xfffff830 0xfffff830 0xfffff830 0xfffff830 0xfffff830 0xfffff830 0xfffff830 0xfffff830 0xfffff830 0xfffff830 0xfffff830 0xfffff830 0xfffff830 0xfffff830 0xfffff830 0xfffff830 0xfffff830 0xfffff830 0xfffff830 0xfffff830 0xfffff830 0xfffff830 0xfffff830 0xfffff830 0xfffff830 0xfffff830 0xfffff830 0xfffff830 0xfffff830 0xfffff830 0xfffff830 0xfffff830 0xfffff830 0xfffff830 0xfffff830 0xfffff830 0xfffff830 0xfffff830 0xfffff830 0xfffff830 0xfffff830 0xfffff830 0xfffff830 0xfffff830 0xfffff830 0xfffff830 0xfffff830 0xfffff830 0xfffff830 0xfffff830 0xfffff830 0xfffff830 0xfffff830 0xfffff830 0xfffff830 0xfffff830 0xfffff830 0xfffff830 0xfffff830 0xfffff830 0xfffff830 0xfffff830 0xfffff830 0xfffff830 0xfffff830 0xfffff830 0xfffff830 0xfffff830 0xfffff830 0xfffff830 0xfffff830 0xfffff830 0xfffff830 0xfffff830 0xfffff830 0xfffff830 0xfffff830 0xfffff830 0xfffff830 0xfffff830 0xfffff830 0xfffff830 0xfffff830 0xfffff830 0xfffff830 0xfffff830 0xfffff830 0xfffff830 0xfffff830 0xfffff830 0xfffff830 0xfffff830 0xfffff830 0xfffff830 0xfffff830 0xfffff830 0xfffff830 0xfffff830 0xfffff830 0xfffff830 0xfffff830 0xfffff830 0xfffff830 0xfffff830 0xfffff830 0xfffff830 0xfffff830 0xfffff830 0xfffff830 0xfffff830 0xfffff830 0xfffff830 0xfffff830 0xfffff830 0xfffff830 0xfffff830 0xfffff830 0xfffff830 0xfffff830 0xfffff830 0xfffff830 0xfffff830 0xfffff830 0xfffff830 0xfffff830 0xfffff830 0xfffff830 0xfffff830 0xfffff830 0xfffff830 0xfffff830 0xfffff830 0xfffff830 0xfffff830 0xfffff830 0xfffff830 0xfffff830 0xfffff830 0xfffff830 0xfffff830 0xfffff830 0xfffff830 0xfffff830 0xfffff830 0xfffff830 0xfffff830 0xfffff830 0xfffff830 0xfffff830 0xfffff830 0xfffff830 0xfffff830 0xfffff830 0xfffff830 0xfffff830 0xfffff830 0xfffff830 0xfffff830 0xfffff830 0xfffff830 0xfffff830 0xfffff830 0xfffff830 0xfffff830 0xfffff830 0xfffff830 0xfffff830 0xfffff830 0xfffff830 0xfffff830 0xfffff830 0xfffff830 0xfffff830 0xfffff830 0xfffff830 0xfffff830 0xfffff830 0xfffff830 0xfffff830 0xfffff830 0xfffff830 0xfffff830 0xfffff830 0xfffff830 0xfffff830 0xfffff830 0xfffff830 0xfffff830 0xfffff830 0xfffff830 0xfffff830 0xfffff830 0xfffff830 0xfffff830 0xfffff830 0xfffff830 0xfffff830 0xfffff830 0xfffff830 0xfffff830 0xfffff830 0xfffff830 0xfffff830 0xfffff830 0xfffff830 0xfffff830 0xfffff830 0xfffff830 0xfffff830 0xfffff830 0xfffff830 0xfffff830 0xfffff830 0xfffff830 0xfffff830 0xfffff830 0xfffff830 0xfffff830 0xfffff830 0xfffff830 0xfffff830 0xfffff830 0xfffff830 0xfffff830 0xfffff830 0xfffff830 0xfffff830 0xfffff830 0xfffff830 0xfffff830 0xfffff830 0xfffff830 0xfffff830 0xfffff830 0xfffff830 0xfffff830 0xfffff830 0xfffff830 0xfffff830 0xfffff830 0xfffff830 0xfffff830 0xfffff830 0xfffff830 0xfffff830 0xfffff830 0xfffff830 0xfffff830 0xfffff830 0xfffff830 0xfffff830 0xfffff830 0xfffff830 0xfffff830 0xfffff830 0xfffff830 0xfffff830 0xfffff830 0xfffff830 0xfffff830 0xfffff830 0xfffff830 0xfffff830 0xfffff830 0xfffff830 0xfffff830 0xfffff830 0xfffff830 0xfffff830 0xfffff830 0xfffff830 0xfffff830 0xfffff830 0xfffff830 0xfffff830 0xfffff830 0xfffff830 0xfffff830 0xfffff830 0xfffff830 0xfffff830 0xfffff830 0xfffff830 0xfffff830 0xfffff830 0xfffff830 0xfffff830 0xfffff830 0xfffff830 0xfffff830 0xfffff830 0xfffff830 0xfffff830 0xfffff830 0xfffff830 0xfffff830 0xfffff830 0xfffff830 0xfffff830 0xfffff830 0xfffff830 0xfffff830 0xfffff830 0xfffff830 0xfffff830 0xfffff830 0xfffff830 0xfffff830 0xfffff830 0xfffff830 0xfffff830 0xfffff830 0xfffff830 0xfffff830 0xfffff830 0xfffff830 0xfffff830 0xfffff830 0xfffff830 0xfffff830 0xfffff830 0xfffff830 0xfffff830 0xfffff830 0xfffff830 0xfffff830 0xfffff830 0xfffff830 0xfffff830 0xfffff830 0xfffff830 0xfffff830 0xfffff830 0xfffff830 0xfffff830 0xfffff830 0xfffff830 0xfffff830 0xfffff830 0xfffff830 0xfffff830 0xfffff830 0xfffff830 0xfffff830 0xfffff830 0xfffff830 0xfffff830 0xfffff830 0xfffff830 0xfffff830 0xfffff830 0xfffff830 0xfffff830 0xfffff830 0xfffff830 0xfffff830 0xfffff830 0xfffff830 0xfffff830 0xfffff830 0xfffff830 0xfffff830 0xfffff830 0xfffff830 0xfffff830 0xfffff830 0xfffff830 0xfffff830 0xfffff830 0xfffff830 0xfffff830 0xfffff830 0xfffff830 0xfffff830 0xfffff830 0xfffff830 0xfffff830 0xfffff830 0xfffff830 0xfffff830 0xfffff830 0xfffff830 0xfffff830 0xfffff830 0xfffff830 0xfffff830 0xfffff830 0xfffff830 0xfffff830 0xfffff830 0xfffff830 0xfffff830 0xfffff830 0xfffff830 0xfffff830 0xfffff830 0xfffff830 0xfffff830 0xfffff830 0xfffff830 0xfffff830 0xfffff830 0xfffff830 0xfffff830 0xfffff830 0xfffff830 0xfffff830 0xfffff830 0xfffff830 0xfffff830 0xfffff830 0xfffff830 0xfffff830 0xfffff830 0xfffff830 0xfffff830 0xfffff830 0xfffff830 0xfffff830 0xfffff830 0xfffff830 0xfffff830 0xfffff830 0xfffff830 0xfffff830 0xfffff830 0xfffff830 0xfffff830 0xfffff830 0xfffff830 0xfffff830 0xfffff830 0xfffff830 0xfffff830 0xfffff830 0xfffff830 0xfffff830 0xfffff830 0xfffff830 0xfffff830 0xfffff830 0xfffff830 0xfffff830 0xfffff830 0xfffff830 0xfffff830 0xfffff830 0xfffff830 0xfffff830 0xfffff830 0xfffff830 0xfffff830 0xfffff830 0xfffff830 0xfffff830 0xfffff830 0xfffff830 0xfffff830 0xfffff830 0xfffff830 0xfffff830 0xfffff830 0xfffff830 0xfffff830 0xfffff830 0xfffff830 0xfffff830 0xfffff830 0xfffff830 0xfffff830 0xfffff830 0xfffff830 0xfffff830 0xfffff830 0xfffff830 0xfffff830 0xfffff830 0xfffff830 0xfffff830 0xfffff830 0xfffff830 0xfffff830 0xfffff830 0xfffff830 0xfffff830 0xfffff830 0xfffff830 0xfffff830 0xfffff830 0xfffff830 0xfffff830 0xfffff830 0xfffff830 0xfffff830 0xfffff830 0xfffff830 0xfffff830 0xfffff830 0xfffff830 0xfffff830 0xfffff830 0xfffff830 0xfffff830 0xfffff830 0xfffff830 0xfffff830 0xfffff830 0xfffff830 0xfffff830 0xfffff830 0xfffff830 0xfffff830 0xfffff830 0xfffff830 0xfffff830 0xfffff830>;
                PS_Config_Lmt_Open_Rawdata_P = <0x12f8 0x1177 0xf32 0xcd9 0xb1a 0xffff 0xffff 0xffff 0xffff 0xffff 0xffff 0xffff 0xffff 0xa5c 0xc3b 0xe97 0x10e2 0x127e 0x9e2 0xc74 0xc3d 0xbdd 0xbad 0xdfb 0xc20 0xc20 0xc11 0xbeb 0xc01 0xc06 0xdc4 0xc79 0xcaa 0xd09 0xd46 0xa32 0xb72 0xc49 0xc32 0xbf7 0xbe7 0xbcc 0xbcd 0xbd5 0xbc7 0xba6 0xbc0 0xbbf 0xbc4 0xbdf 0xbf3 0xc36 0xc52 0xbb7 0xb12 0xc33 0xc28 0xbed 0xbe0 0xbd9 0xbdc 0xbe3 0xbd6 0xbc7 0xbc8 0xbd2 0xbd6 0xbdc 0xbf0 0xc31 0xc4f 0xb45 0xb0b 0xc4e 0xc35 0xbfa 0xbe3 0xbb7 0xbbb 0xbc3 0xbb8 0xba9 0xbb6 0xbb5 0xbb8 0xbed 0xc02 0xc44 0xc60 0xb47 0xb12 0xc26 0xc02 0xbd4 0xbae 0xba9 0xbaf 0xbb8 0xbad 0xb9e 0xbaa 0xb9a 0xbaa 0xbb4 0xbe2 0xc23 0xc40 0xb55 0xaed 0xc16 0xbf9 0xbc3 0xb9d 0xb9f 0xba5 0xbad 0xba3 0xb8d 0xb99 0xb97 0xb98 0xba6 0xbd2 0xc13 0xc2f 0xb37 0xade 0xc0c 0xbdb 0xbac 0xb91 0xba4 0xbab 0xbb0 0xba7 0xb96 0xba0 0xba2 0xb95 0xb93 0xbc0 0xbec 0xc1c 0xb25 0xad7 0xc13 0xbe2 0xbbd 0xb95 0xb96 0xb9e 0xba2 0xb9c 0xb90 0xb99 0xb9f 0xb9e 0xb99 0xbc3 0xbe9 0xc1e 0xb0d 0xad6 0xc03 0xbd1 0xb97 0xb7a 0xba8 0xbb2 0xbb5 0xbb0 0xb95 0xb9e 0xba5 0xba3 0xb86 0xbab 0xbe4 0xc19 0xb10 0xac4 0xc14 0xbe3 0xba9 0xb9a 0xb7d 0xb90 0xb98 0xb93 0xb6e 0xb7a 0xb7c 0xb79 0xb95 0xb9b 0xbe6 0xc1b 0xb0b 0xacf 0xbef 0xbc0 0xb84 0xb78 0xb64 0xb6d 0xb75 0xb74 0xb57 0xb62 0xb65 0xb63 0xb6a 0xb7d 0xbbc 0xbf1 0xb09 0xaac 0xbc5 0xb9b 0xb62 0xb52 0xb52 0xb4b 0xb61 0xb62 0xb3d 0xb4b 0xb4c 0xb4b 0xb56 0xb69 0xb9a 0xbda 0xadd 0xa83 0xb9f 0xb87 0xb4d 0xb3e 0xb43 0xb4b 0xb52 0xb55 0xb40 0xb53 0xb50 0xb4f 0xb3c 0xb4f 0xb8b 0xbac 0xabe 0xa6d 0xb91 0xb64 0xb41 0xb30 0xb37 0xb3f 0xb36 0xb49 0xb33 0xb47 0xb48 0xb45 0xb3c 0xb4f 0xb7a 0xb99 0xaa1 0xa5a 0xb81 0xb54 0xb2f 0xb20 0xb25 0xb2c 0xb32 0xb34 0xb0c 0xb1d 0xb21 0xb1c 0xb2f 0xb40 0xb68 0xb98 0xa9b 0xa47 0xb6d 0xb3f 0xb1c 0xb0a 0xb05 0xb10 0xb16 0xb0c 0xb0f 0xb25 0xb25 0xb20 0xb05 0xb16 0xb3d 0xb6d 0xa7d 0xa30 0xb4c 0xb1d 0xaf9 0xaeb 0xaea 0xaf3 0xaf4 0xafa 0xaea 0xaf8 0xafc 0xaf8 0xb0b 0xb1b 0xb41 0xb73 0xa5e 0xa0c 0xb28 0xb01 0xadd 0xacc 0xae1 0xaea 0xaee 0xaf2 0xac8 0xadb 0xad9 0xad8 0xae3 0xaf2 0xb19 0xb49 0xa5c 0x9d4 0xb0e 0xaf6 0xad1 0xac1 0xac7 0xad1 0xad8 0xad8 0xab1 0xad0 0xace 0xace 0xac0 0xacf 0xaf7 0xb17 0xa33 0x9de 0xaf3 0xadd 0xab9 0xaaa 0xaa3 0xaaa 0xab0 0xab5 0xabb 0xabf 0xabd 0xabc 0xab0 0xac1 0xae9 0xb04 0xa0c 0x9c4 0xab9 0xab3 0xa92 0xa84 0xa8e 0xa95 0xa9b 0xaa0 0xa9c 0xa90 0xaa4 0xa9f 0xaa0 0xab2 0xad9 0xaf5 0x9fd 0x99a 0xab8 0xa9e 0xa7c 0xa6f 0xa7a 0xa83 0xa86 0xa8d 0xa7e 0xa89 0xa84 0xa80 0xa84 0xa95 0xabe 0xad8 0x9e9 0x981 0xaa3 0xa77 0xa65 0xa5a 0xa51 0xa5d 0xa5f 0xa66 0xa59 0xa64 0xa4f 0xa59 0xa67 0xa78 0xaa1 0xaba 0x9c5 0x968 0xa7a 0xa60 0xa3a 0xa2f 0xa2c 0xa39 0xa3d 0xa40 0xa3c 0xa4c 0xa48 0xa3e 0xa3d 0xa4f 0xa78 0xa91 0x9a0 0x93c 0xa5a 0xa40 0xa09 0xa0c 0xa21 0xa2e 0xa35 0xa2e 0xa2d 0xa41 0xa3c 0xa22 0xa20 0xa31 0xa59 0xa73 0x975 0x917 0xa4c 0xa35 0xa0d 0x9f1 0xa1e 0xa29 0xa33 0xa2c 0xa26 0xa43 0xa3a 0xa34 0xa01 0xa1f 0xa4b 0xa63 0x955 0x902 0xa47 0xa2f 0xa08 0x9fd 0x9ee 0x9f7 0x9fe 0x9eb 0x9e9 0xa06 0x9fb 0x9f7 0xa12 0xa1e 0xa4b 0xa63 0x942 0x8f8 0xa14 0x9fe 0x9d6 0x9cc 0x9b6 0x9ce 0x9d7 0x9c0 0x9d3 0x9e9 0x9e8 0x9e2 0x9d4 0x9d4 0xa0d 0xa23 0x93a 0x8c3 0x9ea 0x9d2 0x9ad 0x9a1 0x997 0x9a4 0x9ab 0x997 0x9ae 0x9c1 0x9c1 0x9b7 0x9c2 0x9ce 0x9f6 0xa0e 0x8f7 0x894 0x9bf 0x9a6 0x982 0x975 0x976 0x978 0x98a 0x976 0x982 0x998 0x996 0x98b 0x995 0x9a4 0x9bd 0x9e3 0x8dd 0x865 0x9a0 0x985 0x960 0x950 0x96d 0x97b 0x97f 0x967 0x975 0x990 0x98b 0x980 0x964 0x975 0x99c 0x9b5 0x8ae 0x847 0x987 0x96f 0x94a 0x938 0x957 0x965 0x969 0x954 0x970 0x991 0x988 0x977 0x951 0x965 0x98b 0x99f 0x87f 0x82a 0x976 0x95e 0x936 0x926 0x92f 0x942 0x949 0x92c 0x934 0x955 0x947 0x936 0x94e 0x95f 0x987 0x9a2 0x865 0x7d4 0x9a6 0x962 0x911 0x900 0x914 0x92a 0x930 0x911 0x925 0x949 0x93d 0x92c 0x910 0x922 0x972 0x9b7 0x827 0xd02 0xb5a 0x842 0x933 0x922 0xa87 0xa99 0xa99 0xa75 0x9a4 0x9ca 0x9c8 0x9b3 0x93d 0x950 0x864 0xba8 0xd7b 0x32c8 0x32c8 0x32c8>;
                PS_Config_Lmt_Open_Rawdata_N = <0x821 0x77c 0x683 0x582 0x4c2 0x00 0x00 0x00 0x00 0x00 0x00 0x00 0x00 0x470 0x53e 0x641 0x73c 0x7ed 0x43c 0x556 0x53f 0x516 0x501 0x5fe 0x532 0x532 0x52c 0x51c 0x525 0x527 0x5e6 0x558 0x56d 0x596 0x5b0 0x45f 0x4e8 0x544 0x53a 0x521 0x51a 0x50e 0x50f 0x512 0x50c 0x4fe 0x509 0x509 0x50b 0x517 0x51f 0x53c 0x548 0x505 0x4bf 0x53a 0x536 0x51c 0x517 0x514 0x515 0x518 0x512 0x50c 0x50d 0x511 0x512 0x515 0x51e 0x539 0x547 0x4d5 0x4bc 0x546 0x53b 0x522 0x518 0x505 0x507 0x50b 0x506 0x4ff 0x505 0x504 0x506 0x51d 0x525 0x542 0x54e 0x4d5 0x4bf 0x535 0x525 0x512 0x501 0x4ff 0x502 0x506 0x501 0x4fb 0x500 0x4f9 0x500 0x504 0x518 0x534 0x540 0x4db 0x4af 0x52e 0x521 0x50a 0x4fa 0x4fb 0x4fe 0x501 0x4fd 0x4f3 0x4f8 0x4f8 0x4f8 0x4fe 0x511 0x52d 0x539 0x4ce 0x4a8 0x52a 0x515 0x500 0x4f5 0x4fd 0x500 0x502 0x4ff 0x4f7 0x4fb 0x4fc 0x4f7 0x4f6 0x509 0x51c 0x530 0x4c7 0x4a5 0x52d 0x518 0x508 0x4f7 0x4f7 0x4fb 0x4fc 0x4fa 0x4f5 0x4f8 0x4fb 0x4fb 0x4f8 0x50a 0x51b 0x531 0x4bc 0x4a5 0x526 0x511 0x4f7 0x4eb 0x4ff 0x503 0x504 0x502 0x4f7 0x4fb 0x4fe 0x4fd 0x4f0 0x500 0x519 0x52f 0x4be 0x49d 0x52d 0x518 0x4ff 0x4f9 0x4ec 0x4f5 0x4f8 0x4f6 0x4e6 0x4eb 0x4ec 0x4eb 0x4f7 0x4f9 0x519 0x530 0x4bb 0x4a2 0x51d 0x509 0x4f0 0x4ea 0x4e2 0x4e5 0x4e9 0x4e9 0x4dc 0x4e1 0x4e2 0x4e1 0x4e4 0x4ec 0x507 0x51e 0x4bb 0x493 0x50b 0x4f9 0x4e1 0x4da 0x4da 0x4d7 0x4e0 0x4e1 0x4d1 0x4d7 0x4d7 0x4d7 0x4dc 0x4e4 0x4f9 0x514 0x4a8 0x481 0x4fb 0x4f1 0x4d8 0x4d1 0x4d3 0x4d7 0x4da 0x4db 0x4d2 0x4da 0x4d9 0x4d9 0x4d0 0x4d9 0x4f3 0x501 0x49b 0x478 0x4f5 0x4e2 0x4d3 0x4cc 0x4ce 0x4d2 0x4ce 0x4d6 0x4cd 0x4d5 0x4d6 0x4d4 0x4d1 0x4d9 0x4eb 0x4f9 0x48e 0x470 0x4ee 0x4db 0x4cb 0x4c4 0x4c7 0x4ca 0x4cc 0x4cd 0x4bc 0x4c3 0x4c5 0x4c3 0x4cb 0x4d2 0x4e3 0x4f8 0x48c 0x468 0x4e5 0x4d2 0x4c3 0x4bb 0x4b9 0x4be 0x4c0 0x4bc 0x4bd 0x4c7 0x4c7 0x4c5 0x4b9 0x4c0 0x4d1 0x4e5 0x47f 0x45e 0x4d7 0x4c3 0x4b4 0x4ae 0x4ad 0x4b1 0x4b2 0x4b4 0x4ad 0x4b4 0x4b5 0x4b3 0x4bb 0x4c2 0x4d3 0x4e8 0x471 0x44e 0x4c8 0x4b7 0x4a8 0x4a1 0x4a9 0x4ad 0x4af 0x4b1 0x49f 0x4a7 0x4a6 0x4a6 0x4aa 0x4b1 0x4c1 0x4d6 0x471 0x436 0x4bd 0x4b3 0x4a3 0x49c 0x49f 0x4a3 0x4a6 0x4a6 0x495 0x4a2 0x4a1 0x4a1 0x49b 0x4a2 0x4b3 0x4c1 0x45f 0x43b 0x4b1 0x4a8 0x498 0x492 0x48f 0x492 0x494 0x497 0x499 0x49b 0x49a 0x49a 0x495 0x49c 0x4ad 0x4b8 0x44e 0x42f 0x498 0x496 0x488 0x482 0x486 0x489 0x48c 0x48e 0x48c 0x487 0x490 0x48d 0x48e 0x495 0x4a6 0x4b2 0x448 0x41d 0x498 0x48d 0x47e 0x479 0x47e 0x481 0x483 0x486 0x47f 0x484 0x482 0x480 0x482 0x489 0x49b 0x4a6 0x43f 0x413 0x48f 0x47c 0x474 0x470 0x46c 0x471 0x472 0x475 0x46f 0x474 0x46b 0x46f 0x475 0x47c 0x48e 0x499 0x430 0x408 0x47d 0x472 0x462 0x45d 0x45c 0x462 0x463 0x465 0x463 0x46a 0x468 0x464 0x463 0x46b 0x47d 0x487 0x420 0x3f5 0x470 0x464 0x44d 0x44e 0x457 0x45d 0x460 0x45d 0x45c 0x465 0x463 0x458 0x457 0x45e 0x46f 0x47a 0x40e 0x3e5 0x46a 0x460 0x44f 0x443 0x456 0x45b 0x45f 0x45c 0x45a 0x466 0x462 0x460 0x44a 0x456 0x469 0x473 0x400 0x3dc 0x468 0x45d 0x44d 0x448 0x441 0x445 0x448 0x440 0x43f 0x44c 0x447 0x445 0x451 0x456 0x469 0x474 0x3f8 0x3d8 0x452 0x448 0x437 0x433 0x429 0x434 0x437 0x42e 0x436 0x43f 0x43f 0x43c 0x436 0x436 0x44f 0x458 0x3f4 0x3c1 0x440 0x435 0x425 0x421 0x41c 0x422 0x425 0x41c 0x426 0x42e 0x42e 0x42a 0x42e 0x434 0x445 0x44f 0x3d8 0x3ad 0x42d 0x423 0x413 0x40d 0x40e 0x40f 0x417 0x40e 0x413 0x41d 0x41c 0x417 0x41b 0x422 0x42c 0x43d 0x3cc 0x399 0x420 0x414 0x405 0x3fe 0x40a 0x410 0x412 0x408 0x40d 0x419 0x417 0x412 0x406 0x40e 0x41e 0x429 0x3b8 0x38c 0x415 0x40b 0x3fb 0x3f4 0x401 0x407 0x408 0x400 0x40b 0x41a 0x416 0x40e 0x3fe 0x407 0x417 0x420 0x3a4 0x380 0x40e 0x404 0x3f3 0x3ec 0x3ef 0x3f8 0x3fb 0x3ee 0x3f2 0x400 0x3fa 0x3f3 0x3fd 0x404 0x415 0x421 0x399 0x35b 0x422 0x405 0x3e3 0x3db 0x3e4 0x3ed 0x3f0 0x3e3 0x3eb 0x3fb 0x3f6 0x3ee 0x3e2 0x3ea 0x40c 0x42a 0x37f 0x593 0x4dd 0x38a 0x3f1 0x3ea 0x483 0x48b 0x48b 0x47b 0x422 0x432 0x431 0x428 0x3f6 0x3fe 0x399 0x4ff 0x5c7 0x64 0x64 0x64>;
                PS_Config_Lmt_FW_Rawdata_P = <0x6a4 0x6a4 0x6a4 0x6a4 0x6a4 0xffff 0xffff 0xffff 0xffff 0xffff 0xffff 0xffff 0xffff 0x6a4 0x6a4 0x6a4 0x6a4 0x6a4 0x6a4 0x6a4 0x6a4 0x6a4 0x6a4 0x6a4 0x6a4 0x6a4 0x6a4 0x6a4 0x6a4 0x6a4 0x6a4 0x6a4 0x6a4 0x6a4 0x6a4 0x6a4 0x6a4 0x6a4 0x6a4 0x6a4 0x6a4 0x6a4 0x6a4 0x6a4 0x6a4 0x6a4 0x6a4 0x6a4 0x6a4 0x6a4 0x6a4 0x6a4 0x6a4 0x6a4 0x6a4 0x6a4 0x6a4 0x6a4 0x6a4 0x6a4 0x6a4 0x6a4 0x6a4 0x6a4 0x6a4 0x6a4 0x6a4 0x6a4 0x6a4 0x6a4 0x6a4 0x6a4 0x6a4 0x6a4 0x6a4 0x6a4 0x6a4 0x6a4 0x6a4 0x6a4 0x6a4 0x6a4 0x6a4 0x6a4 0x6a4 0x6a4 0x6a4 0x6a4 0x6a4 0x6a4 0x6a4 0x6a4 0x6a4 0x6a4 0x6a4 0x6a4 0x6a4 0x6a4 0x6a4 0x6a4 0x6a4 0x6a4 0x6a4 0x6a4 0x6a4 0x6a4 0x6a4 0x6a4 0x6a4 0x6a4 0x6a4 0x6a4 0x6a4 0x6a4 0x6a4 0x6a4 0x6a4 0x6a4 0x6a4 0x6a4 0x6a4 0x6a4 0x6a4 0x6a4 0x6a4 0x6a4 0x6a4 0x6a4 0x6a4 0x6a4 0x6a4 0x6a4 0x6a4 0x6a4 0x6a4 0x6a4 0x6a4 0x6a4 0x6a4 0x6a4 0x6a4 0x6a4 0x6a4 0x6a4 0x6a4 0x6a4 0x6a4 0x6a4 0x6a4 0x6a4 0x6a4 0x6a4 0x6a4 0x6a4 0x6a4 0x6a4 0x6a4 0x6a4 0x6a4 0x6a4 0x6a4 0x6a4 0x6a4 0x6a4 0x6a4 0x6a4 0x6a4 0x6a4 0x6a4 0x6a4 0x6a4 0x6a4 0x6a4 0x6a4 0x6a4 0x6a4 0x6a4 0x6a4 0x6a4 0x6a4 0x6a4 0x6a4 0x6a4 0x6a4 0x6a4 0x6a4 0x6a4 0x6a4 0x6a4 0x6a4 0x6a4 0x6a4 0x6a4 0x6a4 0x6a4 0x6a4 0x6a4 0x6a4 0x6a4 0x6a4 0x6a4 0x6a4 0x6a4 0x6a4 0x6a4 0x6a4 0x6a4 0x6a4 0x6a4 0x6a4 0x6a4 0x6a4 0x6a4 0x6a4 0x6a4 0x6a4 0x6a4 0x6a4 0x6a4 0x6a4 0x6a4 0x6a4 0x6a4 0x6a4 0x6a4 0x6a4 0x6a4 0x6a4 0x6a4 0x6a4 0x6a4 0x6a4 0x6a4 0x6a4 0x6a4 0x6a4 0x6a4 0x6a4 0x6a4 0x6a4 0x6a4 0x6a4 0x6a4 0x6a4 0x6a4 0x6a4 0x6a4 0x6a4 0x6a4 0x6a4 0x6a4 0x6a4 0x6a4 0x6a4 0x6a4 0x6a4 0x6a4 0x6a4 0x6a4 0x6a4 0x6a4 0x6a4 0x6a4 0x6a4 0x6a4 0x6a4 0x6a4 0x6a4 0x6a4 0x6a4 0x6a4 0x6a4 0x6a4 0x6a4 0x6a4 0x6a4 0x6a4 0x6a4 0x6a4 0x6a4 0x6a4 0x6a4 0x6a4 0x6a4 0x6a4 0x6a4 0x6a4 0x6a4 0x6a4 0x6a4 0x6a4 0x6a4 0x6a4 0x6a4 0x6a4 0x6a4 0x6a4 0x6a4 0x6a4 0x6a4 0x6a4 0x6a4 0x6a4 0x6a4 0x6a4 0x6a4 0x6a4 0x6a4 0x6a4 0x6a4 0x6a4 0x6a4 0x6a4 0x6a4 0x6a4 0x6a4 0x6a4 0x6a4 0x6a4 0x6a4 0x6a4 0x6a4 0x6a4 0x6a4 0x6a4 0x6a4 0x6a4 0x6a4 0x6a4 0x6a4 0x6a4 0x6a4 0x6a4 0x6a4 0x6a4 0x6a4 0x6a4 0x6a4 0x6a4 0x6a4 0x6a4 0x6a4 0x6a4 0x6a4 0x6a4 0x6a4 0x6a4 0x6a4 0x6a4 0x6a4 0x6a4 0x6a4 0x6a4 0x6a4 0x6a4 0x6a4 0x6a4 0x6a4 0x6a4 0x6a4 0x6a4 0x6a4 0x6a4 0x6a4 0x6a4 0x6a4 0x6a4 0x6a4 0x6a4 0x6a4 0x6a4 0x6a4 0x6a4 0x6a4 0x6a4 0x6a4 0x6a4 0x6a4 0x6a4 0x6a4 0x6a4 0x6a4 0x6a4 0x6a4 0x6a4 0x6a4 0x6a4 0x6a4 0x6a4 0x6a4 0x6a4 0x6a4 0x6a4 0x6a4 0x6a4 0x6a4 0x6a4 0x6a4 0x6a4 0x6a4 0x6a4 0x6a4 0x6a4 0x6a4 0x6a4 0x6a4 0x6a4 0x6a4 0x6a4 0x6a4 0x6a4 0x6a4 0x6a4 0x6a4 0x6a4 0x6a4 0x6a4 0x6a4 0x6a4 0x6a4 0x6a4 0x6a4 0x6a4 0x6a4 0x6a4 0x6a4 0x6a4 0x6a4 0x6a4 0x6a4 0x6a4 0x6a4 0x6a4 0x6a4 0x6a4 0x6a4 0x6a4 0x6a4 0x6a4 0x6a4 0x6a4 0x6a4 0x6a4 0x6a4 0x6a4 0x6a4 0x6a4 0x6a4 0x6a4 0x6a4 0x6a4 0x6a4 0x6a4 0x6a4 0x6a4 0x6a4 0x6a4 0x6a4 0x6a4 0x6a4 0x6a4 0x6a4 0x6a4 0x6a4 0x6a4 0x6a4 0x6a4 0x6a4 0x6a4 0x6a4 0x6a4 0x6a4 0x6a4 0x6a4 0x6a4 0x6a4 0x6a4 0x6a4 0x6a4 0x6a4 0x6a4 0x6a4 0x6a4 0x6a4 0x6a4 0x6a4 0x6a4 0x6a4 0x6a4 0x6a4 0x6a4 0x6a4 0x6a4 0x6a4 0x6a4 0x6a4 0x6a4 0x6a4 0x6a4 0x6a4 0x6a4 0x6a4 0x6a4 0x6a4 0x6a4 0x6a4 0x6a4 0x6a4 0x6a4 0x6a4 0x6a4 0x6a4 0x6a4 0x6a4 0x6a4 0x6a4 0x6a4 0x6a4 0x6a4 0x6a4 0x6a4 0x6a4 0x6a4 0x6a4 0x6a4 0x6a4 0x6a4 0x6a4 0x6a4 0x6a4 0x6a4 0x6a4 0x6a4 0x6a4 0x6a4 0x6a4 0x6a4 0x6a4 0x6a4 0x6a4 0x6a4 0x6a4 0x6a4 0x6a4 0x6a4 0x6a4 0x6a4 0x6a4 0x6a4 0x6a4 0x6a4 0x6a4 0x6a4 0x6a4 0x6a4 0x6a4 0x6a4 0x6a4 0x6a4 0x6a4 0x6a4 0x6a4 0x6a4 0x6a4 0x6a4 0x6a4 0x6a4 0x6a4 0x6a4 0x6a4 0x6a4 0x6a4 0x6a4 0x6a4 0x6a4 0x6a4 0x6a4 0x6a4 0x6a4 0x6a4 0x6a4 0x6a4 0x6a4 0x6a4 0x6a4 0x6a4 0x6a4 0x6a4 0x6a4 0x6a4 0x6a4 0x6a4 0x6a4 0x6a4 0x6a4 0x6a4 0x6a4 0x6a4 0x6a4 0x6a4 0x6a4 0x6a4 0x6a4 0x6a4 0x6a4 0x6a4 0x6a4 0x6a4 0x6a4 0x6a4 0x6a4 0x6a4 0x6a4 0x6a4 0x6a4 0x6a4 0x6a4 0x6a4 0x6a4 0x6a4 0x6a4 0x6a4 0x6a4 0x6a4 0x6a4 0x6a4 0x6a4 0x6a4 0x6a4 0x6a4 0x6a4 0x6a4 0x6a4 0x6a4 0x6a4 0x6a4 0x6a4 0x6a4 0x6a4 0x6a4 0x6a4 0x6a4 0x6a4 0x6a4 0x6a4 0x6a4 0x6a4 0x6a4 0xfa0 0xfa0 0xfa0>;
                PS_Config_Lmt_FW_Rawdata_N = <0x2bc 0x2bc 0x2bc 0x2bc 0x2bc 0x00 0x00 0x00 0x00 0x00 0x00 0x00 0x00 0x2bc 0x2bc 0x2bc 0x2bc 0x2bc 0x2bc 0x2bc 0x2bc 0x2bc 0x2bc 0x2bc 0x2bc 0x2bc 0x2bc 0x2bc 0x2bc 0x2bc 0x2bc 0x2bc 0x2bc 0x2bc 0x2bc 0x2bc 0x2bc 0x2bc 0x2bc 0x2bc 0x2bc 0x2bc 0x2bc 0x2bc 0x2bc 0x2bc 0x2bc 0x2bc 0x2bc 0x2bc 0x2bc 0x2bc 0x2bc 0x2bc 0x2bc 0x2bc 0x2bc 0x2bc 0x2bc 0x2bc 0x2bc 0x2bc 0x2bc 0x2bc 0x2bc 0x2bc 0x2bc 0x2bc 0x2bc 0x2bc 0x2bc 0x2bc 0x2bc 0x2bc 0x2bc 0x2bc 0x2bc 0x2bc 0x2bc 0x2bc 0x2bc 0x2bc 0x2bc 0x2bc 0x2bc 0x2bc 0x2bc 0x2bc 0x2bc 0x2bc 0x2bc 0x2bc 0x2bc 0x2bc 0x2bc 0x2bc 0x2bc 0x2bc 0x2bc 0x2bc 0x2bc 0x2bc 0x2bc 0x2bc 0x2bc 0x2bc 0x2bc 0x2bc 0x2bc 0x2bc 0x2bc 0x2bc 0x2bc 0x2bc 0x2bc 0x2bc 0x2bc 0x2bc 0x2bc 0x2bc 0x2bc 0x2bc 0x2bc 0x2bc 0x2bc 0x2bc 0x2bc 0x2bc 0x2bc 0x2bc 0x2bc 0x2bc 0x2bc 0x2bc 0x2bc 0x2bc 0x2bc 0x2bc 0x2bc 0x2bc 0x2bc 0x2bc 0x2bc 0x2bc 0x2bc 0x2bc 0x2bc 0x2bc 0x2bc 0x2bc 0x2bc 0x2bc 0x2bc 0x2bc 0x2bc 0x2bc 0x2bc 0x2bc 0x2bc 0x2bc 0x2bc 0x2bc 0x2bc 0x2bc 0x2bc 0x2bc 0x2bc 0x2bc 0x2bc 0x2bc 0x2bc 0x2bc 0x2bc 0x2bc 0x2bc 0x2bc 0x2bc 0x2bc 0x2bc 0x2bc 0x2bc 0x2bc 0x2bc 0x2bc 0x2bc 0x2bc 0x2bc 0x2bc 0x2bc 0x2bc 0x2bc 0x2bc 0x2bc 0x2bc 0x2bc 0x2bc 0x2bc 0x2bc 0x2bc 0x2bc 0x2bc 0x2bc 0x2bc 0x2bc 0x2bc 0x2bc 0x2bc 0x2bc 0x2bc 0x2bc 0x2bc 0x2bc 0x2bc 0x2bc 0x2bc 0x2bc 0x2bc 0x2bc 0x2bc 0x2bc 0x2bc 0x2bc 0x2bc 0x2bc 0x2bc 0x2bc 0x2bc 0x2bc 0x2bc 0x2bc 0x2bc 0x2bc 0x2bc 0x2bc 0x2bc 0x2bc 0x2bc 0x2bc 0x2bc 0x2bc 0x2bc 0x2bc 0x2bc 0x2bc 0x2bc 0x2bc 0x2bc 0x2bc 0x2bc 0x2bc 0x2bc 0x2bc 0x2bc 0x2bc 0x2bc 0x2bc 0x2bc 0x2bc 0x2bc 0x2bc 0x2bc 0x2bc 0x2bc 0x2bc 0x2bc 0x2bc 0x2bc 0x2bc 0x2bc 0x2bc 0x2bc 0x2bc 0x2bc 0x2bc 0x2bc 0x2bc 0x2bc 0x2bc 0x2bc 0x2bc 0x2bc 0x2bc 0x2bc 0x2bc 0x2bc 0x2bc 0x2bc 0x2bc 0x2bc 0x2bc 0x2bc 0x2bc 0x2bc 0x2bc 0x2bc 0x2bc 0x2bc 0x2bc 0x2bc 0x2bc 0x2bc 0x2bc 0x2bc 0x2bc 0x2bc 0x2bc 0x2bc 0x2bc 0x2bc 0x2bc 0x2bc 0x2bc 0x2bc 0x2bc 0x2bc 0x2bc 0x2bc 0x2bc 0x2bc 0x2bc 0x2bc 0x2bc 0x2bc 0x2bc 0x2bc 0x2bc 0x2bc 0x2bc 0x2bc 0x2bc 0x2bc 0x2bc 0x2bc 0x2bc 0x2bc 0x2bc 0x2bc 0x2bc 0x2bc 0x2bc 0x2bc 0x2bc 0x2bc 0x2bc 0x2bc 0x2bc 0x2bc 0x2bc 0x2bc 0x2bc 0x2bc 0x2bc 0x2bc 0x2bc 0x2bc 0x2bc 0x2bc 0x2bc 0x2bc 0x2bc 0x2bc 0x2bc 0x2bc 0x2bc 0x2bc 0x2bc 0x2bc 0x2bc 0x2bc 0x2bc 0x2bc 0x2bc 0x2bc 0x2bc 0x2bc 0x2bc 0x2bc 0x2bc 0x2bc 0x2bc 0x2bc 0x2bc 0x2bc 0x2bc 0x2bc 0x2bc 0x2bc 0x2bc 0x2bc 0x2bc 0x2bc 0x2bc 0x2bc 0x2bc 0x2bc 0x2bc 0x2bc 0x2bc 0x2bc 0x2bc 0x2bc 0x2bc 0x2bc 0x2bc 0x2bc 0x2bc 0x2bc 0x2bc 0x2bc 0x2bc 0x2bc 0x2bc 0x2bc 0x2bc 0x2bc 0x2bc 0x2bc 0x2bc 0x2bc 0x2bc 0x2bc 0x2bc 0x2bc 0x2bc 0x2bc 0x2bc 0x2bc 0x2bc 0x2bc 0x2bc 0x2bc 0x2bc 0x2bc 0x2bc 0x2bc 0x2bc 0x2bc 0x2bc 0x2bc 0x2bc 0x2bc 0x2bc 0x2bc 0x2bc 0x2bc 0x2bc 0x2bc 0x2bc 0x2bc 0x2bc 0x2bc 0x2bc 0x2bc 0x2bc 0x2bc 0x2bc 0x2bc 0x2bc 0x2bc 0x2bc 0x2bc 0x2bc 0x2bc 0x2bc 0x2bc 0x2bc 0x2bc 0x2bc 0x2bc 0x2bc 0x2bc 0x2bc 0x2bc 0x2bc 0x2bc 0x2bc 0x2bc 0x2bc 0x2bc 0x2bc 0x2bc 0x2bc 0x2bc 0x2bc 0x2bc 0x2bc 0x2bc 0x2bc 0x2bc 0x2bc 0x2bc 0x2bc 0x2bc 0x2bc 0x2bc 0x2bc 0x2bc 0x2bc 0x2bc 0x2bc 0x2bc 0x2bc 0x2bc 0x2bc 0x2bc 0x2bc 0x2bc 0x2bc 0x2bc 0x2bc 0x2bc 0x2bc 0x2bc 0x2bc 0x2bc 0x2bc 0x2bc 0x2bc 0x2bc 0x2bc 0x2bc 0x2bc 0x2bc 0x2bc 0x2bc 0x2bc 0x2bc 0x2bc 0x2bc 0x2bc 0x2bc 0x2bc 0x2bc 0x2bc 0x2bc 0x2bc 0x2bc 0x2bc 0x2bc 0x2bc 0x2bc 0x2bc 0x2bc 0x2bc 0x2bc 0x2bc 0x2bc 0x2bc 0x2bc 0x2bc 0x2bc 0x2bc 0x2bc 0x2bc 0x2bc 0x2bc 0x2bc 0x2bc 0x2bc 0x2bc 0x2bc 0x2bc 0x2bc 0x2bc 0x2bc 0x2bc 0x2bc 0x2bc 0x2bc 0x2bc 0x2bc 0x2bc 0x2bc 0x2bc 0x2bc 0x2bc 0x2bc 0x2bc 0x2bc 0x2bc 0x2bc 0x2bc 0x2bc 0x2bc 0x2bc 0x2bc 0x2bc 0x2bc 0x2bc 0x2bc 0x2bc 0x2bc 0x2bc 0x2bc 0x2bc 0x2bc 0x2bc 0x2bc 0x2bc 0x2bc 0x2bc 0x2bc 0x2bc 0x2bc 0x2bc 0x2bc 0x2bc 0x2bc 0x2bc 0x2bc 0x2bc 0x2bc 0x2bc 0x2bc 0x2bc 0x2bc 0x2bc 0x2bc 0x2bc 0x2bc 0x2bc 0x2bc 0x2bc 0x2bc 0x2bc 0x2bc 0x2bc 0x2bc 0x2bc 0x2bc 0x2bc 0x2bc 0x2bc 0x2bc 0x2bc 0x2bc 0x2bc 0x2bc 0x2bc 0x2bc 0x2bc 0x2bc 0x2bc 0x2bc 0x2bc 0x2bc 0x2bc 0x2bc 0x64 0x64 0x64>;
                PS_Config_Lmt_FW_CC_P = <0x78 0x77 0x77 0x78 0x79 0x1ff 0x1ff 0x1ff 0x1ff 0x1ff 0x1ff 0x1ff 0x1ff 0x78 0x78 0x77 0x77 0x78 0x79 0x77 0x75 0x74 0x74 0x7a 0x78 0x77 0x7a 0x77 0x75 0x76 0x77 0x71 0x71 0x71 0x73 0x79 0x7a 0x7b 0x7a 0x79 0x78 0x7a 0x79 0x78 0x7b 0x75 0x74 0x75 0x76 0x76 0x76 0x77 0x79 0x77 0x7d 0x7d 0x7b 0x7a 0x7a 0x7a 0x79 0x78 0x7b 0x75 0x74 0x75 0x76 0x76 0x76 0x77 0x78 0x7c 0x7f 0x7c 0x7b 0x7a 0x7a 0x78 0x78 0x77 0x79 0x76 0x75 0x76 0x76 0x76 0x76 0x77 0x78 0x7b 0x7e 0x7a 0x79 0x79 0x79 0x75 0x75 0x74 0x76 0x74 0x73 0x74 0x74 0x77 0x77 0x78 0x78 0x7b 0x7c 0x77 0x76 0x76 0x76 0x77 0x77 0x75 0x78 0x72 0x71 0x73 0x73 0x75 0x75 0x75 0x76 0x7c 0x79 0x78 0x77 0x77 0x78 0x79 0x79 0x77 0x7a 0x76 0x74 0x76 0x76 0x73 0x73 0x74 0x74 0x79 0x7b 0x7a 0x7a 0x79 0x7a 0x78 0x78 0x76 0x7a 0x76 0x75 0x77 0x77 0x77 0x76 0x76 0x77 0x77 0x7d 0x79 0x78 0x78 0x79 0x79 0x7a 0x77 0x7c 0x77 0x75 0x78 0x77 0x78 0x78 0x78 0x79 0x7b 0x7c 0x7b 0x79 0x7a 0x7a 0x79 0x79 0x78 0x7c 0x75 0x74 0x76 0x76 0x78 0x78 0x77 0x78 0x7c 0x7d 0x7a 0x79 0x79 0x7a 0x75 0x75 0x75 0x7a 0x73 0x72 0x73 0x73 0x77 0x76 0x76 0x77 0x7c 0x7d 0x76 0x75 0x76 0x76 0x75 0x75 0x75 0x7a 0x73 0x73 0x74 0x74 0x73 0x73 0x73 0x74 0x7a 0x79 0x75 0x75 0x74 0x74 0x79 0x78 0x79 0x7e 0x77 0x78 0x77 0x79 0x73 0x74 0x74 0x74 0x77 0x78 0x78 0x77 0x77 0x77 0x7a 0x79 0x79 0x7f 0x76 0x78 0x76 0x78 0x77 0x77 0x77 0x78 0x77 0x7b 0x79 0x79 0x78 0x78 0x79 0x79 0x7b 0x80 0x76 0x78 0x76 0x76 0x76 0x76 0x77 0x77 0x7b 0x7c 0x79 0x79 0x79 0x78 0x77 0x77 0x79 0x7f 0x77 0x79 0x78 0x77 0x76 0x76 0x76 0x76 0x79 0x7c 0x77 0x77 0x76 0x76 0x74 0x74 0x75 0x7b 0x75 0x76 0x76 0x75 0x77 0x78 0x78 0x78 0x79 0x7a 0x74 0x74 0x74 0x73 0x76 0x76 0x77 0x7d 0x73 0x74 0x74 0x74 0x75 0x76 0x76 0x76 0x7a 0x76 0x76 0x76 0x75 0x75 0x78 0x78 0x79 0x7f 0x77 0x77 0x77 0x76 0x74 0x74 0x74 0x74 0x78 0x79 0x78 0x78 0x78 0x77 0x77 0x77 0x77 0x7f 0x78 0x77 0x78 0x78 0x76 0x77 0x77 0x77 0x76 0x7a 0x77 0x76 0x77 0x76 0x77 0x77 0x77 0x7f 0x78 0x78 0x79 0x79 0x78 0x79 0x79 0x79 0x79 0x79 0x77 0x77 0x77 0x76 0x78 0x78 0x78 0x80 0x77 0x77 0x78 0x78 0x78 0x79 0x79 0x79 0x7b 0x79 0x78 0x78 0x78 0x78 0x75 0x75 0x75 0x7c 0x74 0x75 0x75 0x75 0x77 0x78 0x78 0x78 0x7c 0x7b 0x75 0x75 0x75 0x74 0x74 0x74 0x74 0x7a 0x75 0x76 0x76 0x76 0x75 0x75 0x75 0x75 0x7a 0x77 0x74 0x74 0x73 0x73 0x77 0x77 0x78 0x7d 0x79 0x7b 0x7a 0x7a 0x75 0x75 0x76 0x76 0x77 0x76 0x77 0x78 0x76 0x76 0x7a 0x79 0x7a 0x7b 0x78 0x7a 0x7a 0x7b 0x79 0x79 0x7a 0x7a 0x77 0x79 0x79 0x79 0x78 0x78 0x7a 0x78 0x7a 0x77 0x78 0x7a 0x79 0x7a 0x79 0x79 0x7b 0x7a 0x7c 0x7b 0x78 0x79 0x77 0x77 0x78 0x77 0x79 0x76 0x79 0x7b 0x7a 0x7b 0x78 0x78 0x7a 0x79 0x7c 0x7a 0x77 0x77 0x76 0x76 0x74 0x74 0x76 0x72 0x76 0x79 0x77 0x78 0x79 0x7a 0x7b 0x7a 0x7b 0x79 0x73 0x74 0x73 0x73 0x76 0x76 0x78 0x74 0x74 0x77 0x75 0x76 0x77 0x77 0x78 0x77 0x7d 0x75 0x76 0x75 0x75 0x75 0x79 0x79 0x7c 0x76 0x78 0x7c 0x79 0x7a 0x74 0x75 0x75 0x75 0x7a 0x78 0x76 0x76 0x77 0x76 0x78 0x78 0x7b 0x76 0x7a 0x7e 0x7b 0x7b 0x78 0x79 0x79 0x79 0x77 0x79 0x76 0x76 0x76 0x76 0x78 0x79 0x7c 0x76 0x7a 0x7f 0x7c 0x7b 0x7b 0x7b 0x7b 0x7b 0x7b 0x79 0x77 0x77 0x77 0x77 0x78 0x7b 0x7e 0x78 0x79 0x7d 0x7b 0x79 0x7b 0x7b 0x7c 0x7b 0x7d 0x7b 0x7c 0x7c 0x7e 0x7e 0x7b 0x7e 0x80 0x7b 0x7b 0x7d 0x7c 0x7a 0x7f 0x80 0x7e 0x7e 0x7e 0x8a 0x8a 0x8a>;
                PS_Config_Lmt_FW_CC_N = <0x46 0x46 0x46 0x46 0x46 0x00 0x00 0x00 0x00 0x00 0x00 0x00 0x00 0x46 0x46 0x46 0x46 0x46 0x46 0x46 0x46 0x46 0x46 0x46 0x46 0x46 0x46 0x46 0x46 0x46 0x46 0x46 0x46 0x46 0x46 0x46 0x46 0x46 0x46 0x46 0x46 0x46 0x46 0x46 0x46 0x46 0x46 0x46 0x46 0x46 0x46 0x46 0x46 0x46 0x46 0x46 0x46 0x46 0x46 0x46 0x46 0x46 0x46 0x46 0x46 0x46 0x46 0x46 0x46 0x46 0x46 0x46 0x46 0x46 0x46 0x46 0x46 0x46 0x46 0x46 0x46 0x46 0x46 0x46 0x46 0x46 0x46 0x46 0x46 0x46 0x46 0x46 0x46 0x46 0x46 0x46 0x46 0x46 0x46 0x46 0x46 0x46 0x46 0x46 0x46 0x46 0x46 0x46 0x46 0x46 0x46 0x46 0x46 0x46 0x46 0x46 0x46 0x46 0x46 0x46 0x46 0x46 0x46 0x46 0x46 0x46 0x46 0x46 0x46 0x46 0x46 0x46 0x46 0x46 0x46 0x46 0x46 0x46 0x46 0x46 0x46 0x46 0x46 0x46 0x46 0x46 0x46 0x46 0x46 0x46 0x46 0x46 0x46 0x46 0x46 0x46 0x46 0x46 0x46 0x46 0x46 0x46 0x46 0x46 0x46 0x46 0x46 0x46 0x46 0x46 0x46 0x46 0x46 0x46 0x46 0x46 0x46 0x46 0x46 0x46 0x46 0x46 0x46 0x46 0x46 0x46 0x46 0x46 0x46 0x46 0x46 0x46 0x46 0x46 0x46 0x46 0x46 0x46 0x46 0x46 0x46 0x46 0x46 0x46 0x46 0x46 0x46 0x46 0x46 0x46 0x46 0x46 0x46 0x46 0x46 0x46 0x46 0x46 0x46 0x46 0x46 0x46 0x46 0x46 0x46 0x46 0x46 0x46 0x46 0x46 0x46 0x46 0x46 0x46 0x46 0x46 0x46 0x46 0x46 0x46 0x46 0x46 0x46 0x46 0x46 0x46 0x46 0x46 0x46 0x46 0x46 0x46 0x46 0x46 0x46 0x46 0x46 0x46 0x46 0x46 0x46 0x46 0x46 0x46 0x46 0x46 0x46 0x46 0x46 0x46 0x46 0x46 0x46 0x46 0x46 0x46 0x46 0x46 0x46 0x46 0x46 0x46 0x46 0x46 0x46 0x46 0x46 0x46 0x46 0x46 0x46 0x46 0x46 0x46 0x46 0x46 0x46 0x46 0x46 0x46 0x46 0x46 0x46 0x46 0x46 0x46 0x46 0x46 0x46 0x46 0x46 0x46 0x46 0x46 0x46 0x46 0x46 0x46 0x46 0x46 0x46 0x46 0x46 0x46 0x46 0x46 0x46 0x46 0x46 0x46 0x46 0x46 0x46 0x46 0x46 0x46 0x46 0x46 0x46 0x46 0x46 0x46 0x46 0x46 0x46 0x46 0x46 0x46 0x46 0x46 0x46 0x46 0x46 0x46 0x46 0x46 0x46 0x46 0x46 0x46 0x46 0x46 0x46 0x46 0x46 0x46 0x46 0x46 0x46 0x46 0x46 0x46 0x46 0x46 0x46 0x46 0x46 0x46 0x46 0x46 0x46 0x46 0x46 0x46 0x46 0x46 0x46 0x46 0x46 0x46 0x46 0x46 0x46 0x46 0x46 0x46 0x46 0x46 0x46 0x46 0x46 0x46 0x46 0x46 0x46 0x46 0x46 0x46 0x46 0x46 0x46 0x46 0x46 0x46 0x46 0x46 0x46 0x46 0x46 0x46 0x46 0x46 0x46 0x46 0x46 0x46 0x46 0x46 0x46 0x46 0x46 0x46 0x46 0x46 0x46 0x46 0x46 0x46 0x46 0x46 0x46 0x46 0x46 0x46 0x46 0x46 0x46 0x46 0x46 0x46 0x46 0x46 0x46 0x46 0x46 0x46 0x46 0x46 0x46 0x46 0x46 0x46 0x46 0x46 0x46 0x46 0x46 0x46 0x46 0x46 0x46 0x46 0x46 0x46 0x46 0x46 0x46 0x46 0x46 0x46 0x46 0x46 0x46 0x46 0x46 0x46 0x46 0x46 0x46 0x46 0x46 0x46 0x46 0x46 0x46 0x46 0x46 0x46 0x46 0x46 0x46 0x46 0x46 0x46 0x46 0x46 0x46 0x46 0x46 0x46 0x46 0x46 0x46 0x46 0x46 0x46 0x46 0x46 0x46 0x46 0x46 0x46 0x46 0x46 0x46 0x46 0x46 0x46 0x46 0x46 0x46 0x46 0x46 0x46 0x46 0x46 0x46 0x46 0x46 0x46 0x46 0x46 0x46 0x46 0x46 0x46 0x46 0x46 0x46 0x46 0x46 0x46 0x46 0x46 0x46 0x46 0x46 0x46 0x46 0x46 0x46 0x46 0x46 0x46 0x46 0x46 0x46 0x46 0x46 0x46 0x46 0x46 0x46 0x46 0x46 0x46 0x46 0x46 0x46 0x46 0x46 0x46 0x46 0x46 0x46 0x46 0x46 0x46 0x46 0x46 0x46 0x46 0x46 0x46 0x46 0x46 0x46 0x46 0x46 0x46 0x46 0x46 0x46 0x46 0x46 0x46 0x46 0x46 0x46 0x46 0x46 0x46 0x46 0x46 0x46 0x46 0x46 0x46 0x46 0x46 0x46 0x46 0x46 0x46 0x46 0x46 0x46 0x46 0x46 0x46 0x46 0x46 0x46 0x46 0x46 0x46 0x46 0x46 0x46 0x46 0x46 0x46 0x46 0x46 0x46 0x46 0x46 0x46 0x09 0x09 0x09>;
                PS_Config_Lmt_FW_CC_I_P = <0x19 0x19 0x19 0x19 0x19 0x19 0x19 0x19 0x19 0x19 0x19 0x19 0x19 0x19 0x19 0x19 0x19 0x19 0x19 0x19 0x19 0x19 0x19 0x19 0x19 0x19 0x19 0x19 0x19 0x19 0x19 0x19 0x19 0x19 0x19 0x19 0x19 0x19 0x19 0x19 0x19 0x19 0x19 0x19 0x19 0x19 0x19 0x19 0x19 0x19 0x19 0x19 0x19 0x19 0x19 0x19 0x19 0x19 0x19 0x19 0x19 0x19 0x19 0x19 0x19 0x19 0x19 0x19 0x19 0x19 0x19 0x19 0x19 0x19 0x19 0x19 0x19 0x19 0x19 0x19 0x19 0x19 0x19 0x19 0x19 0x19 0x19 0x19 0x19 0x19 0x19 0x19 0x19 0x19 0x19 0x19 0x19 0x19 0x19 0x19 0x19 0x19 0x19 0x19 0x19 0x19 0x19 0x19 0x19 0x19 0x19 0x19 0x19 0x19 0x19 0x19 0x19 0x19 0x19 0x19 0x19 0x19 0x19 0x19 0x19 0x19 0x19 0x19 0x19 0x19 0x19 0x19 0x19 0x19 0x19 0x19 0x19 0x19 0x19 0x19 0x19 0x19 0x19 0x19 0x19 0x19 0x19 0x19 0x19 0x19 0x19 0x19 0x19 0x19 0x19 0x19 0x19 0x19 0x19 0x19 0x19 0x19 0x19 0x19 0x19 0x19 0x19 0x19 0x19 0x19 0x19 0x19 0x19 0x19 0x19 0x19 0x19 0x19 0x19 0x19 0x19 0x19 0x19 0x19 0x19 0x19 0x19 0x19 0x19 0x19 0x19 0x19 0x19 0x19 0x19 0x19 0x19 0x19 0x19 0x19 0x19 0x19 0x19 0x19 0x19 0x19 0x19 0x19 0x19 0x19 0x19 0x19 0x19 0x19 0x19 0x19 0x19 0x19 0x19 0x19 0x19 0x19 0x19 0x19 0x19 0x19 0x19 0x19 0x19 0x19 0x19 0x19 0x19 0x19 0x19 0x19 0x19 0x19 0x19 0x19 0x19 0x19 0x19 0x19 0x19 0x19 0x19 0x19 0x19 0x19 0x19 0x19 0x19 0x19 0x19 0x19 0x19 0x19 0x19 0x19 0x19 0x19 0x19 0x19 0x19 0x19 0x19 0x19 0x19 0x19 0x19 0x19 0x19 0x19 0x19 0x19 0x19 0x19 0x19 0x19 0x19 0x19 0x19 0x19 0x19 0x19 0x19 0x19 0x19 0x19 0x19 0x19 0x19 0x19 0x19 0x19 0x19 0x19 0x19 0x19 0x19 0x19 0x19 0x19 0x19 0x19 0x19 0x19 0x19 0x19 0x19 0x19 0x19 0x19 0x19 0x19 0x19 0x19 0x19 0x19 0x19 0x19 0x19 0x19 0x19 0x19 0x19 0x19 0x19 0x19 0x19 0x19 0x19 0x19 0x19 0x19 0x19 0x19 0x19 0x19 0x19 0x19 0x19 0x19 0x19 0x19 0x19 0x19 0x19 0x19 0x19 0x19 0x19 0x19 0x19 0x19 0x19 0x19 0x19 0x19 0x19 0x19 0x19 0x19 0x19 0x19 0x19 0x19 0x19 0x19 0x19 0x19 0x19 0x19 0x19 0x19 0x19 0x19 0x19 0x19 0x19 0x19 0x19 0x19 0x19 0x19 0x19 0x19 0x19 0x19 0x19 0x19 0x19 0x19 0x19 0x19 0x19 0x19 0x19 0x19 0x19 0x19 0x19 0x19 0x19 0x19 0x19 0x19 0x19 0x19 0x19 0x19 0x19 0x19 0x19 0x19 0x19 0x19 0x19 0x19 0x19 0x19 0x19 0x19 0x19 0x19 0x19 0x19 0x19 0x19 0x19 0x19 0x19 0x19 0x19 0x19 0x19 0x19 0x19 0x19 0x19 0x19 0x19 0x19 0x19 0x19 0x19 0x19 0x19 0x19 0x19 0x19 0x19 0x19 0x19 0x19 0x19 0x19 0x19 0x19 0x19 0x19 0x19 0x19 0x19 0x19 0x19 0x19 0x19 0x19 0x19 0x19 0x19 0x19 0x19 0x19 0x19 0x19 0x19 0x19 0x19 0x19 0x19 0x19 0x19 0x19 0x19 0x19 0x19 0x19 0x19 0x19 0x19 0x19 0x19 0x19 0x19 0x19 0x19 0x19 0x19 0x19 0x19 0x19 0x19 0x19 0x19 0x19 0x19 0x19 0x19 0x19 0x19 0x19 0x19 0x19 0x19 0x19 0x19 0x19 0x19 0x19 0x19 0x19 0x19 0x19 0x19 0x19 0x19 0x19 0x19 0x19 0x19 0x19 0x19 0x19 0x19 0x19 0x19 0x19 0x19 0x19 0x19 0x19 0x19 0x19 0x19 0x19 0x19 0x19 0x19 0x19 0x19 0x19 0x19 0x19 0x19 0x19 0x19 0x19 0x19 0x19 0x19 0x19 0x19 0x19 0x19 0x19 0x19 0x19 0x19 0x19 0x19 0x19 0x19 0x19 0x19 0x19 0x19>;
                PS_Config_Lmt_FW_CC_I_N = <0x00 0x00 0x00 0x00 0x00 0x00 0x00 0x00 0x00 0x00 0x00 0x00 0x00 0x00 0x00 0x00 0x00 0x00 0x00 0x00 0x00 0x00 0x00 0x00 0x00 0x00 0x00 0x00 0x00 0x00 0x00 0x00 0x00 0x00 0x00 0x00 0x00 0x00 0x00 0x00 0x00 0x00 0x00 0x00 0x00 0x00 0x00 0x00 0x00 0x00 0x00 0x00 0x00 0x00 0x00 0x00 0x00 0x00 0x00 0x00 0x00 0x00 0x00 0x00 0x00 0x00 0x00 0x00 0x00 0x00 0x00 0x00 0x00 0x00 0x00 0x00 0x00 0x00 0x00 0x00 0x00 0x00 0x00 0x00 0x00 0x00 0x00 0x00 0x00 0x00 0x00 0x00 0x00 0x00 0x00 0x00 0x00 0x00 0x00 0x00 0x00 0x00 0x00 0x00 0x00 0x00 0x00 0x00 0x00 0x00 0x00 0x00 0x00 0x00 0x00 0x00 0x00 0x00 0x00 0x00 0x00 0x00 0x00 0x00 0x00 0x00 0x00 0x00 0x00 0x00 0x00 0x00 0x00 0x00 0x00 0x00 0x00 0x00 0x00 0x00 0x00 0x00 0x00 0x00 0x00 0x00 0x00 0x00 0x00 0x00 0x00 0x00 0x00 0x00 0x00 0x00 0x00 0x00 0x00 0x00 0x00 0x00 0x00 0x00 0x00 0x00 0x00 0x00 0x00 0x00 0x00 0x00 0x00 0x00 0x00 0x00 0x00 0x00 0x00 0x00 0x00 0x00 0x00 0x00 0x00 0x00 0x00 0x00 0x00 0x00 0x00 0x00 0x00 0x00 0x00 0x00 0x00 0x00 0x00 0x00 0x00 0x00 0x00 0x00 0x00 0x00 0x00 0x00 0x00 0x00 0x00 0x00 0x00 0x00 0x00 0x00 0x00 0x00 0x00 0x00 0x00 0x00 0x00 0x00 0x00 0x00 0x00 0x00 0x00 0x00 0x00 0x00 0x00 0x00 0x00 0x00 0x00 0x00 0x00 0x00 0x00 0x00 0x00 0x00 0x00 0x00 0x00 0x00 0x00 0x00 0x00 0x00 0x00 0x00 0x00 0x00 0x00 0x00 0x00 0x00 0x00 0x00 0x00 0x00 0x00 0x00 0x00 0x00 0x00 0x00 0x00 0x00 0x00 0x00 0x00 0x00 0x00 0x00 0x00 0x00 0x00 0x00 0x00 0x00 0x00 0x00 0x00 0x00 0x00 0x00 0x00 0x00 0x00 0x00 0x00 0x00 0x00 0x00 0x00 0x00 0x00 0x00 0x00 0x00 0x00 0x00 0x00 0x00 0x00 0x00 0x00 0x00 0x00 0x00 0x00 0x00 0x00 0x00 0x00 0x00 0x00 0x00 0x00 0x00 0x00 0x00 0x00 0x00 0x00 0x00 0x00 0x00 0x00 0x00 0x00 0x00 0x00 0x00 0x00 0x00 0x00 0x00 0x00 0x00 0x00 0x00 0x00 0x00 0x00 0x00 0x00 0x00 0x00 0x00 0x00 0x00 0x00 0x00 0x00 0x00 0x00 0x00 0x00 0x00 0x00 0x00 0x00 0x00 0x00 0x00 0x00 0x00 0x00 0x00 0x00 0x00 0x00 0x00 0x00 0x00 0x00 0x00 0x00 0x00 0x00 0x00 0x00 0x00 0x00 0x00 0x00 0x00 0x00 0x00 0x00 0x00 0x00 0x00 0x00 0x00 0x00 0x00 0x00 0x00 0x00 0x00 0x00 0x00 0x00 0x00 0x00 0x00 0x00 0x00 0x00 0x00 0x00 0x00 0x00 0x00 0x00 0x00 0x00 0x00 0x00 0x00 0x00 0x00 0x00 0x00 0x00 0x00 0x00 0x00 0x00 0x00 0x00 0x00 0x00 0x00 0x00 0x00 0x00 0x00 0x00 0x00 0x00 0x00 0x00 0x00 0x00 0x00 0x00 0x00 0x00 0x00 0x00 0x00 0x00 0x00 0x00 0x00 0x00 0x00 0x00 0x00 0x00 0x00 0x00 0x00 0x00 0x00 0x00 0x00 0x00 0x00 0x00 0x00 0x00 0x00 0x00 0x00 0x00 0x00 0x00 0x00 0x00 0x00 0x00 0x00 0x00 0x00 0x00 0x00 0x00 0x00 0x00 0x00 0x00 0x00 0x00 0x00 0x00 0x00 0x00 0x00 0x00 0x00 0x00 0x00 0x00 0x00 0x00 0x00 0x00 0x00 0x00 0x00 0x00 0x00 0x00 0x00 0x00 0x00 0x00 0x00 0x00 0x00 0x00 0x00 0x00 0x00 0x00 0x00 0x00 0x00 0x00 0x00 0x00 0x00 0x00 0x00 0x00 0x00 0x00 0x00 0x00 0x00 0x00 0x00 0x00 0x00 0x00 0x00 0x00 0x00 0x00 0x00 0x00 0x00 0x00 0x00 0x00 0x00 0x00 0x00 0x00 0x00 0x00 0x00 0x00 0x00 0x00 0x00 0x00 0x00 0x00 0x00 0x00>;
                PS_Config_Lmt_FW_CC_Q_P = <0x19 0x19 0x19 0x19 0x19 0x19 0x19 0x19 0x19 0x19 0x19 0x19 0x19 0x19 0x19 0x19 0x19 0x19 0x19 0x19 0x19 0x19 0x19 0x19 0x19 0x19 0x19 0x19 0x19 0x19 0x19 0x19 0x19 0x19 0x19 0x19 0x19 0x19 0x19 0x19 0x19 0x19 0x19 0x19 0x19 0x19 0x19 0x19 0x19 0x19 0x19 0x19 0x19 0x19 0x19 0x19 0x19 0x19 0x19 0x19 0x19 0x19 0x19 0x19 0x19 0x19 0x19 0x19 0x19 0x19 0x19 0x19 0x19 0x19 0x19 0x19 0x19 0x19 0x19 0x19 0x19 0x19 0x19 0x19 0x19 0x19 0x19 0x19 0x19 0x19 0x19 0x19 0x19 0x19 0x19 0x19 0x19 0x19 0x19 0x19 0x19 0x19 0x19 0x19 0x19 0x19 0x19 0x19 0x19 0x19 0x19 0x19 0x19 0x19 0x19 0x19 0x19 0x19 0x19 0x19 0x19 0x19 0x19 0x19 0x19 0x19 0x19 0x19 0x19 0x19 0x19 0x19 0x19 0x19 0x19 0x19 0x19 0x19 0x19 0x19 0x19 0x19 0x19 0x19 0x19 0x19 0x19 0x19 0x19 0x19 0x19 0x19 0x19 0x19 0x19 0x19 0x19 0x19 0x19 0x19 0x19 0x19 0x19 0x19 0x19 0x19 0x19 0x19 0x19 0x19 0x19 0x19 0x19 0x19 0x19 0x19 0x19 0x19 0x19 0x19 0x19 0x19 0x19 0x19 0x19 0x19 0x19 0x19 0x19 0x19 0x19 0x19 0x19 0x19 0x19 0x19 0x19 0x19 0x19 0x19 0x19 0x19 0x19 0x19 0x19 0x19 0x19 0x19 0x19 0x19 0x19 0x19 0x19 0x19 0x19 0x19 0x19 0x19 0x19 0x19 0x19 0x19 0x19 0x19 0x19 0x19 0x19 0x19 0x19 0x19 0x19 0x19 0x19 0x19 0x19 0x19 0x19 0x19 0x19 0x19 0x19 0x19 0x19 0x19 0x19 0x19 0x19 0x19 0x19 0x19 0x19 0x19 0x19 0x19 0x19 0x19 0x19 0x19 0x19 0x19 0x19 0x19 0x19 0x19 0x19 0x19 0x19 0x19 0x19 0x19 0x19 0x19 0x19 0x19 0x19 0x19 0x19 0x19 0x19 0x19 0x19 0x19 0x19 0x19 0x19 0x19 0x19 0x19 0x19 0x19 0x19 0x19 0x19 0x19 0x19 0x19 0x19 0x19 0x19 0x19 0x19 0x19 0x19 0x19 0x19 0x19 0x19 0x19 0x19 0x19 0x19 0x19 0x19 0x19 0x19 0x19 0x19 0x19 0x19 0x19 0x19 0x19 0x19 0x19 0x19 0x19 0x19 0x19 0x19 0x19 0x19 0x19 0x19 0x19 0x19 0x19 0x19 0x19 0x19 0x19 0x19 0x19 0x19 0x19 0x19 0x19 0x19 0x19 0x19 0x19 0x19 0x19 0x19 0x19 0x19 0x19 0x19 0x19 0x19 0x19 0x19 0x19 0x19 0x19 0x19 0x19 0x19 0x19 0x19 0x19 0x19 0x19 0x19 0x19 0x19 0x19 0x19 0x19 0x19 0x19 0x19 0x19 0x19 0x19 0x19 0x19 0x19 0x19 0x19 0x19 0x19 0x19 0x19 0x19 0x19 0x19 0x19 0x19 0x19 0x19 0x19 0x19 0x19 0x19 0x19 0x19 0x19 0x19 0x19 0x19 0x19 0x19 0x19 0x19 0x19 0x19 0x19 0x19 0x19 0x19 0x19 0x19 0x19 0x19 0x19 0x19 0x19 0x19 0x19 0x19 0x19 0x19 0x19 0x19 0x19 0x19 0x19 0x19 0x19 0x19 0x19 0x19 0x19 0x19 0x19 0x19 0x19 0x19 0x19 0x19 0x19 0x19 0x19 0x19 0x19 0x19 0x19 0x19 0x19 0x19 0x19 0x19 0x19 0x19 0x19 0x19 0x19 0x19 0x19 0x19 0x19 0x19 0x19 0x19 0x19 0x19 0x19 0x19 0x19 0x19 0x19 0x19 0x19 0x19 0x19 0x19 0x19 0x19 0x19 0x19 0x19 0x19 0x19 0x19 0x19 0x19 0x19 0x19 0x19 0x19 0x19 0x19 0x19 0x19 0x19 0x19 0x19 0x19 0x19 0x19 0x19 0x19 0x19 0x19 0x19 0x19 0x19 0x19 0x19 0x19 0x19 0x19 0x19 0x19 0x19 0x19 0x19 0x19 0x19 0x19 0x19 0x19 0x19 0x19 0x19 0x19 0x19 0x19 0x19 0x19 0x19 0x19 0x19 0x19 0x19 0x19 0x19 0x19 0x19 0x19 0x19 0x19 0x19 0x19 0x19 0x19 0x19 0x19 0x19 0x19 0x19 0x19 0x19 0x19 0x19 0x19 0x19 0x19 0x19 0x19 0x19 0x19 0x19 0x19 0x19 0x19 0x19 0x19 0x19>;
                PS_Config_Lmt_FW_CC_Q_N = <0x00 0x00 0x00 0x00 0x00 0x00 0x00 0x00 0x00 0x00 0x00 0x00 0x00 0x00 0x00 0x00 0x00 0x00 0x00 0x00 0x00 0x00 0x00 0x00 0x00 0x00 0x00 0x00 0x00 0x00 0x00 0x00 0x00 0x00 0x00 0x00 0x00 0x00 0x00 0x00 0x00 0x00 0x00 0x00 0x00 0x00 0x00 0x00 0x00 0x00 0x00 0x00 0x00 0x00 0x00 0x00 0x00 0x00 0x00 0x00 0x00 0x00 0x00 0x00 0x00 0x00 0x00 0x00 0x00 0x00 0x00 0x00 0x00 0x00 0x00 0x00 0x00 0x00 0x00 0x00 0x00 0x00 0x00 0x00 0x00 0x00 0x00 0x00 0x00 0x00 0x00 0x00 0x00 0x00 0x00 0x00 0x00 0x00 0x00 0x00 0x00 0x00 0x00 0x00 0x00 0x00 0x00 0x00 0x00 0x00 0x00 0x00 0x00 0x00 0x00 0x00 0x00 0x00 0x00 0x00 0x00 0x00 0x00 0x00 0x00 0x00 0x00 0x00 0x00 0x00 0x00 0x00 0x00 0x00 0x00 0x00 0x00 0x00 0x00 0x00 0x00 0x00 0x00 0x00 0x00 0x00 0x00 0x00 0x00 0x00 0x00 0x00 0x00 0x00 0x00 0x00 0x00 0x00 0x00 0x00 0x00 0x00 0x00 0x00 0x00 0x00 0x00 0x00 0x00 0x00 0x00 0x00 0x00 0x00 0x00 0x00 0x00 0x00 0x00 0x00 0x00 0x00 0x00 0x00 0x00 0x00 0x00 0x00 0x00 0x00 0x00 0x00 0x00 0x00 0x00 0x00 0x00 0x00 0x00 0x00 0x00 0x00 0x00 0x00 0x00 0x00 0x00 0x00 0x00 0x00 0x00 0x00 0x00 0x00 0x00 0x00 0x00 0x00 0x00 0x00 0x00 0x00 0x00 0x00 0x00 0x00 0x00 0x00 0x00 0x00 0x00 0x00 0x00 0x00 0x00 0x00 0x00 0x00 0x00 0x00 0x00 0x00 0x00 0x00 0x00 0x00 0x00 0x00 0x00 0x00 0x00 0x00 0x00 0x00 0x00 0x00 0x00 0x00 0x00 0x00 0x00 0x00 0x00 0x00 0x00 0x00 0x00 0x00 0x00 0x00 0x00 0x00 0x00 0x00 0x00 0x00 0x00 0x00 0x00 0x00 0x00 0x00 0x00 0x00 0x00 0x00 0x00 0x00 0x00 0x00 0x00 0x00 0x00 0x00 0x00 0x00 0x00 0x00 0x00 0x00 0x00 0x00 0x00 0x00 0x00 0x00 0x00 0x00 0x00 0x00 0x00 0x00 0x00 0x00 0x00 0x00 0x00 0x00 0x00 0x00 0x00 0x00 0x00 0x00 0x00 0x00 0x00 0x00 0x00 0x00 0x00 0x00 0x00 0x00 0x00 0x00 0x00 0x00 0x00 0x00 0x00 0x00 0x00 0x00 0x00 0x00 0x00 0x00 0x00 0x00 0x00 0x00 0x00 0x00 0x00 0x00 0x00 0x00 0x00 0x00 0x00 0x00 0x00 0x00 0x00 0x00 0x00 0x00 0x00 0x00 0x00 0x00 0x00 0x00 0x00 0x00 0x00 0x00 0x00 0x00 0x00 0x00 0x00 0x00 0x00 0x00 0x00 0x00 0x00 0x00 0x00 0x00 0x00 0x00 0x00 0x00 0x00 0x00 0x00 0x00 0x00 0x00 0x00 0x00 0x00 0x00 0x00 0x00 0x00 0x00 0x00 0x00 0x00 0x00 0x00 0x00 0x00 0x00 0x00 0x00 0x00 0x00 0x00 0x00 0x00 0x00 0x00 0x00 0x00 0x00 0x00 0x00 0x00 0x00 0x00 0x00 0x00 0x00 0x00 0x00 0x00 0x00 0x00 0x00 0x00 0x00 0x00 0x00 0x00 0x00 0x00 0x00 0x00 0x00 0x00 0x00 0x00 0x00 0x00 0x00 0x00 0x00 0x00 0x00 0x00 0x00 0x00 0x00 0x00 0x00 0x00 0x00 0x00 0x00 0x00 0x00 0x00 0x00 0x00 0x00 0x00 0x00 0x00 0x00 0x00 0x00 0x00 0x00 0x00 0x00 0x00 0x00 0x00 0x00 0x00 0x00 0x00 0x00 0x00 0x00 0x00 0x00 0x00 0x00 0x00 0x00 0x00 0x00 0x00 0x00 0x00 0x00 0x00 0x00 0x00 0x00 0x00 0x00 0x00 0x00 0x00 0x00 0x00 0x00 0x00 0x00 0x00 0x00 0x00 0x00 0x00 0x00 0x00 0x00 0x00 0x00 0x00 0x00 0x00 0x00 0x00 0x00 0x00 0x00 0x00 0x00 0x00 0x00 0x00 0x00 0x00 0x00 0x00 0x00 0x00 0x00 0x00 0x00 0x00 0x00 0x00 0x00 0x00 0x00 0x00 0x00 0x00 0x00 0x00 0x00 0x00 0x00 0x00 0x00 0x00 0x00 0x00 0x00 0x00>;
                PS_Config_Lmt_FW_Diff_P = <0x32 0x32 0x32 0x32 0x32 0xffff 0xffff 0xffff 0xffff 0xffff 0xffff 0xffff 0xffff 0x32 0x32 0x32 0x32 0x32 0x32 0x32 0x32 0x32 0x32 0x32 0x32 0x32 0x32 0x32 0x32 0x32 0x32 0x32 0x32 0x32 0x32 0x32 0x32 0x32 0x32 0x32 0x32 0x32 0x32 0x32 0x32 0x32 0x32 0x32 0x32 0x32 0x32 0x32 0x32 0x32 0x32 0x32 0x32 0x32 0x32 0x32 0x32 0x32 0x32 0x32 0x32 0x32 0x32 0x32 0x32 0x32 0x32 0x32 0x32 0x32 0x32 0x32 0x32 0x32 0x32 0x32 0x32 0x32 0x32 0x32 0x32 0x32 0x32 0x32 0x32 0x32 0x32 0x32 0x32 0x32 0x32 0x32 0x32 0x32 0x32 0x32 0x32 0x32 0x32 0x32 0x32 0x32 0x32 0x32 0x32 0x32 0x32 0x32 0x32 0x32 0x32 0x32 0x32 0x32 0x32 0x32 0x32 0x32 0x32 0x32 0x32 0x32 0x32 0x32 0x32 0x32 0x32 0x32 0x32 0x32 0x32 0x32 0x32 0x32 0x32 0x32 0x32 0x32 0x32 0x32 0x32 0x32 0x32 0x32 0x32 0x32 0x32 0x32 0x32 0x32 0x32 0x32 0x32 0x32 0x32 0x32 0x32 0x32 0x32 0x32 0x32 0x32 0x32 0x32 0x32 0x32 0x32 0x32 0x32 0x32 0x32 0x32 0x32 0x32 0x32 0x32 0x32 0x32 0x32 0x32 0x32 0x32 0x32 0x32 0x32 0x32 0x32 0x32 0x32 0x32 0x32 0x32 0x32 0x32 0x32 0x32 0x32 0x32 0x32 0x32 0x32 0x32 0x32 0x32 0x32 0x32 0x32 0x32 0x32 0x32 0x32 0x32 0x32 0x32 0x32 0x32 0x32 0x32 0x32 0x32 0x32 0x32 0x32 0x32 0x32 0x32 0x32 0x32 0x32 0x32 0x32 0x32 0x32 0x32 0x32 0x32 0x32 0x32 0x32 0x32 0x32 0x32 0x32 0x32 0x32 0x32 0x32 0x32 0x32 0x32 0x32 0x32 0x32 0x32 0x32 0x32 0x32 0x32 0x32 0x32 0x32 0x32 0x32 0x32 0x32 0x32 0x32 0x32 0x32 0x32 0x32 0x32 0x32 0x32 0x32 0x32 0x32 0x32 0x32 0x32 0x32 0x32 0x32 0x32 0x32 0x32 0x32 0x32 0x32 0x32 0x32 0x32 0x32 0x32 0x32 0x32 0x32 0x32 0x32 0x32 0x32 0x32 0x32 0x32 0x32 0x32 0x32 0x32 0x32 0x32 0x32 0x32 0x32 0x32 0x32 0x32 0x32 0x32 0x32 0x32 0x32 0x32 0x32 0x32 0x32 0x32 0x32 0x32 0x32 0x32 0x32 0x32 0x32 0x32 0x32 0x32 0x32 0x32 0x32 0x32 0x32 0x32 0x32 0x32 0x32 0x32 0x32 0x32 0x32 0x32 0x32 0x32 0x32 0x32 0x32 0x32 0x32 0x32 0x32 0x32 0x32 0x32 0x32 0x32 0x32 0x32 0x32 0x32 0x32 0x32 0x32 0x32 0x32 0x32 0x32 0x32 0x32 0x32 0x32 0x32 0x32 0x32 0x32 0x32 0x32 0x32 0x32 0x32 0x32 0x32 0x32 0x32 0x32 0x32 0x32 0x32 0x32 0x32 0x32 0x32 0x32 0x32 0x32 0x32 0x32 0x32 0x32 0x32 0x32 0x32 0x32 0x32 0x32 0x32 0x32 0x32 0x32 0x32 0x32 0x32 0x32 0x32 0x32 0x32 0x32 0x32 0x32 0x32 0x32 0x32 0x32 0x32 0x32 0x32 0x32 0x32 0x32 0x32 0x32 0x32 0x32 0x32 0x32 0x32 0x32 0x32 0x32 0x32 0x32 0x32 0x32 0x32 0x32 0x32 0x32 0x32 0x32 0x32 0x32 0x32 0x32 0x32 0x32 0x32 0x32 0x32 0x32 0x32 0x32 0x32 0x32 0x32 0x32 0x32 0x32 0x32 0x32 0x32 0x32 0x32 0x32 0x32 0x32 0x32 0x32 0x32 0x32 0x32 0x32 0x32 0x32 0x32 0x32 0x32 0x32 0x32 0x32 0x32 0x32 0x32 0x32 0x32 0x32 0x32 0x32 0x32 0x32 0x32 0x32 0x32 0x32 0x32 0x32 0x32 0x32 0x32 0x32 0x32 0x32 0x32 0x32 0x32 0x32 0x32 0x32 0x32 0x32 0x32 0x32 0x32 0x32 0x32 0x32 0x32 0x32 0x32 0x32 0x32 0x32 0x32 0x32 0x32 0x32 0x32 0x32 0x32 0x32 0x32 0x32 0x32 0x32 0x32 0x32 0x32 0x32 0x32 0x32 0x32 0x32 0x32 0x32 0x32 0x32 0x32 0x32 0x32 0x32 0x32 0x32 0x32 0x32 0x32 0x32 0x32 0x32 0x32 0x32 0x32 0x32 0x32 0x32 0x32 0x32 0x32 0x32 0x32 0x32 0x32 0x32 0x32 0x32 0x32 0x32 0x32 0x32 0x32 0x32 0x32 0x32 0x32 0x32 0x32 0x32 0x32 0x32 0x32 0x32 0x32 0x32 0x32 0x32 0x32 0x32 0x32 0x32 0x32 0x32 0x32 0x32 0x32 0x32 0x32 0x32 0x32 0x32 0x32 0x32 0x32 0x32 0x32 0x32 0x32 0x32 0x32 0x32 0x32 0x32 0x32 0x32 0x32 0x32 0x32 0x32 0x32 0x23 0x23 0x23>;
                PS_Config_Lmt_FW_Diff_N = <0xffffffce 0xffffffce 0xffffffce 0xffffffce 0xffffffce 0xffff0001 0xffff0001 0xffff0001 0xffff0001 0xffff0001 0xffff0001 0xffff0001 0xffff0001 0xffffffce 0xffffffce 0xffffffce 0xffffffce 0xffffffce 0xffffffce 0xffffffce 0xffffffce 0xffffffce 0xffffffce 0xffffffce 0xffffffce 0xffffffce 0xffffffce 0xffffffce 0xffffffce 0xffffffce 0xffffffce 0xffffffce 0xffffffce 0xffffffce 0xffffffce 0xffffffce 0xffffffce 0xffffffce 0xffffffce 0xffffffce 0xffffffce 0xffffffce 0xffffffce 0xffffffce 0xffffffce 0xffffffce 0xffffffce 0xffffffce 0xffffffce 0xffffffce 0xffffffce 0xffffffce 0xffffffce 0xffffffce 0xffffffce 0xffffffce 0xffffffce 0xffffffce 0xffffffce 0xffffffce 0xffffffce 0xffffffce 0xffffffce 0xffffffce 0xffffffce 0xffffffce 0xffffffce 0xffffffce 0xffffffce 0xffffffce 0xffffffce 0xffffffce 0xffffffce 0xffffffce 0xffffffce 0xffffffce 0xffffffce 0xffffffce 0xffffffce 0xffffffce 0xffffffce 0xffffffce 0xffffffce 0xffffffce 0xffffffce 0xffffffce 0xffffffce 0xffffffce 0xffffffce 0xffffffce 0xffffffce 0xffffffce 0xffffffce 0xffffffce 0xffffffce 0xffffffce 0xffffffce 0xffffffce 0xffffffce 0xffffffce 0xffffffce 0xffffffce 0xffffffce 0xffffffce 0xffffffce 0xffffffce 0xffffffce 0xffffffce 0xffffffce 0xffffffce 0xffffffce 0xffffffce 0xffffffce 0xffffffce 0xffffffce 0xffffffce 0xffffffce 0xffffffce 0xffffffce 0xffffffce 0xffffffce 0xffffffce 0xffffffce 0xffffffce 0xffffffce 0xffffffce 0xffffffce 0xffffffce 0xffffffce 0xffffffce 0xffffffce 0xffffffce 0xffffffce 0xffffffce 0xffffffce 0xffffffce 0xffffffce 0xffffffce 0xffffffce 0xffffffce 0xffffffce 0xffffffce 0xffffffce 0xffffffce 0xffffffce 0xffffffce 0xffffffce 0xffffffce 0xffffffce 0xffffffce 0xffffffce 0xffffffce 0xffffffce 0xffffffce 0xffffffce 0xffffffce 0xffffffce 0xffffffce 0xffffffce 0xffffffce 0xffffffce 0xffffffce 0xffffffce 0xffffffce 0xffffffce 0xffffffce 0xffffffce 0xffffffce 0xffffffce 0xffffffce 0xffffffce 0xffffffce 0xffffffce 0xffffffce 0xffffffce 0xffffffce 0xffffffce 0xffffffce 0xffffffce 0xffffffce 0xffffffce 0xffffffce 0xffffffce 0xffffffce 0xffffffce 0xffffffce 0xffffffce 0xffffffce 0xffffffce 0xffffffce 0xffffffce 0xffffffce 0xffffffce 0xffffffce 0xffffffce 0xffffffce 0xffffffce 0xffffffce 0xffffffce 0xffffffce 0xffffffce 0xffffffce 0xffffffce 0xffffffce 0xffffffce 0xffffffce 0xffffffce 0xffffffce 0xffffffce 0xffffffce 0xffffffce 0xffffffce 0xffffffce 0xffffffce 0xffffffce 0xffffffce 0xffffffce 0xffffffce 0xffffffce 0xffffffce 0xffffffce 0xffffffce 0xffffffce 0xffffffce 0xffffffce 0xffffffce 0xffffffce 0xffffffce 0xffffffce 0xffffffce 0xffffffce 0xffffffce 0xffffffce 0xffffffce 0xffffffce 0xffffffce 0xffffffce 0xffffffce 0xffffffce 0xffffffce 0xffffffce 0xffffffce 0xffffffce 0xffffffce 0xffffffce 0xffffffce 0xffffffce 0xffffffce 0xffffffce 0xffffffce 0xffffffce 0xffffffce 0xffffffce 0xffffffce 0xffffffce 0xffffffce 0xffffffce 0xffffffce 0xffffffce 0xffffffce 0xffffffce 0xffffffce 0xffffffce 0xffffffce 0xffffffce 0xffffffce 0xffffffce 0xffffffce 0xffffffce 0xffffffce 0xffffffce 0xffffffce 0xffffffce 0xffffffce 0xffffffce 0xffffffce 0xffffffce 0xffffffce 0xffffffce 0xffffffce 0xffffffce 0xffffffce 0xffffffce 0xffffffce 0xffffffce 0xffffffce 0xffffffce 0xffffffce 0xffffffce 0xffffffce 0xffffffce 0xffffffce 0xffffffce 0xffffffce 0xffffffce 0xffffffce 0xffffffce 0xffffffce 0xffffffce 0xffffffce 0xffffffce 0xffffffce 0xffffffce 0xffffffce 0xffffffce 0xffffffce 0xffffffce 0xffffffce 0xffffffce 0xffffffce 0xffffffce 0xffffffce 0xffffffce 0xffffffce 0xffffffce 0xffffffce 0xffffffce 0xffffffce 0xffffffce 0xffffffce 0xffffffce 0xffffffce 0xffffffce 0xffffffce 0xffffffce 0xffffffce 0xffffffce 0xffffffce 0xffffffce 0xffffffce 0xffffffce 0xffffffce 0xffffffce 0xffffffce 0xffffffce 0xffffffce 0xffffffce 0xffffffce 0xffffffce 0xffffffce 0xffffffce 0xffffffce 0xffffffce 0xffffffce 0xffffffce 0xffffffce 0xffffffce 0xffffffce 0xffffffce 0xffffffce 0xffffffce 0xffffffce 0xffffffce 0xffffffce 0xffffffce 0xffffffce 0xffffffce 0xffffffce 0xffffffce 0xffffffce 0xffffffce 0xffffffce 0xffffffce 0xffffffce 0xffffffce 0xffffffce 0xffffffce 0xffffffce 0xffffffce 0xffffffce 0xffffffce 0xffffffce 0xffffffce 0xffffffce 0xffffffce 0xffffffce 0xffffffce 0xffffffce 0xffffffce 0xffffffce 0xffffffce 0xffffffce 0xffffffce 0xffffffce 0xffffffce 0xffffffce 0xffffffce 0xffffffce 0xffffffce 0xffffffce 0xffffffce 0xffffffce 0xffffffce 0xffffffce 0xffffffce 0xffffffce 0xffffffce 0xffffffce 0xffffffce 0xffffffce 0xffffffce 0xffffffce 0xffffffce 0xffffffce 0xffffffce 0xffffffce 0xffffffce 0xffffffce 0xffffffce 0xffffffce 0xffffffce 0xffffffce 0xffffffce 0xffffffce 0xffffffce 0xffffffce 0xffffffce 0xffffffce 0xffffffce 0xffffffce 0xffffffce 0xffffffce 0xffffffce 0xffffffce 0xffffffce 0xffffffce 0xffffffce 0xffffffce 0xffffffce 0xffffffce 0xffffffce 0xffffffce 0xffffffce 0xffffffce 0xffffffce 0xffffffce 0xffffffce 0xffffffce 0xffffffce 0xffffffce 0xffffffce 0xffffffce 0xffffffce 0xffffffce 0xffffffce 0xffffffce 0xffffffce 0xffffffce 0xffffffce 0xffffffce 0xffffffce 0xffffffce 0xffffffce 0xffffffce 0xffffffce 0xffffffce 0xffffffce 0xffffffce 0xffffffce 0xffffffce 0xffffffce 0xffffffce 0xffffffce 0xffffffce 0xffffffce 0xffffffce 0xffffffce 0xffffffce 0xffffffce 0xffffffce 0xffffffce 0xffffffce 0xffffffce 0xffffffce 0xffffffce 0xffffffce 0xffffffce 0xffffffce 0xffffffce 0xffffffce 0xffffffce 0xffffffce 0xffffffce 0xffffffce 0xffffffce 0xffffffce 0xffffffce 0xffffffce 0xffffffce 0xffffffce 0xffffffce 0xffffffce 0xffffffce 0xffffffce 0xffffffce 0xffffffce 0xffffffce 0xffffffce 0xffffffce 0xffffffce 0xffffffce 0xffffffce 0xffffffce 0xffffffce 0xffffffce 0xffffffce 0xffffffce 0xffffffce 0xffffffce 0xffffffce 0xffffffce 0xffffffce 0xffffffce 0xffffffce 0xffffffce 0xffffffce 0xffffffce 0xffffffce 0xffffffce 0xffffffce 0xffffffce 0xffffffce 0xffffffce 0xffffffce 0xffffffce 0xffffffce 0xffffffce 0xffffffce 0xffffffce 0xffffffce 0xffffffce 0xffffffce 0xffffffce 0xffffffce 0xffffffce 0xffffffce 0xffffffce 0xffffffce 0xffffffce 0xffffffce 0xffffffce 0xffffffce 0xffffffce 0xffffffce 0xffffffce 0xffffffce 0xffffffce 0xffffffce 0xffffffce 0xffffffce 0xffffffce 0xffffffce 0xffffffce 0xffffffce 0xffffffce 0xffffffce 0xffffffce 0xffffffce 0xffffffce 0xffffffce 0xffffffce 0xffffffce 0xffffffce 0xffffffce 0xffffffce 0xffffffce 0xffffffce 0xffffffce 0xffffffce 0xffffffce 0xffffffce 0xffffffce 0xffffffce 0xffffffce 0xffffffce 0xffffffce 0xffffffce 0xffffffce 0xffffffce 0xffffffce 0xffffffce 0xffffffce 0xffffffce 0xffffffce 0xffffffce 0xffffffce 0xffffffce 0xffffffce 0xffffffce 0xffffffce 0xffffffce 0xffffffce 0xffffffce 0xffffffce 0xffffffce 0xffffffce 0xffffffce 0xffffffce 0xffffffce 0xffffffce 0xffffffce 0xffffffce 0xffffffce 0xffffffce 0xffffffce 0xffffffce 0xffffffce 0xffffffce 0xffffffce 0xffffffce 0xffffffce 0xffffffce 0xffffffce 0xffffffce 0xffffffce 0xffffffce 0xffffffce 0xffffffce 0xffffffce 0xffffffce 0xffffffce 0xffffffce 0xffffffce 0xffffffce 0xffffffce 0xffffffce 0xffffffce 0xffffffce 0xffffffce 0xffffffce 0xffffffce 0xffffffce 0xffffffce 0xffffffce 0xffffffce 0xffffffce 0xffffffce 0xffffffce 0xffffffce 0xffffffce 0xffffffce 0xffffffce 0xffffffce 0xffffffce 0xffffffce 0xffffffce 0xffffffce 0xffffffce 0xffffffdd 0xffffffdd 0xffffffdd>;
                PS_Config_Diff_Test_Frame = <0x32>;
            };
        };
}

&qupv3_se8_i2c {
    status = "okay";

    semtech@28 {
        compatible = "Semtech,sx9310";
        reg = <0x28>;
        vdd-supply = <&pm660l_l3>;
        vdd1-supply = <&pm660_l13>;
        Semtech,gpio-irq = <&tlmm 0x74 0x2008>;
        interrupt-parent = <&tlmm>;
        interrupts = <0x74 0x02>;
        pinctrl-names = "sarsensor_active", "sarsensor_suspend";
        pinctrl-0 = <&sarsensor_int_active>;
        pinctrl-1 = <&sarsensor_int_suspend>;
    };
}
